VERSION "HNNBNNNYNNNNNNNNNNNNNNNNNNNNNNNNNNNNNNNNNN/4/%%%/4/'%**4NNN///"

NS_ :

BS_:

BU_: Airbag Allrad_Haldex BAP_Tester DCC_Gen3 EBKV_MQBW ESC_MQBW Gateway_Max Lenkhilfe_REPS

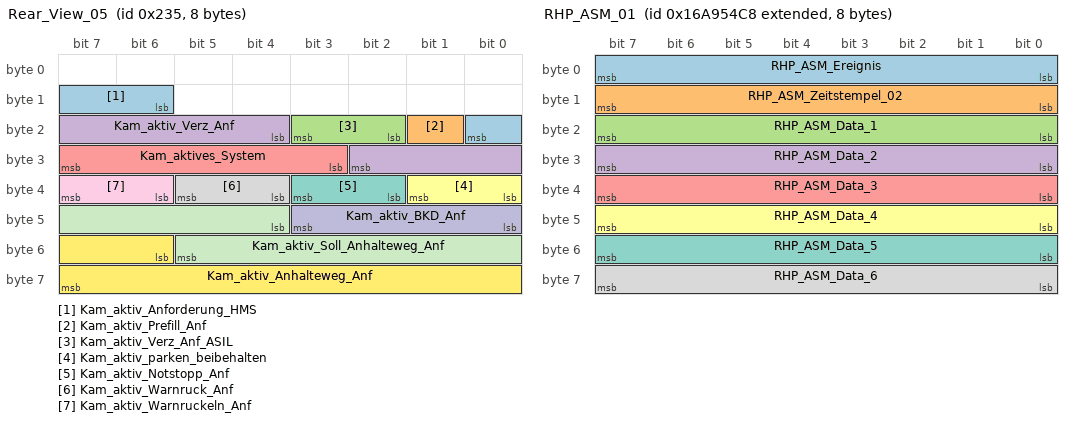
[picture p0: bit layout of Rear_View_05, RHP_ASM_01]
BO_ 565 Rear_View_05: 8 Gateway_Max
 SG_ Kam_aktiv_Anforderung_HMS : 14|3@1+ (1.0,0.0) [0.0|7] ""  Vector__XXX
 SG_ Kam_aktiv_Prefill_Anf : 17|1@1+ (1.0,0.0) [0.0|1] ""  Vector__XXX
 SG_ Kam_aktiv_Verz_Anf_ASIL : 18|2@1+ (1.0,0.0) [0.0|3] ""  ESC_MQBW
 SG_ Kam_aktiv_Verz_Anf : 20|7@1+ (0.1,-12.6) [-12.6|-0.1] "Unit_MeterPerSeconSquar"  ESC_MQBW
 SG_ Kam_aktives_System : 27|5@1+ (1.0,0.0) [0.0|31] ""  Vector__XXX
 SG_ Kam_aktiv_parken_beibehalten : 32|2@1+ (1.0,0.0) [0.0|3] ""  Vector__XXX
 SG_ Kam_aktiv_Notstopp_Anf : 34|2@1+ (1.0,0.0) [0.0|3] ""  Vector__XXX
 SG_ Kam_aktiv_Warnruck_Anf : 36|2@1+ (1.0,0.0) [0.0|3] ""  Vector__XXX
 SG_ Kam_aktiv_Warnruckeln_Anf : 38|2@1+ (1.0,0.0) [0.0|3] ""  Vector__XXX
 SG_ Kam_aktiv_BKD_Anf : 40|4@1+ (0.1,0) [0.0|1.3] "Unit_Secon"  Vector__XXX
 SG_ Kam_aktiv_Soll_Anhalteweg_Anf : 44|10@1+ (0.01,0) [0.00|10.21] "Unit_Meter"  Vector__XXX
 SG_ Kam_aktiv_Anhalteweg_Anf : 54|10@1+ (0.01,0) [0.00|10.21] "Unit_Meter"  Vector__XXX

BO_ 2033 Request_Airbag_Deployment: 8 Gateway_Max
 SG_ Request_Airbag_Deployment : 0|64@1+ (1.0,0.0) [0.0|18446744073709551615] ""  Airbag

BO_ 2041 Response_Airbag_Deployment: 8 Airbag
 SG_ Response_Airbag_Deployment : 0|64@1+ (1.0,0.0) [0.0|18446744073709551615] ""  Gateway_Max

BO_ 2264486920 RHP_01: 32 Gateway_Max
 SG_ RHP_01_CRC : 0|8@1+ (1,0) [0|255] ""  ESC_MQBW,Lenkhilfe_REPS
 SG_ RHP_01_BZ : 8|4@1+ (1,0) [0|15] ""  ESC_MQBW,Lenkhilfe_REPS
 SG_ RHP_QFK_AnfStat : 12|4@1+ (1.0,0.0) [0.0|15] ""  Lenkhilfe_REPS
 SG_ RHP_QFK_Spuerb : 16|8@1+ (0.4,0) [0.0|100.0] "Unit_PerCent"  Lenkhilfe_REPS
 SG_ RHP_QFK_KruemmSoll : 24|15@1+ (0.0000067,0) [0E-7|0.2195389] "Unit_MeterInver"  Lenkhilfe_REPS
 SG_ RHP_TV_Trigger : 39|1@1+ (1.0,0.0) [0.0|1] ""  Vector__XXX
 SG_ RHP_QFK_Signal1 : 40|10@1+ (1,0) [0|1023] ""  Lenkhilfe_REPS
 SG_ RHP_QFK_Art1 : 50|3@1+ (1,0) [0|7] ""  Lenkhilfe_REPS
 SG_ RHP_QFK_Art2 : 53|3@1+ (1,0) [0|7] ""  Lenkhilfe_REPS
 SG_ RHP_QFK_Signal2 : 56|10@1+ (1,0) [0|1023] ""  Lenkhilfe_REPS
 SG_ RHP_QFK_KruemmSoll_VZ : 66|1@1+ (1.0,0.0) [0.0|1] ""  Lenkhilfe_REPS
 SG_ RHP_Status_Long : 67|3@1+ (1.0,0.0) [0.0|7] ""  Vector__XXX
 SG_ RHP_Ruckfreigabe : 70|1@1+ (1.0,0.0) [0.0|1] ""  ESC_MQBW
 SG_ RHP_Warnruckeln_Anf : 71|3@1+ (1.0,0.0) [0.0|7] ""  ESC_MQBW
 SG_ RHP_Anf_ASIL : 74|3@1+ (1.0,0.0) [0.0|7] ""  ESC_MQBW
 SG_ RHP_Anforderung_HMS : 77|3@1+ (1.0,0.0) [0.0|7] ""  ESC_MQBW
 SG_ RHP_pos_Sollbeschl_Grad : 80|8@1+ (0.05,0) [0.00|12.75] "Unit_MeterPerCubicSecon"  Vector__XXX
 SG_ RHP_neg_Sollbeschl_Grad : 88|8@1+ (0.05,0) [0.00|12.75] "Unit_MeterPerCubicSecon"  Vector__XXX
 SG_ RHP_Sollbeschleunigung : 96|11@1+ (0.005,-7.22) [-7.220|3.005] "Unit_MeterPerSeconSquar"  Vector__XXX
 SG_ RHP_zul_Regelabw_oben : 107|5@1+ (0.0625,0) [0.0000|1.9375] "Unit_MeterPerSeconSquar"  Vector__XXX
 SG_ RHP_zul_Regelabw_unten : 112|6@1+ (0.024,0) [0.000|1.512] "Unit_MeterPerSeconSquar"  Vector__XXX
 SG_ RHP_TSK_Status : 118|3@1+ (1.0,0.0) [0.0|7] ""  Vector__XXX
 SG_ RHP_Minimale_Bremsung : 121|1@1+ (1.0,0.0) [0.0|1] ""  Vector__XXX
 SG_ RHP_Uss_Anforderung : 122|2@1+ (1.0,0.0) [0.0|3] ""  Vector__XXX
 SG_ RHP_Verz_Anf : 124|10@1+ (0.024,-20.016) [-20.016|4.512] "Unit_MeterPerSeconSquar"  ESC_MQBW
 SG_ RHP_Verz_Freigabe : 134|1@1+ (1.0,0.0) [0.0|1] ""  ESC_MQBW
 SG_ RHP_Status_Lat : 135|3@1+ (1.0,0.0) [0.0|7] ""  Vector__XXX
 SG_ RHP_StartStopp_Info : 138|2@1+ (1.0,0.0) [0.0|3] ""  Vector__XXX
 SG_ RHP_nachtr_Stopp_Anf : 140|1@1+ (1.0,0.0) [0.0|1] ""  Vector__XXX
 SG_ RHP_Freilaufstrategie_TSK : 141|1@1+ (1.0,0.0) [0.0|1] ""  Vector__XXX
 SG_ RHP_SCAM_HeatingRequest : 142|2@1+ (1.0,0.0) [0.0|3] ""  Vector__XXX
 SG_ RHP_Fahrzeughupe_Anf : 144|1@1+ (1.0,0.0) [0.0|1] ""  Vector__XXX
 SG_ RHP_HOS : 145|2@1+ (1.0,0.0) [0.0|3] ""  Vector__XXX
 SG_ RHP_Status_Function : 147|3@1+ (1.0,0.0) [0.0|7] ""  Vector__XXX
 SG_ RHP_EA_AnfStat : 150|2@1+ (1.0,0.0) [0.0|3] ""  Vector__XXX
 SG_ RHP_QFK_KrSoll : 152|16@1+ (0.0000067,0) [0E-7|0.4390845] "Unit_MeterInver"  Lenkhilfe_REPS
 SG_ RHP_QFK_KrSoll_VZ : 168|1@1+ (1.0,0.0) [0.0|1] ""  Lenkhilfe_REPS
 SG_ RHP_Warnblinken : 169|1@1+ (1.0,0.0) [0.0|1] ""  Vector__XXX
 SG_ RHP_Innenraumlicht_Anf : 170|1@1+ (1.0,0.0) [0.0|1] ""  Vector__XXX
 SG_ RHP_Spurwechsel_Ready : 171|3@1+ (1.0,0.0) [0.0|7] ""  Vector__XXX
 SG_ RHP_RBF_Available : 174|2@1+ (1.0,0.0) [0.0|3] ""  Vector__XXX
 SG_ RHP_PreCrash_Anf : 176|3@1+ (1.0,0.0) [0.0|7] ""  Airbag
 SG_ RHP_EA_PreCrash : 179|3@1+ (1.0,0.0) [0.0|7] ""  Vector__XXX
 SG_ RHP_Parking_St : 182|2@1+ (1.0,0.0) [0.0|3] ""  Vector__XXX
 SG_ RHP_EA_Innenraumlicht : 184|1@1+ (1.0,0.0) [0.0|1] ""  Vector__XXX
 SG_ RHP_EA_eCall : 185|1@1+ (1.0,0.0) [0.0|1] ""  Vector__XXX
 SG_ RHP_OPSEnable : 186|2@1+ (1.0,0.0) [0.0|3] ""  Vector__XXX
 SG_ RHP_eCall_Anf : 188|1@1+ (1.0,0.0) [0.0|1] ""  Vector__XXX
 SG_ RHP_EA_Tueren : 189|1@1+ (1.0,0.0) [0.0|1] ""  Vector__XXX

BO_ 2527679688 RHP_ASM_01: 8 Gateway_Max
 SG_ RHP_ASM_Ereignis : 0|8@1+ (1,0) [1|254] ""  Airbag
 SG_ RHP_ASM_Zeitstempel_02 : 8|8@1+ (0.04,0) [0.00|10.16] "Unit_Secon"  Airbag
 SG_ RHP_ASM_Data_1 : 16|8@1+ (1,0) [0|255] "Unit_None"  Airbag
 SG_ RHP_ASM_Data_2 : 24|8@1+ (1,0) [0|255] "Unit_None"  Airbag
 SG_ RHP_ASM_Data_3 : 32|8@1+ (1,0) [0|255] "Unit_None"  Airbag
 SG_ RHP_ASM_Data_4 : 40|8@1+ (1,0) [0|255] "Unit_None"  Airbag
 SG_ RHP_ASM_Data_5 : 48|8@1+ (1,0) [0|255] "Unit_None"  Airbag
 SG_ RHP_ASM_Data_6 : 56|8@1+ (1,0) [0|255] "Unit_None"  Airbag

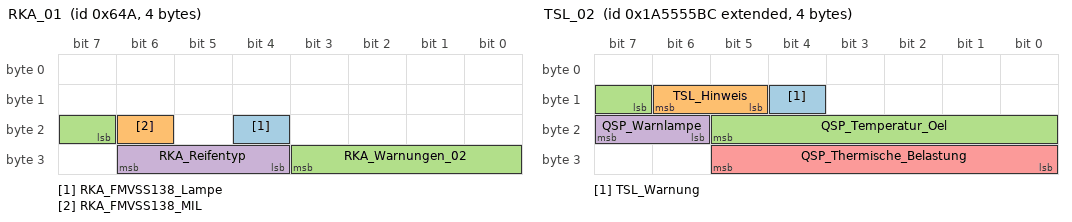
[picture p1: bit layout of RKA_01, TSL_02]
BO_ 1610 RKA_01: 4 ESC_MQBW
 SG_ RKA_FMVSS138_Lampe : 20|1@1+ (1.0,0.0) [0.0|1] ""  Airbag,Gateway_Max
 SG_ RKA_FMVSS138_MIL : 22|1@1+ (1,0) [0|1] ""  Airbag,Gateway_Max
 SG_ RKA_Warnungen_02 : 23|5@1+ (1.0,0.0) [0.0|31] ""  Gateway_Max
 SG_ RKA_Reifentyp : 28|3@1+ (1.0,0.0) [0.0|7] ""  Gateway_Max

BO_ 2589283756 SOK_NoAuthenticTime_01: 8 Gateway_Max
 SG_ SOK_ungeschuetzte_Zeit : 8|56@1+ (1,0) [1|72057594037927935] "Unit_None"  Airbag,EBKV_MQBW,ESC_MQBW

BO_ 2464153619 SOK_Zeit_ABS_Chal_01: 8 ESC_MQBW
 SG_ SOK_Zeit_ABS_Challenge : 0|64@1+ (1,0) [0|18446744073709551615] "Unit_None"  Gateway_Max

BO_ 2464284691 SOK_Zeit_ABS_Resp_01: 16 Gateway_Max
 SG_ SOK_Zeit_ABS_Zeit : 0|56@1+ (1,0) [0|72057594037927935] "Unit_None"  ESC_MQBW
 SG_ SOK_Zeit_ABS_Signatur : 64|64@1+ (1,0) [0|18446744073709551615] "Unit_None"  ESC_MQBW

BO_ 2464153621 SOK_Zeit_Airbag_Chal_01: 8 Airbag
 SG_ SOK_Zeit_Airbag_Challenge : 0|64@1+ (1,0) [0|18446744073709551615] "Unit_None"  Gateway_Max

BO_ 2464284693 SOK_Zeit_Airbag_Resp_01: 16 Gateway_Max
 SG_ SOK_Zeit_Airbag_Zeit : 0|56@1+ (1,0) [0|72057594037927935] "Unit_None"  Airbag
 SG_ SOK_Zeit_Airbag_Signatur : 64|64@1+ (1,0) [0|18446744073709551615] ""  Airbag

BO_ 2464153659 SOK_Zeit_EBKV_Chal_01: 8 EBKV_MQBW
 SG_ SOK_Zeit_EBKV_Challenge : 0|64@1+ (1,0) [0|18446744073709551615] "Unit_None"  Gateway_Max

BO_ 2464284731 SOK_Zeit_EBKV_Resp_01: 16 Gateway_Max
 SG_ SOK_Zeit_EBKV_Zeit : 0|56@1+ (1,0) [0|72057594037927935] "Unit_None"  EBKV_MQBW
 SG_ SOK_Zeit_EBKV_Signatur : 64|64@1+ (1,0) [0|18446744073709551615] ""  EBKV_MQBW

BO_ 1413 Systeminfo_01: 8 Gateway_Max
 SG_ SI_Sammel_SG_Fehler : 0|6@1+ (1,0) [0|60] ""  Vector__XXX
 SG_ SI_P_Mode_gueltig : 6|1@1+ (1.0,0.0) [0.0|1] ""  EBKV_MQBW,ESC_MQBW
 SG_ SI_Diagnose_Aktiv : 7|1@1+ (1.0,0.0) [0.0|1] ""  Vector__XXX
 SG_ SI_QRS_Mode : 8|1@1+ (1.0,0.0) [0.0|1] ""  Airbag
 SG_ SI_T_Mode : 9|1@1+ (1.0,0.0) [0.0|1] ""  ESC_MQBW
 SG_ SI_NWDF : 10|1@1+ (1.0,0.0) [0.0|1] ""  Allrad_Haldex,DCC_Gen3,Lenkhilfe_REPS
 SG_ SI_NWDF_gueltig : 11|1@1+ (1.0,0.0) [0.0|1] ""  Allrad_Haldex,DCC_Gen3,Lenkhilfe_REPS
 SG_ SI_Sammelfehler : 12|1@1+ (1.0,0.0) [0.0|1] ""  Vector__XXX
 SG_ GW_KD_Fehler : 13|1@1+ (1.0,0.0) [0.0|1] ""  Vector__XXX
 SG_ SI_T_Schutz : 14|1@1+ (1.0,0.0) [0.0|1] ""  ESC_MQBW
 SG_ SI_P_Mode : 15|1@1+ (1.0,0.0) [0.0|1] ""  EBKV_MQBW,ESC_MQBW
 SG_ SI_BUS_01 : 16|1@1+ (1.0,0.0) [0.0|1] ""  EBKV_MQBW
 SG_ SI_BUS_02 : 17|1@1+ (1.0,0.0) [0.0|1] ""  Vector__XXX
 SG_ SI_BUS_03 : 18|1@1+ (1.0,0.0) [0.0|1] ""  EBKV_MQBW
 SG_ SI_BUS_04 : 19|1@1+ (1.0,0.0) [0.0|1] ""  Vector__XXX
 SG_ SI_BUS_05 : 20|1@1+ (1.0,0.0) [0.0|1] ""  Vector__XXX
 SG_ SI_BUS_06 : 21|1@1+ (1.0,0.0) [0.0|1] ""  Vector__XXX
 SG_ SI_BUS_07 : 22|1@1+ (1.0,0.0) [0.0|1] ""  Vector__XXX
 SG_ SI_BUS_08 : 23|1@1+ (1.0,0.0) [0.0|1] ""  Vector__XXX
 SG_ SI_BUS_09 : 24|1@1+ (1.0,0.0) [0.0|1] ""  Vector__XXX
 SG_ SI_BUS_10 : 25|1@1+ (1.0,0.0) [0.0|1] ""  Vector__XXX
 SG_ SI_BUS_11 : 26|1@1+ (1.0,0.0) [0.0|1] ""  Vector__XXX
 SG_ SI_BUS_12 : 27|1@1+ (1.0,0.0) [0.0|1] ""  EBKV_MQBW
 SG_ SI_BUS_13 : 28|1@1+ (1.0,0.0) [0.0|1] ""  Vector__XXX
 SG_ SI_BUS_14 : 29|1@1+ (1.0,0.0) [0.0|1] ""  Vector__XXX
 SG_ SI_BUS_15 : 30|1@1+ (1.0,0.0) [0.0|1] ""  Vector__XXX
 SG_ SI_NWDF_30 : 31|1@1+ (1.0,0.0) [0.0|1] ""  Vector__XXX
 SG_ SI_Bus_Identifikation : 32|8@1+ (1.0,0.0) [0.0|255] ""  Vector__XXX
 SG_ SI_CAB_V14 : 40|24@1+ (1.0,0.0) [0.0|16777215] ""  Vector__XXX

BO_ 165 TimeSync_01: 16 Gateway_Max
 SG_ TS_CAN_Ma_Type : 0|8@1+ (1.0,0.0) [0.0|255] ""  Airbag
 SG_ TS_CAN_Ma_CRC : 8|8@1+ (1,0) [0|255] ""  Airbag
 SG_ TS_CAN_Ma_SequenceCounter : 16|4@1+ (1,0) [0|15] ""  Airbag
 SG_ TS_CAN_Ma_TimeDomain : 20|4@1+ (1,0) [0|15] ""  Airbag
 SG_ TS_CAN_Ma_OVS : 24|2@1+ (1,0) [0|3] ""  Airbag
 SG_ TS_CAN_Ma_SGW : 26|1@1+ (1.0,0.0) [0.0|1] ""  Airbag
 SG_ TS_CAN_Ma_SyncTimeSec : 39|32@0+ (1,0) [0|4294967295] ""  Airbag

BO_ 1447 TM_01: 8 Gateway_Max
 SG_ ORU_KombiTimer : 20|2@1+ (1.0,0.0) [0.0|3] ""  Vector__XXX
 SG_ MOD_Energie_Anf : 22|2@1+ (1.0,0.0) [0.0|3] ""  Vector__XXX
 SG_ FaceRec_Enroll_Challenge_Request : 24|1@1+ (1.0,0.0) [0.0|1] ""  Vector__XXX
 SG_ eCall_Mute_Anf : 25|1@1+ (1.0,0.0) [0.0|1] ""  Vector__XXX
 SG_ eCall_MCC : 26|10@1+ (1,0) [0|999] "Unit_None"  Vector__XXX
 SG_ FoD_Anz_Funktionsabschaltung : 36|2@1+ (1.0,0.0) [0.0|3] ""  Vector__XXX
 SG_ iCall_active : 38|1@1+ (1.0,0.0) [0.0|1] ""  Vector__XXX
 SG_ bCall_active : 39|1@1+ (1.0,0.0) [0.0|1] ""  Vector__XXX
 SG_ MOD_Request_ServiceKey : 40|1@1+ (1.0,0.0) [0.0|1] ""  Vector__XXX
 SG_ eCall_Funktionsstatus_02 : 41|3@1+ (1.0,0.0) [0.0|7] ""  Vector__XXX
 SG_ eCall_Funktionsstatus : 44|3@1+ (1.0,0.0) [0.0|7] ""  Airbag
 SG_ TM_Spiegel_Anklappen : 47|1@1+ (1.0,0.0) [0.0|1] ""  Vector__XXX
 SG_ TM_Nur_Hupen : 48|1@1+ (1.0,0.0) [0.0|1] ""  Vector__XXX
 SG_ TM_Door_Lock : 49|1@1+ (1.0,0.0) [0.0|1] ""  Vector__XXX
 SG_ TM_Door_Unlock : 50|1@1+ (1.0,0.0) [0.0|1] ""  Vector__XXX
 SG_ TM_Warnblinken : 51|1@1+ (1.0,0.0) [0.0|1] ""  Vector__XXX
 SG_ TM_Panik_Alarm : 52|1@1+ (1.0,0.0) [0.0|1] ""  Vector__XXX
 SG_ TM_ZV_Signatur : 53|11@1+ (1,0) [1|2047] "Unit_None"  Vector__XXX

BO_ 997 TSG_FT_02: 8 Gateway_Max
 SG_ TSG_FT_02_CRC : 0|8@1+ (1,0) [0|255] ""  ESC_MQBW
 SG_ TSG_FT_02_BZ : 8|4@1+ (1,0) [0|15] ""  ESC_MQBW
 SG_ FT_Tuer_Status : 12|2@1+ (1.0,0.0) [0.0|3] ""  ESC_MQBW
 SG_ FT_Tuer_Status_QBit : 14|1@1+ (1.0,0.0) [0.0|1] ""  ESC_MQBW
 SG_ FT_Lock_Taster_02 : 15|1@1+ (1.0,0.0) [0.0|1] ""  Vector__XXX
 SG_ FT_Schluesselschalter_zu_02 : 16|1@1+ (1.0,0.0) [0.0|1] ""  Vector__XXX
 SG_ FT_BFS_Tuer_Status : 17|2@1+ (1.0,0.0) [0.0|3] ""  Vector__XXX
 SG_ FT_HBFS_Tuer_Status : 19|2@1+ (1.0,0.0) [0.0|3] ""  Vector__XXX
 SG_ FT_HFS_Tuer_Status : 21|2@1+ (1.0,0.0) [0.0|3] ""  Vector__XXX
 SG_ FT_Tueroeffnen_Warnung : 23|1@1+ (1.0,0.0) [0.0|1] ""  Vector__XXX
 SG_ FT_SP_Heizung_ein : 24|1@1+ (1.0,0.0) [0.0|1] ""  Vector__XXX
 SG_ FT_Kisi_Taster_li_02 : 25|1@1+ (1.0,0.0) [0.0|1] ""  Vector__XXX
 SG_ FT_Kisi_Taster_re_02 : 26|1@1+ (1.0,0.0) [0.0|1] ""  Vector__XXX
 SG_ FT_TD_Taste_Status : 27|2@1+ (1.0,0.0) [0.0|3] ""  Vector__XXX
 SG_ FT_TCR_Mode_aktiv : 29|1@1+ (1.0,0.0) [0.0|1] ""  Vector__XXX
 SG_ TBF_FS_Touch_Event : 30|4@1+ (1.0,0.0) [0.0|15] ""  Vector__XXX
 SG_ FT_KiSi_Status_Soll_HBFS : 34|1@1+ (1.0,0.0) [0.0|1] ""  Vector__XXX
 SG_ FT_KiSi_Status_Soll_HFS : 35|1@1+ (1.0,0.0) [0.0|1] ""  Vector__XXX
 SG_ FS_Push_Tuergriff : 36|1@1+ (1.0,0.0) [0.0|1] ""  Vector__XXX
 SG_ TSG_FS_Spiegel_angeklappt : 37|1@1+ (1.0,0.0) [0.0|1] ""  Vector__XXX
 SG_ FT_Cargolock_bet : 38|1@1+ (1.0,0.0) [0.0|1] ""  Vector__XXX
 SG_ FT_kisi_asynchron : 40|1@1+ (1.0,0.0) [0.0|1] ""  Vector__XXX
 SG_ eTAB_FS_Bowdenzug_Auswerfen : 41|1@1+ (1.0,0.0) [0.0|1] ""  Vector__XXX
 SG_ FS_Status_eTAG_ext : 42|3@1+ (1.0,0.0) [0.0|7] ""  Vector__XXX
 SG_ FT_ASW_Warnton : 45|2@1+ (1.0,0.0) [0.0|3] ""  Vector__XXX
 SG_ SSA_FT_ASW_Status : 47|2@1+ (1.0,0.0) [0.0|3] ""  Vector__XXX

BO_ 2589283772 TSL_02: 4 Vector__XXX
 SG_ TSL_Warnung : 12|1@1+ (1.0,0.0) [0.0|1] ""  Gateway_Max
 SG_ TSL_Hinweis : 13|2@1+ (1.0,0.0) [0.0|3] ""  Gateway_Max
 SG_ QSP_Temperatur_Oel : 15|7@1+ (2,-40) [-40|210] "Unit_DegreCelsi"  Gateway_Max
 SG_ QSP_Warnlampe : 22|2@1+ (1.0,0.0) [0.0|3] ""  Gateway_Max
 SG_ QSP_Thermische_Belastung : 24|6@1+ (2,0) [0|100] "Unit_PerCent"  Gateway_Max

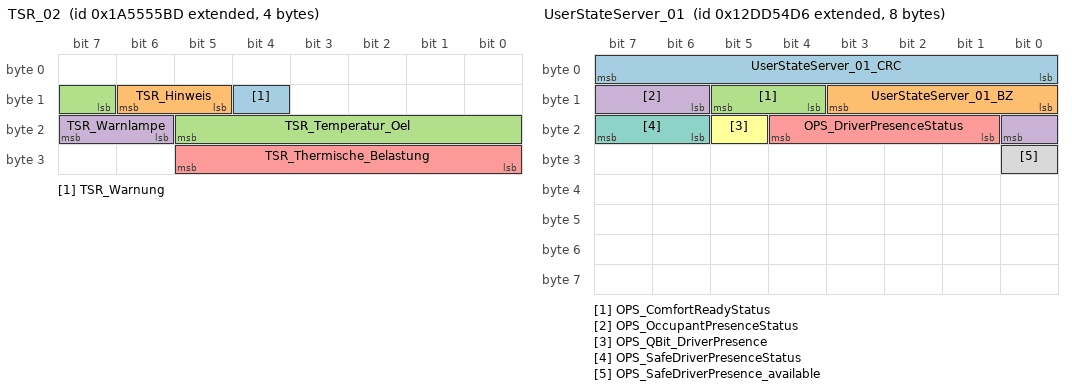
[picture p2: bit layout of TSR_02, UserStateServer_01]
BO_ 2589283773 TSR_02: 4 Vector__XXX
 SG_ TSR_Warnung : 12|1@1+ (1.0,0.0) [0.0|1] ""  Gateway_Max
 SG_ TSR_Hinweis : 13|2@1+ (1.0,0.0) [0.0|3] ""  Gateway_Max
 SG_ TSR_Temperatur_Oel : 15|7@1+ (2,-40) [-40|210] "Unit_DegreCelsi"  Gateway_Max
 SG_ TSR_Warnlampe : 22|2@1+ (1.0,0.0) [0.0|3] ""  Gateway_Max
 SG_ TSR_Thermische_Belastung : 24|6@1+ (2,0) [0|100] "Unit_PerCent"  Gateway_Max

BO_ 2463978710 UserStateServer_01: 8 Gateway_Max
 SG_ UserStateServer_01_CRC : 0|8@1+ (1,0) [0|255] ""  ESC_MQBW
 SG_ UserStateServer_01_BZ : 8|4@1+ (1,0) [0|15] ""  ESC_MQBW
 SG_ OPS_ComfortReadyStatus : 12|2@1+ (1.0,0.0) [0.0|3] ""  Vector__XXX
 SG_ OPS_OccupantPresenceStatus : 14|3@1+ (1.0,0.0) [0.0|7] ""  Vector__XXX
 SG_ OPS_DriverPresenceStatus : 17|4@1+ (1.0,0.0) [0.0|15] ""  ESC_MQBW
 SG_ OPS_QBit_DriverPresence : 21|1@1+ (1.0,0.0) [0.0|1] ""  ESC_MQBW
 SG_ OPS_SafeDriverPresenceStatus : 22|2@1+ (1.0,0.0) [0.0|3] ""  ESC_MQBW
 SG_ OPS_SafeDriverPresence_available : 24|1@1+ (1.0,0.0) [0.0|1] ""  ESC_MQBW

BO_ 995 Verdeck_01: 8 Gateway_Max
 SG_ VS_VD_zu_ver : 16|1@1+ (1.0,0.0) [0.0|1] ""  Vector__XXX
 SG_ VS_VD_entriegelt : 17|1@1+ (1.0,0.0) [0.0|1] ""  Vector__XXX
 SG_ VS_VD_offen_ver : 18|1@1+ (1.0,0.0) [0.0|1] ""  Airbag
 SG_ VS_VD_Zwischenposition : 19|1@1+ (1.0,0.0) [0.0|1] ""  Vector__XXX
 SG_ VS_VD_Bew_auf : 20|1@1+ (1.0,0.0) [0.0|1] ""  Vector__XXX
 SG_ VS_VD_Bew_zu : 21|1@1+ (1.0,0.0) [0.0|1] ""  Vector__XXX
 SG_ VS_Verdeck_Anf : 22|1@1+ (1.0,0.0) [0.0|1] ""  Vector__XXX
 SG_ VS_Hardtop : 23|1@1+ (1.0,0.0) [0.0|1] ""  Vector__XXX
 SG_ VS_VD_Fehler : 24|1@1+ (1.0,0.0) [0.0|1] ""  Vector__XXX
 SG_ VS_Lampe_Blk : 25|1@1+ (1.0,0.0) [0.0|1] ""  Vector__XXX
 SG_ VS_Buzzer : 26|1@1+ (1.0,0.0) [0.0|1] ""  Vector__XXX
 SG_ VS_HD_sperren : 27|1@1+ (1.0,0.0) [0.0|1] ""  Vector__XXX
 SG_ VS_HHS_enable : 28|1@1+ (1.0,0.0) [0.0|1] ""  Vector__XXX
 SG_ VD_SpannungsAnf : 29|2@1+ (1.0,0.0) [0.0|3] ""  Vector__XXX
 SG_ VS_VDKD_auf : 31|1@1+ (1.0,0.0) [0.0|1] ""  Vector__XXX
 SG_ VS_FS_AutoHoch : 32|1@1+ (1.0,0.0) [0.0|1] ""  Vector__XXX
 SG_ VS_FS_AutoTief : 33|1@1+ (1.0,0.0) [0.0|1] ""  Vector__XXX
 SG_ VS_FS_ManHoch : 34|1@1+ (1.0,0.0) [0.0|1] ""  Vector__XXX
 SG_ VS_FS_ManTief : 35|1@1+ (1.0,0.0) [0.0|1] ""  Vector__XXX
 SG_ VS_BFS_AutoHoch : 36|1@1+ (1.0,0.0) [0.0|1] ""  Vector__XXX
 SG_ VS_BFS_AutoTief : 37|1@1+ (1.0,0.0) [0.0|1] ""  Vector__XXX
 SG_ VS_BFS_ManHoch : 38|1@1+ (1.0,0.0) [0.0|1] ""  Vector__XXX
 SG_ VS_BFS_ManTief : 39|1@1+ (1.0,0.0) [0.0|1] ""  Vector__XXX
 SG_ VS_HFS_AutoHoch : 40|1@1+ (1.0,0.0) [0.0|1] ""  Vector__XXX
 SG_ VS_HFS_AutoTief : 41|1@1+ (1.0,0.0) [0.0|1] ""  Vector__XXX
 SG_ VS_HFS_ManHoch : 42|1@1+ (1.0,0.0) [0.0|1] ""  Vector__XXX
 SG_ VS_HFS_ManTief : 43|1@1+ (1.0,0.0) [0.0|1] ""  Vector__XXX
 SG_ VS_HBFS_AutoHoch : 44|1@1+ (1.0,0.0) [0.0|1] ""  Vector__XXX
 SG_ VS_HBFS_AutoTief : 45|1@1+ (1.0,0.0) [0.0|1] ""  Vector__XXX
 SG_ VS_HBFS_ManHoch : 46|1@1+ (1.0,0.0) [0.0|1] ""  Vector__XXX
 SG_ VS_HBFS_ManTief : 47|1@1+ (1.0,0.0) [0.0|1] ""  Vector__XXX
 SG_ VS_FH_FT_Langhub : 49|1@1+ (1.0,0.0) [0.0|1] ""  Vector__XXX
 SG_ VS_Windschott_nicht_abgelegt : 50|1@1+ (1.0,0.0) [0.0|1] ""  Vector__XXX
 SG_ VS_FH_BT_Langhub : 51|1@1+ (1.0,0.0) [0.0|1] ""  Vector__XXX
 SG_ VS_FH_HFS_Langhub : 53|1@1+ (1.0,0.0) [0.0|1] ""  Vector__XXX
 SG_ VS_Heckschloss_auf : 54|1@1+ (1.0,0.0) [0.0|1] ""  Vector__XXX
 SG_ VS_FH_HBFS_Langhub : 55|1@1+ (1.0,0.0) [0.0|1] ""  Vector__XXX
 SG_ VSG_Meldungen : 56|6@1+ (1,0) [1|63] "Unit_None"  Vector__XXX
 SG_ VS_StartStopp_Info : 62|2@1+ (1.0,0.0) [0.0|3] ""  Vector__XXX

BO_ 1716 VIN_01: 8 Gateway_Max
 SG_ VIN_01_MUX M  : 0|2@1+ (1,0) [0|3] ""  Airbag,DCC_Gen3,EBKV_MQBW,ESC_MQBW,Lenkhilfe_REPS
 SG_ KS_Geheimnis_1 m0  : 8|8@1+ (1,0) [0|255] ""  Vector__XXX
 SG_ VIN_4 m1  : 8|8@1+ (1,0) [0|255] ""  Airbag,DCC_Gen3,EBKV_MQBW,ESC_MQBW,Lenkhilfe_REPS
 SG_ VIN_11 m2  : 8|8@1+ (1,0) [0|255] ""  Airbag,DCC_Gen3,EBKV_MQBW,ESC_MQBW,Lenkhilfe_REPS
 SG_ KS_Geheimnis_2 m0  : 16|8@1+ (1,0) [0|255] ""  Vector__XXX
 SG_ VIN_5 m1  : 16|8@1+ (1,0) [0|255] ""  Airbag,DCC_Gen3,EBKV_MQBW,ESC_MQBW,Lenkhilfe_REPS
 SG_ VIN_12 m2  : 16|8@1+ (1,0) [0|255] ""  Airbag,DCC_Gen3,EBKV_MQBW,ESC_MQBW,Lenkhilfe_REPS
 SG_ KS_Geheimnis_3 m0  : 24|8@1+ (1,0) [0|255] ""  Vector__XXX
 SG_ VIN_6 m1  : 24|8@1+ (1,0) [0|255] ""  Airbag,DCC_Gen3,EBKV_MQBW,ESC_MQBW,Lenkhilfe_REPS
 SG_ VIN_13 m2  : 24|8@1+ (1,0) [0|255] ""  Airbag,DCC_Gen3,EBKV_MQBW,ESC_MQBW,Lenkhilfe_REPS
 SG_ KS_Geheimnis_4 m0  : 32|8@1+ (1,0) [0|255] ""  Vector__XXX
 SG_ VIN_7 m1  : 32|8@1+ (1,0) [0|255] ""  Airbag,DCC_Gen3,EBKV_MQBW,ESC_MQBW,Lenkhilfe_REPS
 SG_ VIN_14 m2  : 32|8@1+ (1,0) [0|255] ""  Airbag,DCC_Gen3,EBKV_MQBW,ESC_MQBW,Lenkhilfe_REPS
 SG_ VIN_1 m0  : 40|8@1+ (1,0) [0|255] ""  Airbag,DCC_Gen3,EBKV_MQBW,ESC_MQBW,Lenkhilfe_REPS
 SG_ VIN_8 m1  : 40|8@1+ (1,0) [0|255] ""  Airbag,DCC_Gen3,EBKV_MQBW,ESC_MQBW,Lenkhilfe_REPS
 SG_ VIN_15 m2  : 40|8@1+ (1,0) [0|255] ""  Airbag,DCC_Gen3,EBKV_MQBW,ESC_MQBW,Lenkhilfe_REPS
 SG_ VIN_2 m0  : 48|8@1+ (1,0) [0|255] ""  Airbag,DCC_Gen3,EBKV_MQBW,ESC_MQBW,Lenkhilfe_REPS
 SG_ VIN_9 m1  : 48|8@1+ (1,0) [0|255] ""  Airbag,DCC_Gen3,EBKV_MQBW,ESC_MQBW,Lenkhilfe_REPS
 SG_ VIN_16 m2  : 48|8@1+ (1,0) [0|255] ""  Airbag,DCC_Gen3,EBKV_MQBW,ESC_MQBW,Lenkhilfe_REPS
 SG_ VIN_3 m0  : 56|8@1+ (1,0) [0|255] ""  Airbag,DCC_Gen3,EBKV_MQBW,ESC_MQBW,Lenkhilfe_REPS
 SG_ VIN_10 m1  : 56|8@1+ (1,0) [0|255] ""  Airbag,DCC_Gen3,EBKV_MQBW,ESC_MQBW,Lenkhilfe_REPS
 SG_ VIN_17 m2  : 56|8@1+ (1,0) [0|255] ""  Airbag,DCC_Gen3,EBKV_MQBW,ESC_MQBW,Lenkhilfe_REPS

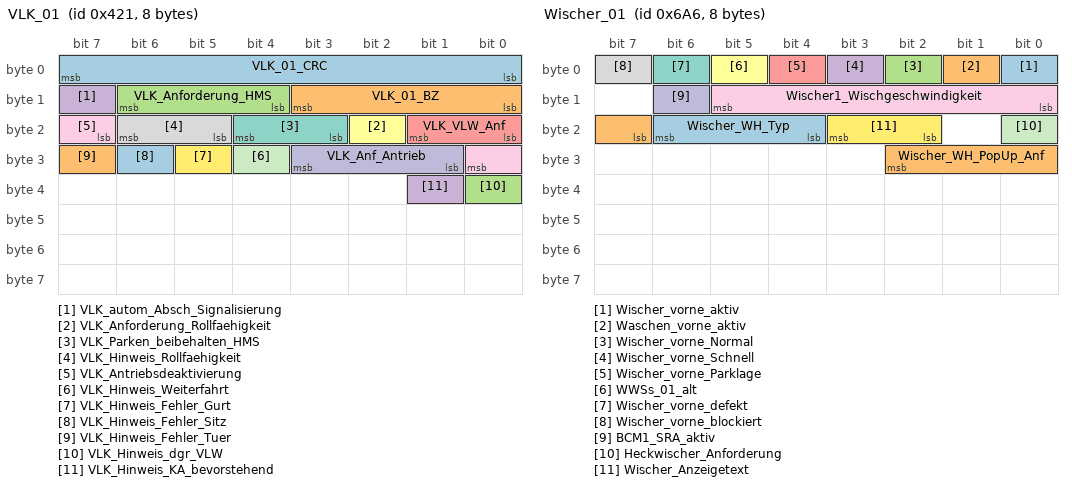
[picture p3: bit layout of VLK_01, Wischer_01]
BO_ 1057 VLK_01: 8 Gateway_Max
 SG_ VLK_01_CRC : 0|8@1+ (1,0) [0|255] ""  ESC_MQBW
 SG_ VLK_01_BZ : 8|4@1+ (1,0) [0|15] ""  ESC_MQBW
 SG_ VLK_Anforderung_HMS : 12|3@1+ (1.0,0.0) [0.0|7] ""  ESC_MQBW
 SG_ VLK_autom_Absch_Signalisierung : 15|1@1+ (1.0,0.0) [0.0|1] ""  Vector__XXX
 SG_ VLK_VLW_Anf : 16|2@1+ (1.0,0.0) [0.0|3] ""  Vector__XXX
 SG_ VLK_Anforderung_Rollfaehigkeit : 18|1@1+ (1.0,0.0) [0.0|1] ""  ESC_MQBW
 SG_ VLK_Parken_beibehalten_HMS : 19|2@1+ (1.0,0.0) [0.0|3] ""  Vector__XXX
 SG_ VLK_Hinweis_Rollfaehigkeit : 21|2@1+ (1.0,0.0) [0.0|3] ""  Vector__XXX
 SG_ VLK_Antriebsdeaktivierung : 23|2@1+ (1.0,0.0) [0.0|3] ""  Vector__XXX
 SG_ VLK_Anf_Antrieb : 25|3@1+ (1.0,0.0) [0.0|7] ""  Vector__XXX
 SG_ VLK_Hinweis_Weiterfahrt : 28|1@1+ (1.0,0.0) [0.0|1] ""  Vector__XXX
 SG_ VLK_Hinweis_Fehler_Gurt : 29|1@1+ (1.0,0.0) [0.0|1] ""  Vector__XXX
 SG_ VLK_Hinweis_Fehler_Sitz : 30|1@1+ (1.0,0.0) [0.0|1] ""  Vector__XXX
 SG_ VLK_Hinweis_Fehler_Tuer : 31|1@1+ (1.0,0.0) [0.0|1] ""  Vector__XXX
 SG_ VLK_Hinweis_dgr_VLW : 32|1@1+ (1.0,0.0) [0.0|1] ""  Vector__XXX
 SG_ VLK_Hinweis_KA_bevorstehend : 33|1@1+ (1.0,0.0) [0.0|1] ""  Vector__XXX

BO_ 313 VMM_02_Auth: 32 ESC_MQBW
 SG_ VMM_02_CRC : 0|8@1+ (1,0) [0|255] ""  EBKV_MQBW,Gateway_Max
 SG_ VMM_02_BZ : 8|4@1+ (1,0) [0|15] ""  EBKV_MQBW,Gateway_Max
 SG_ VZM_aktiver_Basisservice : 12|3@1+ (1.0,0.0) [0.0|7] ""  Gateway_Max
 SG_ VZM_Anhalteweg_nicht_verfuegbar : 15|1@1+ (1.0,0.0) [0.0|1] ""  Gateway_Max
 SG_ VZM_Fahrer_bremst : 16|1@1+ (1.0,0.0) [0.0|1] ""  Gateway_Max
 SG_ VZM_QBit_Fahrer_bremst : 17|1@1+ (1.0,0.0) [0.0|1] ""  Gateway_Max
 SG_ VMM_MKB_codiert : 18|1@1+ (1.0,0.0) [0.0|1] ""  Airbag,Gateway_Max
 SG_ VMM_Inkonsistenz_EBKV : 19|1@1+ (1.0,0.0) [0.0|1] ""  EBKV_MQBW,Gateway_Max
 SG_ VMM_Notstopp_Status : 20|3@1+ (1.0,0.0) [0.0|7] ""  EBKV_MQBW,Gateway_Max
 SG_ VZM_Warnruck_nicht_verfuegbar : 23|1@1+ (1.0,0.0) [0.0|1] ""  Gateway_Max
 SG_ VZM_Warnruckeln_nicht_verfuegbar : 24|1@1+ (1.0,0.0) [0.0|1] ""  Gateway_Max
 SG_ VZM_Bkd_nicht_verfuegbar : 25|1@1+ (1.0,0.0) [0.0|1] ""  Gateway_Max
 SG_ VMM_Bremslicht_defekt : 26|1@1+ (1.0,0.0) [0.0|1] ""  Gateway_Max
 SG_ VZM_Fahrer_bremst_deutlich : 27|1@1+ (1.0,0.0) [0.0|1] ""  Airbag,Gateway_Max
 SG_ VZM_TSK_SRBM_Anf : 28|1@1+ (1.0,0.0) [0.0|1] ""  Gateway_Max
 SG_ VZM_TSK_SRBM_nicht_verfuegbar : 29|1@1+ (1.0,0.0) [0.0|1] ""  Gateway_Max
 SG_ VZM_Verz_Reg_aktiv : 30|5@1+ (1.0,0.0) [0.0|31] ""  Gateway_Max
 SG_ VZM_Verz_Reg_nicht_verfuegbar : 35|1@1+ (1.0,0.0) [0.0|1] ""  Gateway_Max
 SG_ VMM_Inkonsistenz_KAS : 36|1@1+ (1.0,0.0) [0.0|1] ""  Gateway_Max
 SG_ VMM_Bremslicht_unplausibel : 37|1@1+ (1.0,0.0) [0.0|1] ""  Gateway_Max
 SG_ VMM_Inkonsistenz_ACC : 38|1@1+ (1.0,0.0) [0.0|1] ""  Gateway_Max
 SG_ VMM_Inkonsistenz_AWV_PCF : 39|1@1+ (1.0,0.0) [0.0|1] ""  Gateway_Max
 SG_ VMM_Inkonsistenz_ARA : 40|1@1+ (1.0,0.0) [0.0|1] ""  Gateway_Max
 SG_ VMM_Inkonsistenz_ParkAssist : 41|1@1+ (1.0,0.0) [0.0|1] ""  Gateway_Max
 SG_ VMM_Inkonsistenz_FAS_VK : 42|1@1+ (1.0,0.0) [0.0|1] ""  Gateway_Max
 SG_ VMM_Inkonsistenz_NV : 43|1@1+ (1.0,0.0) [0.0|1] ""  Gateway_Max
 SG_ VMM_Inkonsistenz_RCTA : 44|1@1+ (1.0,0.0) [0.0|1] ""  Gateway_Max
 SG_ VMM_Inkonsistenz_TSK : 45|1@1+ (1.0,0.0) [0.0|1] ""  Gateway_Max
 SG_ VMM_Inkonsistenz_MO : 46|1@1+ (1.0,0.0) [0.0|1] ""  Gateway_Max
 SG_ VMM_Inkonsistenz_AEB : 47|1@1+ (1.0,0.0) [0.0|1] ""  Gateway_Max
 SG_ VMM_Fahrer_Bremskraft_bestimmend : 48|1@1+ (1.0,0.0) [0.0|1] ""  Gateway_Max
 SG_ VMM_Inkonsistenz_EA : 49|1@1+ (1.0,0.0) [0.0|1] ""  Gateway_Max
 SG_ VZM_Status_Wegregelung : 50|2@1+ (1.0,0.0) [0.0|3] ""  Gateway_Max
 SG_ VZM_Verz_ASIL_Verfuegbarkeit : 52|3@1+ (1.0,0.0) [0.0|7] ""  Gateway_Max
 SG_ VZM_aktives_System : 55|5@1+ (1.0,0.0) [0.0|31] ""  Airbag,Gateway_Max
 SG_ VZM_Verz_Begrenzung : 60|1@1+ (1.0,0.0) [0.0|1] ""  Gateway_Max
 SG_ VZM_Systemstatus : 61|3@1+ (1.0,0.0) [0.0|7] ""  Gateway_Max
 SG_ VZM_SRBM_Soll : 64|12@1+ (8,0) [0|32744] "Unit_NewtoMeter"  DCC_Gen3,Gateway_Max
 SG_ VZM_SRBM_Ist : 76|12@1+ (8,0) [0|32744] "Unit_NewtoMeter"  DCC_Gen3,Gateway_Max
 SG_ VZM_SRBM_max_Gradient : 88|7@1+ (50,0) [0|6250] "Unit_NewtoMeterPerSecon"  Gateway_Max
 SG_ VMM_Inkonsistenz_KAM : 95|1@1+ (1.0,0.0) [0.0|1] ""  Gateway_Max
 SG_ VMM_Inkonsistenz_RHP : 96|1@1+ (1.0,0.0) [0.0|1] ""  Gateway_Max
 SG_ HMS_P_beibehalten_GE : 172|2@1+ (1.0,0.0) [0.0|3] ""  Gateway_Max
 SG_ VZM_Unterdrueckung_Antriebsmom : 174|1@1+ (1.0,0.0) [0.0|1] ""  Airbag,Gateway_Max
 SG_ VMM_Inkonsistenz_VLK : 175|1@1+ (1.0,0.0) [0.0|1] ""  Gateway_Max
 SG_ HMS_halten_nicht_verfuegbar_02 : 176|2@1+ (1.0,0.0) [0.0|3] ""  Gateway_Max
 SG_ HMS_halten_nicht_verfuegbar : 180|1@1+ (1.0,0.0) [0.0|1] ""  Gateway_Max
 SG_ HMS_parken_nicht_verfuegbar : 192|1@1+ (1.0,0.0) [0.0|1] ""  EBKV_MQBW,Gateway_Max
 SG_ HMS_Anforderung_GE : 193|3@1+ (1.0,0.0) [0.0|7] ""  Gateway_Max
 SG_ HMS_Systemstatus : 196|4@1+ (1.0,0.0) [0.0|15] ""  EBKV_MQBW,Gateway_Max
 SG_ HMS_Stillstand : 200|3@1+ (1.0,0.0) [0.0|7] ""  EBKV_MQBW,Gateway_Max
 SG_ HMS_aktives_System : 203|5@1+ (1.0,0.0) [0.0|31] ""  EBKV_MQBW,Gateway_Max
 SG_ VMM_Inkonsistenz_GE : 208|1@1+ (1.0,0.0) [0.0|1] ""  Gateway_Max
 SG_ VMM_Inkonsistenz_HVLM : 209|1@1+ (1.0,0.0) [0.0|1] ""  Gateway_Max
 SG_ HMS_Fehlerstatus : 210|3@1+ (1.0,0.0) [0.0|7] ""  EBKV_MQBW,Gateway_Max
 SG_ HMS_Index_Haltemoment : 213|1@1+ (1.0,0.0) [0.0|1] ""  Gateway_Max
 SG_ HMS_Haltemoment : 214|10@1+ (10,0) [0|10210] "Unit_NewtoMeter"  Gateway_Max
 SG_ SOK_VMM_02_Signatur : 224|32@1+ (1,0) [0|4294967295] ""  Gateway_Max

BO_ 1702 Wischer_01: 8 Gateway_Max
 SG_ Wischer_vorne_aktiv : 0|1@1+ (1.0,0.0) [0.0|1] ""  ESC_MQBW
 SG_ Waschen_vorne_aktiv : 1|1@1+ (1.0,0.0) [0.0|1] ""  Vector__XXX
 SG_ Wischer_vorne_Normal : 2|1@1+ (1.0,0.0) [0.0|1] ""  Vector__XXX
 SG_ Wischer_vorne_Schnell : 3|1@1+ (1.0,0.0) [0.0|1] ""  Vector__XXX
 SG_ Wischer_vorne_Parklage : 4|1@1+ (1.0,0.0) [0.0|1] ""  ESC_MQBW
 SG_ WWSs_01_alt : 5|1@1+ (1.0,0.0) [0.0|1] ""  Vector__XXX
 SG_ Wischer_vorne_defekt : 6|1@1+ (1.0,0.0) [0.0|1] ""  Vector__XXX
 SG_ Wischer_vorne_blockiert : 7|1@1+ (1.0,0.0) [0.0|1] ""  Vector__XXX
 SG_ Wischer1_Wischgeschwindigkeit : 8|6@1+ (1,9) [10|70] "Unit_MinutInver"  Vector__XXX
 SG_ BCM1_SRA_aktiv : 14|1@1+ (1.0,0.0) [0.0|1] ""  Vector__XXX
 SG_ Heckwischer_Anforderung : 16|1@1+ (1.0,0.0) [0.0|1] ""  Vector__XXX
 SG_ Wischer_Anzeigetext : 18|2@1+ (1.0,0.0) [0.0|3] ""  Vector__XXX
 SG_ Wischer_WH_Typ : 20|3@1+ (1.0,0.0) [0.0|7] ""  Vector__XXX
 SG_ Wischer_WH_PopUp_Anf : 23|4@1+ (1.0,0.0) [0.0|15] ""  Vector__XXX

BO_ 2617028096 XCP_Airbag_CRO_01: 64 Vector__XXX
 SG_ XCP_Airbag_CRO_01_Data : 0|512@1+ (1.0,0.0) [0.0|13407807929942597099574024998205846127479365820592393377723561443721764030073546976801874298166903427690031858186486050853753882811946569946433649006084095] ""  Airbag

BO_ 2617028097 XCP_Airbag_DTO_01: 64 Airbag
 SG_ XCP_Airbag_DTO_01_Data : 0|512@1+ (1.0,0.0) [0.0|13407807929942597099574024998205846127479365820592393377723561443721764030073546976801874298166903427690031858186486050853753882811946569946433649006084095] ""  Vector__XXX

BO_ 2617218560 XCP_Daempfer_CRO_01: 8 Vector__XXX
 SG_ XCP_Daempfer_CRO_01_Data : 0|64@1+ (1.0,0.0) [0.0|18446744073709551615] ""  DCC_Gen3

BO_ 2617218562 XCP_Daempfer_CRO_02: 64 Vector__XXX
 SG_ XCP_Daempfer_CRO_02_Data : 0|512@1+ (1.0,0.0) [0.0|13407807929942597099574024998205846127479365820592393377723561443721764030073546976801874298166903427690031858186486050853753882811946569946433649006084095] ""  DCC_Gen3

BO_ 2617218561 XCP_Daempfer_DTO_01: 8 DCC_Gen3
 SG_ XCP_Daempfer_DTO_01_Data : 0|64@1+ (1.0,0.0) [0.0|18446744073709551615] ""  Vector__XXX

BO_ 2617218563 XCP_Daempfer_DTO_02: 64 DCC_Gen3
 SG_ XCP_Daempfer_DTO_02_Data : 0|512@1+ (1.0,0.0) [0.0|13407807929942597099574024998205846127479365820592393377723561443721764030073546976801874298166903427690031858186486050853753882811946569946433649006084095] ""  Vector__XXX

BO_ 2617105920 XCP_EBKV_CRO_01: 64 Vector__XXX
 SG_ XCP_EBKV_CRO_01_Data : 0|64@1+ (1.0,0.0) [0.0|18446744073709551615] ""  EBKV_MQBW

BO_ 2617105921 XCP_EBKV_DTO_01: 64 EBKV_MQBW
 SG_ XCP_EBKV_DTO_01_Data : 0|64@1+ (1.0,0.0) [0.0|18446744073709551615] ""  Vector__XXX

BO_ 2617024016 XCP_ESC_CRO_01: 64 Vector__XXX
 SG_ XCP_ESC_CRO_01_Data : 0|64@1+ (1.0,0.0) [0.0|18446744073709551615] ""  ESC_MQBW

BO_ 2617024017 XCP_ESC_DTO_01: 64 ESC_MQBW
 SG_ XCP_ESC_DTO_01_Data : 0|64@1+ (1.0,0.0) [0.0|18446744073709551615] ""  Vector__XXX

BO_ 2617021952 XCP_Lenkhilfe_CRO_01: 64 Vector__XXX
 SG_ XCP_Lenkhilfe_CRO_01_Data : 0|64@1+ (1.0,0.0) [0.0|18446744073709551615] ""  Lenkhilfe_REPS

BO_ 2617021953 XCP_Lenkhilfe_DTO_01: 64 Lenkhilfe_REPS
 SG_ XCP_Lenkhilfe_DTO_01_Data : 0|64@1+ (1.0,0.0) [0.0|18446744073709551615] ""  Vector__XXX

BO_ 1411 ZV_02: 8 Gateway_Max
 SG_ ZV_verriegeln_Anf : 0|1@1+ (1.0,0.0) [0.0|1] ""  Vector__XXX
 SG_ ZV_STSG_HFS_Anf : 1|1@1+ (1.0,0.0) [0.0|1] ""  Vector__XXX
 SG_ ZV_STSG_HBFS_Anf : 2|1@1+ (1.0,0.0) [0.0|1] ""  Vector__XXX
 SG_ ZV_Anf_Challenge_Auth : 3|1@1+ (1.0,0.0) [0.0|1] ""  Vector__XXX
 SG_ ZV_STSG_Crashzustand : 4|1@1+ (1.0,0.0) [0.0|1] ""  Vector__XXX
 SG_ ZV_STSG_eKiSi_defekt : 5|1@1+ (1.0,0.0) [0.0|1] ""  Vector__XXX
 SG_ ZV_eRWK_Umfeld_Pruefung : 6|1@1+ (1.0,0.0) [0.0|1] ""  Vector__XXX
 SG_ VIP_Sensor_STSG_HFS_betaetigt : 10|1@1+ (1.0,0.0) [0.0|1] ""  Vector__XXX
 SG_ VIP_Sensor_STSG_HBFS_betaetigt : 11|1@1+ (1.0,0.0) [0.0|1] ""  Vector__XXX
 SG_ BCM_FH_Freigabe : 12|1@1+ (1.0,0.0) [0.0|1] ""  Vector__XXX
 SG_ BCM_Komfortfkt_Freigabe : 13|1@1+ (1.0,0.0) [0.0|1] ""  Vector__XXX
 SG_ BCM_HSK_Freigabe : 14|1@1+ (1.0,0.0) [0.0|1] ""  Vector__XXX
 SG_ BCM_Verdeck_Freigabe : 15|1@1+ (1.0,0.0) [0.0|1] ""  Vector__XXX
 SG_ ZV_verriegelt_intern_ist : 16|1@1+ (1.0,0.0) [0.0|1] ""  Vector__XXX
 SG_ ZV_verriegelt_extern_ist : 17|1@1+ (1.0,0.0) [0.0|1] ""  Airbag
 SG_ ZV_verriegelt_intern_soll : 18|1@1+ (1.0,0.0) [0.0|1] ""  Vector__XXX
 SG_ ZV_verriegelt_extern_soll : 19|1@1+ (1.0,0.0) [0.0|1] ""  Airbag
 SG_ ZV_gesafet_extern_ist : 20|1@1+ (1.0,0.0) [0.0|1] ""  Vector__XXX
 SG_ ZV_gesafet_extern_soll : 21|1@1+ (1.0,0.0) [0.0|1] ""  Vector__XXX
 SG_ ZV_Einzeltuerentriegelung : 22|1@1+ (1.0,0.0) [0.0|1] ""  Vector__XXX
 SG_ ZV_Heckeinzelentriegelung : 23|1@1+ (1.0,0.0) [0.0|1] ""  Vector__XXX
 SG_ ZV_FT_offen : 24|1@1+ (1.0,0.0) [0.0|1] ""  Airbag,ESC_MQBW
 SG_ ZV_BT_offen : 25|1@1+ (1.0,0.0) [0.0|1] ""  Airbag
 SG_ ZV_HFS_offen : 26|1@1+ (1.0,0.0) [0.0|1] ""  Airbag
 SG_ ZV_HBFS_offen : 27|1@1+ (1.0,0.0) [0.0|1] ""  Airbag
 SG_ ZV_HD_offen : 28|1@1+ (1.0,0.0) [0.0|1] ""  Airbag
 SG_ ZV_HS_offen : 29|1@1+ (1.0,0.0) [0.0|1] ""  Vector__XXX
 SG_ IRUE_aktiv : 30|1@1+ (1.0,0.0) [0.0|1] ""  Vector__XXX
 SG_ DWA_aktiv : 31|1@1+ (1.0,0.0) [0.0|1] ""  Vector__XXX
 SG_ HD_Hauptraste : 32|1@1+ (1.0,0.0) [0.0|1] ""  Vector__XXX
 SG_ HD_Vorraste : 33|1@1+ (1.0,0.0) [0.0|1] ""  Vector__XXX
 SG_ FFB_HDF_Taste : 34|1@1+ (1.0,0.0) [0.0|1] ""  Vector__XXX
 SG_ FFB_Panik_Taste : 35|1@1+ (1.0,0.0) [0.0|1] ""  Vector__XXX
 SG_ FFB_Auf_Taste : 36|1@1+ (1.0,0.0) [0.0|1] ""  Vector__XXX
 SG_ FFB_Zu_Taste : 37|1@1+ (1.0,0.0) [0.0|1] ""  Vector__XXX
 SG_ FFB_CarFinder : 38|1@1+ (1.0,0.0) [0.0|1] ""  Vector__XXX
 SG_ FFB_Komfortoeffnen : 39|1@1+ (1.0,0.0) [0.0|1] ""  Vector__XXX
 SG_ FFB_Komfortschliessen : 40|1@1+ (1.0,0.0) [0.0|1] ""  Vector__XXX
 SG_ FBS_IDG_in_Reichweite : 41|1@1+ (1.0,0.0) [0.0|1] ""  Vector__XXX
 SG_ ZV_Schluessel_Zugang : 42|4@1+ (1.0,0.0) [0.0|15] ""  Vector__XXX
 SG_ ZV_SafeFunktion_aktiv : 46|1@1+ (1.0,0.0) [0.0|1] ""  Vector__XXX
 SG_ FBS_Warn_Schluessel_Batt : 47|1@1+ (1.0,0.0) [0.0|1] ""  Vector__XXX
 SG_ ZV_Oeffnungsmodus : 48|2@1+ (1.0,0.0) [0.0|3] ""  Vector__XXX
 SG_ HFS_verriegelt : 50|1@1+ (1.0,0.0) [0.0|1] ""  Vector__XXX
 SG_ HFS_gesafet : 51|1@1+ (1.0,0.0) [0.0|1] ""  Vector__XXX
 SG_ HBFS_verriegelt : 52|1@1+ (1.0,0.0) [0.0|1] ""  Vector__XXX
 SG_ HBFS_gesafet : 53|1@1+ (1.0,0.0) [0.0|1] ""  Vector__XXX
 SG_ ZV_ist_Zustand_verfuegbar : 54|1@1+ (1.0,0.0) [0.0|1] ""  Vector__XXX
 SG_ IRUE_Taster_Fkts_LED : 55|1@1+ (1.0,0.0) [0.0|1] ""  Vector__XXX
 SG_ ZV_Tankklappe_offen : 56|1@1+ (1.0,0.0) [0.0|1] ""  Vector__XXX
 SG_ ZV_Rollo_auf : 57|1@1+ (1.0,0.0) [0.0|1] ""  Vector__XXX
 SG_ ZV_Rollo_zu : 58|1@1+ (1.0,0.0) [0.0|1] ""  Vector__XXX
 SG_ ZV_SAD_auf : 59|1@1+ (1.0,0.0) [0.0|1] ""  Vector__XXX
 SG_ ZV_SAD_zu : 60|1@1+ (1.0,0.0) [0.0|1] ""  Vector__XXX
 SG_ BCM_Tankklappensteller_Fehler : 61|1@1+ (1.0,0.0) [0.0|1] ""  Vector__XXX
 SG_ ZV_verriegelt_soll : 62|2@1+ (1.0,0.0) [0.0|3] ""  Vector__XXX

CM_ BO_ 1413 "MQB, MLBevo";
CM_ BO_ 995 "ab MQB IS5";
CM_ BO_ 1716 "200ms bei D4 und folgende";
CM_ BO_ 1702 "MLBevo";
CM_ BO_ 2617218560 "ab MQB";
CM_ BO_ 2617218562 "ab MQB";
CM_ BO_ 2617218561 "ab MQB";
CM_ BO_ 2617218563 "ab MQB";
CM_ BO_ 2617024016 "ab MQB";
CM_ BO_ 2617024017 "ab MQB";

CM_ SG_ 565 Kam_aktiv_Anforderung_HMS "Anforderung der Dienste des HMS durch die Kamera Rear";
CM_ SG_ 565 Kam_aktiv_Anhalteweg_Anf "Zeigt eine Anhalteweg Anforderung an";
CM_ SG_ 565 Kam_aktiv_BKD_Anf "Anforderung der Systemtotzeitoptimierung ans VZM";
CM_ SG_ 565 Kam_aktiv_Notstopp_Anf "Anforderung Notstopp der Kamera";
CM_ SG_ 565 Kam_aktiv_parken_beibehalten "Fordert das Parken beim HMS an";
CM_ SG_ 565 Kam_aktiv_Prefill_Anf "Anforderung Prefill am VZM";
CM_ SG_ 565 Kam_aktiv_Soll_Anhalteweg_Anf "Anforderung des Soll Anhalteweges der Kamera beim VZM";
CM_ SG_ 565 Kam_aktiv_Verz_Anf "Zeigt die die angeforderte Verzögerung an, des aktuell aktiven Bremssystem";
CM_ SG_ 565 Kam_aktiv_Verz_Anf_ASIL "Angabe des ASIL Levels der aktuell aktiven Bremsfunktion Richtung VZM und HMS";
CM_ SG_ 565 Kam_aktiv_Warnruck_Anf "Signal zur Anforderung Warnruck beim VZM";
CM_ SG_ 565 Kam_aktiv_Warnruckeln_Anf "Anforderung Warnruckeln beim VZM";
CM_ SG_ 565 Kam_aktives_System "zeigt an welches parkendes System aktiv ist";

CM_ SG_ 2033 Request_Airbag_Deployment "Request für die Disposal Diagnose (ISO26021)";

CM_ SG_ 2041 Response_Airbag_Deployment "Response für die Disposal Diagnose (ISO26021)";

CM_ SG_ 2264486920 RHP_01_BZ "4bit Botschaftszähler, wird mit jeder Sendebotschaft inkrementiert";
CM_ SG_ 2264486920 RHP_01_CRC "Für MLB:
Berechnung siehe Lastenheft 'Kommunikationsabsicherung für FlexRay und CAN'
Ab MQB und MLBevo:
Berechnung siehe Lastenheft 'End-to-End Kommunikationsabsicherung'

Endwerte siehe Begleitdokument 'S-PDU Kennungsfolgen'";
CM_ SG_ 2264486920 RHP_Anf_ASIL "Definiert das Anforderungssignal von RHP an VZM mit dem dynamischen ASIL";
CM_ SG_ 2264486920 RHP_Anforderung_HMS "Bremsanforderung an den Haltemanager";
CM_ SG_ 2264486920 RHP_EA_AnfStat "This signal indicates the activation status information from RHP to EA";
CM_ SG_ 2264486920 RHP_EA_eCall "RHP triggers eCall via sending the requirements on EA";
CM_ SG_ 2264486920 RHP_EA_Innenraumlicht "RHP turning on interior lights via sending the requirements on EA";
CM_ SG_ 2264486920 RHP_EA_PreCrash "RHP triggers PreCrash via sending the requirements on EA";
CM_ SG_ 2264486920 RHP_EA_Tueren "RHP triggers door unlocking via sending the requirements on EA";
CM_ SG_ 2264486920 RHP_eCall_Anf "RHP triggers eCall";
CM_ SG_ 2264486920 RHP_Fahrzeughupe_Anf "Rush Hour Pilot Anforderung Fahrzeughupe";
CM_ SG_ 2264486920 RHP_Freilaufstrategie_TSK "Das Signal definiert im aktiven RHP - Betrieb, ob ein Freilauf direkt über das RHP angefordert wird oder ein Freilauf über den Triebstrangkoordinator (TSK) angefordert wird, falls das RHP den Freilauf freigibt.";
CM_ SG_ 2264486920 RHP_HOS "Rush Hour Pilot hands-off status";
CM_ SG_ 2264486920 RHP_Innenraumlicht_Anf "RHP turns on interior lights.";
CM_ SG_ 2264486920 RHP_Minimale_Bremsung "Im Falle eines gesetzten Bits wird vom RHP dem TSK angezeigt, dass es sich im Resume_Suspend_Mode befindet. In diesem Mode darf der TSK keine ECD-Bremsung anfordern, unabhängig von der 'RHP_Sollbeschleunigungsanforderung'. Eine Fahrzeugverzögerung darf nu";
CM_ SG_ 2264486920 RHP_nachtr_Stopp_Anf "Dieses Signal dient dem Motor als Trigger, dass ein nachträglicher Motorstopp eingeleitet werden kann, wenn es die Bedingungen des StSt Koordinators dies zulassen.";
CM_ SG_ 2264486920 RHP_neg_Sollbeschl_Grad "Empfehlung an den Triebstrangkoordinator , mit welchem betragsmäßig maximalen negativen Gradienten eine RHP-Anforderung 'RHP_Sollbeschleunigung' einzuregeln ist.";
CM_ SG_ 2264486920 RHP_OPSEnable "The OPS function receives the following signal to enable the function";
CM_ SG_ 2264486920 RHP_Parking_St "The signal shows the parking function status, if the parking function is Slot Detect or Guidance, the parking space should output.";
CM_ SG_ 2264486920 RHP_pos_Sollbeschl_Grad "Empfehlung an den Triebstrangkoordinator , mit welchem betragsmäßig maximalen positiven Gradienten eine RHP-Anforderung 'RHP_Sollbeschleunigung' einzuregeln ist.";
CM_ SG_ 2264486920 RHP_PreCrash_Anf "RHP triggers PreCrash";
CM_ SG_ 2264486920 RHP_QFK_AnfStat "Statusinformationen des Anforderers";
CM_ SG_ 2264486920 RHP_QFK_Art1 "Auswahlsignal für RHP_QFK_Signal1";
CM_ SG_ 2264486920 RHP_QFK_Art2 "Auswahlsignal für RHP_QFK_Signal2";
CM_ SG_ 2264486920 RHP_QFK_KrSoll "Krümmungsanforderung";
CM_ SG_ 2264486920 RHP_QFK_KrSoll_VZ "Vorzeichen für die Krümmungsanforderung";
CM_ SG_ 2264486920 RHP_QFK_KruemmSoll "Krümmungsanforderung";
CM_ SG_ 2264486920 RHP_QFK_KruemmSoll_VZ "Vorzeichen für die Krümmungsanforderung";
CM_ SG_ 2264486920 RHP_QFK_Signal1 "Inhalt RHP_QFK_Signal1 wird durch das Signal RHP_QFK_Art1 gesteuert.
Nähere Informationen im LAH Querführungskoordinator.";
CM_ SG_ 2264486920 RHP_QFK_Signal2 "Inhalt RHP_QFK_Signal2 wird durch das Signal RHP_QFK_Art2 gesteuert.
Nähere Informationen im LAH Querführungskoordinator.";
CM_ SG_ 2264486920 RHP_QFK_Spuerb "Spürbarkeitsanforderung. Legt fest, mit welchem Handmoment die angeforderte Krümmung überlenkt werden muss.";
CM_ SG_ 2264486920 RHP_RBF_Available "This signal is used for info RBF for RHP can support RBF forward or not";
CM_ SG_ 2264486920 RHP_Ruckfreigabe "Anforderung Bremsruck für Funktion Rush Hour Pilot";
CM_ SG_ 2264486920 RHP_SCAM_HeatingRequest "Gibt an, ob eine Beeinträchtigung der Kamerasicht durch Eis oder Beschlag vorliegt und diese durch Anschalten der Scheibenheizung behoben werden kann.";
CM_ SG_ 2264486920 RHP_Sollbeschleunigung "Anforderung an den Triebstrangkoordinator , eine 'RHP_Sollbeschleunigung' umzusetzen.";
CM_ SG_ 2264486920 RHP_Spurwechsel_Ready "Angabe der assistierten Spurwechselmöglichkeiten durch die Funktion 'Rush Hour Pilot'";
CM_ SG_ 2264486920 RHP_StartStopp_Info "Freigabe bzw. Startanforderung für Start/Stopp";
CM_ SG_ 2264486920 RHP_Status_Function "RHP status signal";
CM_ SG_ 2264486920 RHP_Status_Lat "RHP status signal for the lateral control";
CM_ SG_ 2264486920 RHP_Status_Long "RHP status signal for the longitudinal control";
CM_ SG_ 2264486920 RHP_TSK_Status "RHP status signal to TSK";
CM_ SG_ 2264486920 RHP_TV_Trigger "This signal is used for switching on/off TVeMid stream data output for RHP parking function.";
CM_ SG_ 2264486920 RHP_Uss_Anforderung "Control signal from RHP to front side PLA (VLS, VRS) and APS (VL, VR) sensors";
CM_ SG_ 2264486920 RHP_Verz_Anf "Verzögerungsanforderung der Funktionen Zielbremsung und Teilbremsung an das VZM";
CM_ SG_ 2264486920 RHP_Verz_Freigabe "Freigabe-Bit der RHP Verzögerung an das VZM";
CM_ SG_ 2264486920 RHP_Warnblinken "Ansteuerung des Warnblinkers für die Funktion Rush Hour Pilot";
CM_ SG_ 2264486920 RHP_Warnruckeln_Anf "Anforderung an VZM, welches Warnruckeln umgesetzt werden soll.";
CM_ SG_ 2264486920 RHP_zul_Regelabw_oben "Anforderung an den Triebstrangkoordinator. Zulässiger Betrag der Abweichung zwischen angeforderter 'RHP_Sollbeschleunigung' und umzusetzender Sollbeschleunigung  im TSK. Im TSK wird, abhängig vom Arbeitspunkt die Toleranz und die Sollbeschleunigung für da";
CM_ SG_ 2264486920 RHP_zul_Regelabw_unten "Anforderung an den Triebstrangkoordinator. Zulässiger Betrag der Abweichung zwischen angeforderter 'RHP_Sollbeschleunigung' und umzusetzender Sollbeschleunigung  im TSK. Im TSK wird, abhängig vom Arbeitspunkt die Toleranz und die Sollbeschleunigung für da";

CM_ SG_ 2527679688 RHP_ASM_Data_1 "Dieses Signal wird von mehreren Funktionen auf dem RHP gemäß der ASM-Datendefinition befüllt und an den Assistenz System Monitor ASM gesendet.";
CM_ SG_ 2527679688 RHP_ASM_Data_2 "Dieses Signal wird von mehreren Funktionen auf dem RHP gemäß der ASM-Datendefinition befüllt und an den Assistenz System Monitor ASM gesendet.";
CM_ SG_ 2527679688 RHP_ASM_Data_3 "Dieses Signal wird von mehreren Funktionen auf dem RHP gemäß der ASM-Datendefinition befüllt und an den Assistenz System Monitor ASM gesendet.";
CM_ SG_ 2527679688 RHP_ASM_Data_4 "Dieses Signal wird von mehreren Funktionen auf dem RHP gemäß der ASM-Datendefinition befüllt und an den Assistenz System Monitor ASM gesendet.";
CM_ SG_ 2527679688 RHP_ASM_Data_5 "Dieses Signal wird von mehreren Funktionen auf dem RHP gemäß der ASM-Datendefinition befüllt und an den Assistenz System Monitor ASM gesendet.";
CM_ SG_ 2527679688 RHP_ASM_Data_6 "Dieses Signal wird von mehreren Funktionen auf dem RHP gemäß der ASM-Datendefinition befüllt und an den Assistenz System Monitor ASM gesendet.";
CM_ SG_ 2527679688 RHP_ASM_Ereignis "Dieses Signal definiert, welche Funktion und welche Art von Aktivität das Senden der Botschaft an den Assistenzsystemmonitor ASM veranlasst hat.";
CM_ SG_ 2527679688 RHP_ASM_Zeitstempel_02 "Dieses Signal ermöglicht die zeitliche Zuordnung der von dem RHP an den Assistenzsystemmonitor ASM gesendeten Statusbotschaften.";

CM_ SG_ 1610 RKA_FMVSS138_Lampe "Kein Einsatz RKA im D4 Hybrid";
CM_ SG_ 1610 RKA_FMVSS138_MIL "Zentral blinkend für 1 Minute immer nur gelbe Lampe, dann statisch an. 

Kein Einsatz RKA im D4 Hybrid";
CM_ SG_ 1610 RKA_Reifentyp "Ausgabe von Reifentyp";
CM_ SG_ 1610 RKA_Warnungen_02 "Ansteuerung der Warnungen (Texte, Töne, Lampen) im Kombi für Funktion RKA+

Kein Einsatz RKA im D4 Hybrid";

CM_ SG_ 2589283756 SOK_ungeschuetzte_Zeit "Periodisch verschickter SOK Zeitwert des SOK Zeitmasters als Referenzzeit zur Erkennung von Clockjitter durch andere SOK Teilnehmer.

Der Empfang dieses Signals ist verpflichtend für jedes Steuergerät, das durch die authentische Broadcast Funktionalität";

CM_ SG_ 2464153619 SOK_Zeit_ABS_Challenge "Challenge of SOK participant ESC to SOK time server for requesting authentic SOK time";

CM_ SG_ 2464284691 SOK_Zeit_ABS_Signatur "Signature to protect authentic SOK time";
CM_ SG_ 2464284691 SOK_Zeit_ABS_Zeit "Response signal of SOK time server to challenge of an SOK participant, containing SOK time";

CM_ SG_ 2464153621 SOK_Zeit_Airbag_Challenge "Challenge im Rahmen des SOK Challenge-Response Protokolls.

Geschützte Funktion: Empfang der SOK-Zeit vom SOK-Zeitmaster; verbindlich für Steuergeräte, welche mit der durch SOK geschützten Broadcast Nachrichten empfangen oder versenden";

CM_ SG_ 2464284693 SOK_Zeit_Airbag_Signatur "Signatur im Rahmen des SOK Challenge-Response Protokolls.

Geschützte Funktion: Empfang der SOK-Zeit vom SOK-Zeitmaster; verbindlich für Steuergeräte, welche mit der durch SOK geschützten Broadcast Nachrichten empfangen oder versenden";
CM_ SG_ 2464284693 SOK_Zeit_Airbag_Zeit "Aktueller Wert der SOK-Zeit des SOK-Zeitmasters; geschützt durch das SOK Challenge-Response Protokoll";

CM_ SG_ 2464153659 SOK_Zeit_EBKV_Challenge "Challenge im Rahmen des SOK Challenge-Response Protokolls.

Geschützte Funktion: Empfang der SOK-Zeit vom SOK-Zeitmaster; verbindlich für Steuergeräte, welche mit der durch SOK geschützten Broadcast Nachrichten empfangen oder versenden";

CM_ SG_ 2464284731 SOK_Zeit_EBKV_Signatur "Signatur im Rahmen des SOK Challenge-Response Protokolls.

Geschützte Funktion: Empfang der SOK-Zeit vom SOK-Zeitmaster; verbindlich für Steuergeräte, welche mit der durch SOK geschützten Broadcast Nachrichten empfangen oder versenden";
CM_ SG_ 2464284731 SOK_Zeit_EBKV_Zeit "Aktueller Wert der SOK-Zeit des SOK-Zeitmasters; geschützt durch das SOK Challenge-Response Protokoll";

CM_ SG_ 1413 GW_KD_Fehler "Kundendienstfehlerbit Gateway zur Anzeige eines im Gateway abgelegten Fehlerspeichereintrages.";
CM_ SG_ 1413 SI_BUS_01 "MQB/MQB_A0/PQ26: ACAN
MQB2020: ACAN(FD)
MLBevo: HCAN
E3_Volumen: ACAN(FD)
MQBw_Baseline: ACAN(FD)";
CM_ SG_ 1413 SI_BUS_02 "MQB/MQB A0 Standard+, High: FCAN
MQB2020: FCAN(FD)
MLBevo: Frei
E3_Volumen: FCAN(FD)
MQBw_Baseline: FCAN(FD)";
CM_ SG_ 1413 SI_BUS_03 "MQB/MQB A0/PQ26: KCAN
MQB2020: KCAN
MLBevo: KCAN
E3_Volumen: KCAN(HS) / K2CAN(FD) (Buskopplung)
MQBw_Baseline: KCAN(HS)";
CM_ SG_ 1413 SI_BUS_04 "MQB/MQB A0 Standard+, High: ICAN
MQB2020: ICAN(HS)
MLBevo: ICAN
E3_Volumen: ABCAN(FD)
MQBw_Baseline: ICAN(HS)";
CM_ SG_ 1413 SI_BUS_05 "MQB/MQB A0/PQ26: DiagCAN
MQB2020: DiagCAN(FD)
MLBevo: DiagCAN
E3_Volumen: DiagCAN(FD)
MQBw_Baseline: DiagCAN(FD)";
CM_ SG_ 1413 SI_BUS_06 "MQB/MQB A0/PQ26: ECAN
MQB2020: FASCAN(FD)
MLBevo: ECAN
E3_Volumen: FASCAN_1(FD)
MQBw_Baseline: FASCAN_1(FD)";
CM_ SG_ 1413 SI_BUS_07 "MQB: LIN1 (Energie)
MQB2020: LIN1 (Energie)
MLBevo: LIN1 (Energie)
E3_Volumen: LIN 1 (Energie)
MQBw_Baseline: LIN1 (Energie)";
CM_ SG_ 1413 SI_BUS_08 "MQB: LIN2 (MFL)
MQB2020: LIN2 (MFL)
MLBevo: LIN2 (MFL)
E3_Volumen: LIN2 (MFL)
MQBw_Baseline: LIN2 (MFL)";
CM_ SG_ 1413 SI_BUS_09 "MQB: LIN3 (unbelegt)
MQB2020: LIN3 (Uhr/FES)
MLBevo: LIN3 (Energie2)
MEB: LIN3
E³ 1.1 UNECE: MDKCAN";
CM_ SG_ 1413 SI_BUS_10 "MLBevo: Flexray
MQB2020: MCAN
MQBw_Baseline: FASCAN_2(FD)
E³ 1.1 UNECE: FASCAN_2(FD)";
CM_ SG_ 1413 SI_BUS_11 "MLBevo: Ethernet
MEB: LIN4";
CM_ SG_ 1413 SI_BUS_12 "MQB: unbelegt
MLBevo: K2CAN
E3_Volumen: MFLCAN
MQBw_Baseline: K2CAN(FD)";
CM_ SG_ 1413 SI_BUS_13 "MQB: unbelegt
MLBevo: DCAN
MEB: CCAN
MQBw_Baseline: K3CAN(FD)";
CM_ SG_ 1413 SI_BUS_14 "MQB/MQB A0: unbelegt
MQB2020: HCAN
MLBevo: CCAN
E3_Volumen: EVCAN(FD)
MQBw_Baseline: EVCANFD(FD)";
CM_ SG_ 1413 SI_BUS_15 "MQB: frei
MQB2020: frei
MLBevo: frei
MEB: AFSCAN";
CM_ SG_ 1413 SI_Bus_Identifikation "Das Signal identifiziert den Bus eindeutig. Das Signal ist konstant auf jedem Bus.
Der Signalwert entspricht dem Wert 'Busnummer' aus der VW80127 Gateway_component_list_databus_identification (0x2A2D) 'Bus-Identifier'.";
CM_ SG_ 1413 SI_CAB_V14 "CAB = Clusteraktivbits (V14)";
CM_ SG_ 1413 SI_Diagnose_Aktiv "Gibt an ob Diagnose-Botschaften empfangen werden und somit eine Diagnose aktiv ist.
MQB: Gibt an ob Diagnose-Bus Botschaften empfangen werden und somit eine Diagnose aktiv ist.";
CM_ SG_ 1413 SI_NWDF "Netzwerk-Diagnose Freigebe zur zentralen Aktivierung der Netzwerkdiagnose";
CM_ SG_ 1413 SI_NWDF_30 "Netzwerk-Diagnose Freigabe zur zentralen Aktivierung der Netzwerkdiagnose (keine Ausblendbedingung aktiv)";
CM_ SG_ 1413 SI_NWDF_gueltig "Gültigkeitsbit zu SI_NWDF gemäß Lastenheft: Zentrale Aktivierung Netzwerkdiagnose";
CM_ SG_ 1413 SI_P_Mode "Zentrale Steuerung des Produktionsmodes gemäß Q-LAH-Produktionsmode (LAH.DUM.907.AS)";
CM_ SG_ 1413 SI_P_Mode_gueltig "zeigt an, ob es sich um ein Fahrzeug mit zentraler oder dezentraler Steu-erung des Produktionsmodes handelt
Siehe Q-LAH Produktionsmode (LAH.DUM.907.AS)";
CM_ SG_ 1413 SI_QRS_Mode "Messmodus Quick-Ruhestrom";
CM_ SG_ 1413 SI_Sammel_SG_Fehler "Anzahl der gesetzten KD-Fehler direkt angeschlossener Steuergeräte der DK3 und DK4 gemäß 80127.
Hinweis: Ein Subbusmaster stellt nur die gesammelte Information der an ihn angeschlossenen Steuergeräte der DK3 und DK4 zur Verfügung.

Für ServiceKey Auswe";
CM_ SG_ 1413 SI_Sammelfehler "Sammelfehlermeldung zur Anzeige im Kombi - siehe Spez. Sammelfehlermeldung
Hinweis: Einzelne Steuergeräte können zur Anpassung an den Produktionsprozess im Gateway auskodiert werden!";
CM_ SG_ 1413 SI_T_Mode "0x0: Transportmodus nicht aktiv
0x1: Transportmodus aktiv";
CM_ SG_ 1413 SI_T_Schutz "Transportschutz-Signal, das bei Transportmodus und Motorlauf aktiv bleibt
0x0: Transportschutz nicht aktiv
0x1: Transportschutz aktiv";

CM_ SG_ 165 TS_CAN_Ma_CRC "CRC of TimeSync Message.
DataIDList={0x00;0x00;0x00;0x00;0x00;0x00;0x00;0x00;0x00;0x00;0x00;0x00;0x00;0x00;0x00;0x00}";
CM_ SG_ 165 TS_CAN_Ma_OVS "Overflow of seconds";
CM_ SG_ 165 TS_CAN_Ma_SequenceCounter "Sequence Counter of TimeSync Message";
CM_ SG_ 165 TS_CAN_Ma_SGW "Time Gateway synchronization status";
CM_ SG_ 165 TS_CAN_Ma_SyncTimeSec "32 bit LSB of the 48 bits  seconds part of time";
CM_ SG_ 165 TS_CAN_Ma_TimeDomain "Time Domain of TimeSync Messages";
CM_ SG_ 165 TS_CAN_Ma_Type "Type of TimeSync Message";

CM_ SG_ 1447 bCall_active "1: Breakdown call is active
0: BreakdownCall is inactive";
CM_ SG_ 1447 eCall_Funktionsstatus "HMI-Aufruf im Kombi (Broadcast)
Fehlerfälle die im Kombi angezeigt werden können";
CM_ SG_ 1447 eCall_Funktionsstatus_02 "Erweiterung des Funktionsstatus für andere Funktionen
ACN aktiv, MEC aktiv
MEC = manual emergency call = maueller Notruf
ACN = automatic emergency call = automatischer Notruf";
CM_ SG_ 1447 eCall_MCC "Mobile Country Code of the current mobile network
ITU-T E.212";
CM_ SG_ 1447 eCall_Mute_Anf "Signalisiert die Aufforderungen alle Soundquellen im Fahrzeug während eines aktiven Notrufs zu muten";
CM_ SG_ 1447 FaceRec_Enroll_Challenge_Request "When FaceRec on MIK receives this signal it will provide a challenge via SOK_FR_Enroll_MIK_Challenge.";
CM_ SG_ 1447 FoD_Anz_Funktionsabschaltung "Signal triggert Aufschaltung eines Popups, um dem Fahrer die Abschaltung einer Funktion zu melden.";
CM_ SG_ 1447 iCall_active "Statusrückmeldung von OCU über Infocall aktiv/inaktiv";
CM_ SG_ 1447 MOD_Energie_Anf "Anforderung Energieversorgung MOD-Job an das NVEM";
CM_ SG_ 1447 MOD_Request_ServiceKey "Sendet ein Signal zum ServiceKey-Master, welcher daraufhin einen aktuellen ServiceKey1c auf den Bus legt.";
CM_ SG_ 1447 ORU_KombiTimer "Ankündigung eines ORU OCU zum Kombi zur Darstellung entsprechender Symbole";
CM_ SG_ 1447 TM_Door_Lock "Remote Door lock angefordert: ZV zu/verriegeln";
CM_ SG_ 1447 TM_Door_Unlock "Remote Door unlock angefordert: ZV auf/entriegeln";
CM_ SG_ 1447 TM_Nur_Hupen "Remote Hupen (ohne Blinken) aktiviert";
CM_ SG_ 1447 TM_Panik_Alarm "Remote Hupen und Blinken aktiv";
CM_ SG_ 1447 TM_Spiegel_Anklappen "Anklappen der Außenspiegel über Remote MOD Anforderung";
CM_ SG_ 1447 TM_Warnblinken "Remote Blinken aktiviert";
CM_ SG_ 1447 TM_ZV_Signatur "Gespeicherte Signatur der ZV für Authentifizierung";

CM_ SG_ 997 eTAB_FS_Bowdenzug_Auswerfen "Soll den Bowdenzug für die mechanische Redundanz";
CM_ SG_ 997 FS_Push_Tuergriff "Push zum Ausfahren der Flush-Tuergriffe";
CM_ SG_ 997 FS_Status_eTAG_ext "erweitert um den Wert 'verfährt'";
CM_ SG_ 997 FT_ASW_Warnton "erzeugt ein Warnton bei AS Warnung";
CM_ SG_ 997 FT_BFS_Tuer_Status "Gesammelte Türstatusbotschaft";
CM_ SG_ 997 FT_Cargolock_bet "CargoLock-Taste betätigt";
CM_ SG_ 997 FT_HBFS_Tuer_Status "Türstatus mit Fehler und Initwert";
CM_ SG_ 997 FT_HFS_Tuer_Status "Türstatus mit Fehler und Initwert";
CM_ SG_ 997 FT_kisi_asynchron "Signal erzeugt eine seperate Warnmeldung bei ungewollter Asynchronität der 'elektrische Kindersicherung' der Schlösser.";
CM_ SG_ 997 FT_KiSi_Status_Soll_HBFS "Soll KiSi Status HBFS";
CM_ SG_ 997 FT_KiSi_Status_Soll_HFS "Soll Status der KiSi HFS";
CM_ SG_ 997 FT_Kisi_Taster_li_02 "Der Kindersicherungstaster hinten links aktiv.";
CM_ SG_ 997 FT_Kisi_Taster_re_02 "Der Kindersicherungstaster hinten rechts aktiv.";
CM_ SG_ 997 FT_Lock_Taster_02 "Lock-Taster betätigt";
CM_ SG_ 997 FT_Schluesselschalter_zu_02 "Schlüsselschalter für Schließen betätigt";
CM_ SG_ 997 FT_SP_Heizung_ein "Dieses Signal zeigt die tatsächliche Ansteuerung der  Spiegelheizung incl. PWM an. 
Zudem wird aufgrund des Teilnetzbetriebs das Signal zur Ansteuerung der Beifahrer-Spiegelheizung benutzt.

";
CM_ SG_ 997 FT_TCR_Mode_aktiv "Signal zeigt eine aktive mechanische Redundanz am Türschloss an.";
CM_ SG_ 997 FT_TD_Taste_Status "Status Taste für Tankdeckel";
CM_ SG_ 997 FT_Tuer_Status "Tür geöffnet oder Tür geschlossen";
CM_ SG_ 997 FT_Tuer_Status_QBit "Dieses Bit gibt die Zuverlässigkeit des Türkontakts an. Ein auf dieses Bit folgender Fehlereintrag ist mit dem Sender des Bits abzustimmen (gültig ab PPE).";
CM_ SG_ 997 FT_Tueroeffnen_Warnung "Bit wird gesetzt, wenn Tür während der Fahrt geoeffnet werden soll.";
CM_ SG_ 997 SSA_FT_ASW_Status "SmartSensorActor:
Rückmeldung des Status der ASW Anzeige.";
CM_ SG_ 997 TBF_FS_Touch_Event "Touch_Events für Informationen einer Funktionsauslösung auf dem TBF, welche dann für bspw. ein akustisches Signal zentral umgesetzt werden können.";
CM_ SG_ 997 TSG_FS_Spiegel_angeklappt "Funktionsrückmeldung TSG_FS über Spiegelstellung angeklappt";
CM_ SG_ 997 TSG_FT_02_BZ "4bit Botschaftszaehler, wird mit jeder Sendebotschaft inkrementiert";
CM_ SG_ 997 TSG_FT_02_CRC "Für MLB:
'Berechnung siehe Lastenheft 'Kommunikationsabsicherung für FlexRay und CAN''

Ab MQB und MLBevo:
'Berechnung siehe Lastenheft 'End-to-End Kommunikationsabsicherung''

Endwerte siehe Begleitdokument 'S-PDU Kennungsfolgen'";

CM_ SG_ 2589283772 QSP_Temperatur_Oel "Aktuelle Hydrauli-Oel-Temperatur";
CM_ SG_ 2589283772 QSP_Thermische_Belastung "Maximale aktuelle thermische Belastung des Gesamtsystems (Motor, ECU, Kupplungen)";
CM_ SG_ 2589283772 QSP_Warnlampe "Status der Warnlampe: aktuell anliegender Fehlerzustand";
CM_ SG_ 2589283772 TSL_Hinweis "Anzeige eines Textes, der auf Funktionsdegradierung hinweist, aber nicht zum Besuch der Werktstatt auffordert";
CM_ SG_ 2589283772 TSL_Warnung "Systemausfall mit Kundenwarnung";

CM_ SG_ 2589283773 TSR_Hinweis "Anzeige eines Textes, der auf Funktionsdegradierung hinweist, aber nicht zum Besuch der Werkstatt auffordert";
CM_ SG_ 2589283773 TSR_Temperatur_Oel "Aktuelle Hydrauli-Oel-Temperatur";
CM_ SG_ 2589283773 TSR_Thermische_Belastung "Maximale aktuelle thermische Belastung des Gesamtsystems (Motor, ECU, Kupplungen)";
CM_ SG_ 2589283773 TSR_Warnlampe "Status der Warnlampe: aktuell anliegender Fehlerzustand";
CM_ SG_ 2589283773 TSR_Warnung "Systemausfall mit Kundenwarnung";

CM_ SG_ 2463978710 OPS_ComfortReadyStatus "Das Signal wird durch den Basisdienst User State Server (Technikvariante: OccupantPresenceService) erzeugt und bildet einen neuen Zustand, bestehend aus einer Verknüpfung der Fahreranwesenheit (Fahrer abwesend / Fahrer anwesend) und der Klemmensteuerung (";
CM_ SG_ 2463978710 OPS_DriverPresenceStatus "Das Signal wird durch den Basisdienst User State Server (Service: OccupantPresenceService) erzeugt und bildet die Fahrerzustände im Fahrzeug ab.";
CM_ SG_ 2463978710 OPS_OccupantPresenceStatus "Das Signal wird durch den Basisdienst User State Server (Service: OccupantPresenceService) erzeugt und bildet die Anwesenheit und Abwesenheit aller Insassen im Fahrzeug ab.";
CM_ SG_ 2463978710 OPS_QBit_DriverPresence "Das Signal wird durch den Basisdienst User State Server (Service: OccupantPresenceService) erzeugt und signalisiert die Qualität der Fahrerzustände.";
CM_ SG_ 2463978710 OPS_SafeDriverPresence_available "Das Signal signalisiert inwiefern alle vorgesehene Sensoren  für die Anwesenheit verwendet werden oder möglichweise bestimmte Sensoren nicht verfügbar sind.
In beiden Fällen wird eine Anwesenheit berechnet, jedoch bei Ausfall bestimmter Sensoren kann zu ";
CM_ SG_ 2463978710 OPS_SafeDriverPresenceStatus "Signalisierung einer sicheren Fahreranwesenheit nach ASIL B";
CM_ SG_ 2463978710 UserStateServer_01_BZ "4bit Botschaftszähler, wird mit jeder Sendebotschaft inkrementiert";
CM_ SG_ 2463978710 UserStateServer_01_CRC "Für MLB:
Berechnung siehe Lastenheft 'Kommunikationsabsicherung für FlexRay und CAN'
Ab MQB und MLBevo:
Berechnung siehe Lastenheft 'End-to-End Kommunikationsabsicherung'

Endwerte siehe Begleitdokument 'S-PDU Kennungsfolgen'";

CM_ SG_ 995 VD_SpannungsAnf "Anforderung Forderung des Verdecks zur Spannungsanhebung des Bordnetzes.";
CM_ SG_ 995 VS_BFS_AutoHoch "automatischer Hochlauf des BFS Fenster ausgelöst durch die Verdecksteuerung";
CM_ SG_ 995 VS_BFS_AutoTief "automatischer Tieflauf des BFS Fenster ausgelöst durch die Verdecksteuerung";
CM_ SG_ 995 VS_BFS_ManHoch "manueller Hochlauf des BFS Fenster ausgelöst durch die Verdecksteuerung";
CM_ SG_ 995 VS_BFS_ManTief "manueller Tieflauf des BFS Fenster ausgelöst durch die Verdecksteuerung";
CM_ SG_ 995 VS_Buzzer "Buzzeransteuerung: 'Buzzeransteuerung' für Gong 200ms (Kombi)";
CM_ SG_ 995 VS_FH_BT_Langhub "Ansteuerung Fensterheber vom Verdecksteuergeraet";
CM_ SG_ 995 VS_FH_FT_Langhub "Ansteuerung Fensterheber vom Verdecksteuergeraet";
CM_ SG_ 995 VS_FH_HBFS_Langhub "Ansteuerung Fensterheber vom Verdecksteuergeraet";
CM_ SG_ 995 VS_FH_HFS_Langhub "Ansteuerung Fensterheber vom Verdecksteuergeraet";
CM_ SG_ 995 VS_FS_AutoHoch "automatischer Hochlauf des FS Fenster ausgelöst durch die Verdecksteuerung";
CM_ SG_ 995 VS_FS_AutoTief "automatischer Tieflauf des FS Fenster ausgelöst durch die Verdecksteuerung";
CM_ SG_ 995 VS_FS_ManHoch "manueller Hochlauf des FS Fenster ausgelöst durch die Verdecksteuerung";
CM_ SG_ 995 VS_FS_ManTief "manueller Tieflauf des FS Fenster ausgelöst durch die Verdecksteuerung";
CM_ SG_ 995 VS_Hardtop "Hardtop montiert";
CM_ SG_ 995 VS_HBFS_AutoHoch "automatischer Hochlauf des HBFS Fenster ausgelöst durch die Verdecksteuerung";
CM_ SG_ 995 VS_HBFS_AutoTief "automatischer Tieflauf des HBFS Fenster ausgelöst durch die Verdecksteuerung";
CM_ SG_ 995 VS_HBFS_ManHoch "manueller Hochlauf des HBFS Fenster ausgelöst durch die Verdecksteuerung";
CM_ SG_ 995 VS_HBFS_ManTief "manueller Tieflauf des HBFS Fenster ausgelöst durch die Verdecksteuerung";
CM_ SG_ 995 VS_HD_sperren "Bei gesetztem Signal wird der Kofferraum/Heckdeckel durch den BCM2 nicht entriegelt werden.";
CM_ SG_ 995 VS_Heckschloss_auf "Signal wird gesetzt, wenn fuer einen Verdeckbetrieb das Öffnen des Heckschlosses erforderlich ist.";
CM_ SG_ 995 VS_HFS_AutoHoch "automatischer Hochlauf des HFS Fenster ausgelöst durch die Verdecksteuerung";
CM_ SG_ 995 VS_HFS_AutoTief "automatischer Tieflauf des HFS Fenster ausgelöst durch die Verdecksteuerung";
CM_ SG_ 995 VS_HFS_ManHoch "manueller Hochlauf des HFS Fenster ausgelöst durch die Verdecksteuerung";
CM_ SG_ 995 VS_HFS_ManTief "manueller Tieflauf des HFS Fenster ausgelöst durch die Verdecksteuerung";
CM_ SG_ 995 VS_HHS_enable "Fehlende Beschreibung (Import)";
CM_ SG_ 995 VS_Lampe_Blk "Ansteuerung Lampe im Kombi

Wird aktiviert bei Aufprüfen, Verdecklauf und Fehlerfall (blinkend).


";
CM_ SG_ 995 VS_StartStopp_Info "Stopp-Freigabe und Start-Anforderung an den Start-Stopp-Koordinator";
CM_ SG_ 995 VS_VD_Bew_auf "



";
CM_ SG_ 995 VS_VD_Bew_zu "


";
CM_ SG_ 995 VS_VD_entriegelt "Zustand des Verdeck entriegelt";
CM_ SG_ 995 VS_VD_Fehler "Fehlerzustand Verdeck";
CM_ SG_ 995 VS_VD_offen_ver "Zustand des Verdecks verriegelt und offen";
CM_ SG_ 995 VS_VD_zu_ver "
";
CM_ SG_ 995 VS_VD_Zwischenposition "Verdeck in Zwischenposition";
CM_ SG_ 995 VS_VDKD_auf "Signal wird gesetzt, wenn der Verdeckkastendeckel vollstaendig geoeffnet ist



";
CM_ SG_ 995 VS_Verdeck_Anf "Verdeckanforderung (Signalisierung der Bereitschaft zur Verdeckbetaetigung ueber Komfortfunktion)";
CM_ SG_ 995 VS_Windschott_nicht_abgelegt "Windschott ist aufgestellt, in Zwischenposition oder die Position ist unbekannt";
CM_ SG_ 995 VSG_Meldungen "Meldungen fuers Kombi lt. konzernübergreifender Abstimmung

0 -> keine Meldung
1 -> 'Verdeckbetrieb RDW aktiv'
2 -> 'Verdeckbetrieb NAR aktiv'
3 -> 'stehendes Verdeck in Zwischenposition (ZP)'
4 -> 'autom. Verdeck in ZP und KL15 aus'
5 -> 'manuelle";

CM_ SG_ 1716 VIN_01_MUX "Achtung:
Die Botschaft ist nicht linear gemultiplext!!!
Sondern 0,1,0,2,0, usw.";
CM_ SG_ 1716 VIN_1 "Initwert:
0x2D bei Fahrzeugen mit Wegfahrsperrengeneration >= 5 
0x58 bei Fahrzeugen mit Wegfahrsperrengeneration < 5 (z.B. WFS-4)";
CM_ SG_ 1716 VIN_10 "Initwert:
0x2D bei Fahrzeugen mit Wegfahrsperrengeneration >= 5 
0x58 bei Fahrzeugen mit Wegfahrsperrengeneration < 5 (z.B. WFS-4)";
CM_ SG_ 1716 VIN_11 "Initwert:
0x2D bei Fahrzeugen mit Wegfahrsperrengeneration >= 5 
0x58 bei Fahrzeugen mit Wegfahrsperrengeneration < 5 (z.B. WFS-4)";
CM_ SG_ 1716 VIN_12 "Initwert:
0x2D bei Fahrzeugen mit Wegfahrsperrengeneration >= 5 
0x58 bei Fahrzeugen mit Wegfahrsperrengeneration < 5 (z.B. WFS-4)";
CM_ SG_ 1716 VIN_13 "Initwert:
0x2D bei Fahrzeugen mit Wegfahrsperrengeneration >= 5 
0x58 bei Fahrzeugen mit Wegfahrsperrengeneration < 5 (z.B. WFS-4)";
CM_ SG_ 1716 VIN_14 "Initwert:
0x2D bei Fahrzeugen mit Wegfahrsperrengeneration >= 5 
0x58 bei Fahrzeugen mit Wegfahrsperrengeneration < 5 (z.B. WFS-4)";
CM_ SG_ 1716 VIN_15 "Initwert:
0x2D bei Fahrzeugen mit Wegfahrsperrengeneration >= 5 
0x58 bei Fahrzeugen mit Wegfahrsperrengeneration < 5 (z.B. WFS-4)";
CM_ SG_ 1716 VIN_16 "Initwert:
0x2D bei Fahrzeugen mit Wegfahrsperrengeneration >= 5 
0x58 bei Fahrzeugen mit Wegfahrsperrengeneration < 5 (z.B. WFS-4)";
CM_ SG_ 1716 VIN_17 "Initwert:
0x2D bei Fahrzeugen mit Wegfahrsperrengeneration >= 5 
0x58 bei Fahrzeugen mit Wegfahrsperrengeneration < 5 (z.B. WFS-4)";
CM_ SG_ 1716 VIN_2 "Initwert:
0x2D bei Fahrzeugen mit Wegfahrsperrengeneration >= 5 
0x58 bei Fahrzeugen mit Wegfahrsperrengeneration < 5 (z.B. WFS-4)";
CM_ SG_ 1716 VIN_3 "Initwert:
0x2D bei Fahrzeugen mit Wegfahrsperrengeneration >= 5 
0x58 bei Fahrzeugen mit Wegfahrsperrengeneration < 5 (z.B. WFS-4)";
CM_ SG_ 1716 VIN_4 "Initwert:
0x2D bei Fahrzeugen mit Wegfahrsperrengeneration >= 5 
0x58 bei Fahrzeugen mit Wegfahrsperrengeneration < 5 (z.B. WFS-4)";
CM_ SG_ 1716 VIN_5 "Initwert:
0x2D bei Fahrzeugen mit Wegfahrsperrengeneration >= 5 
0x58 bei Fahrzeugen mit Wegfahrsperrengeneration < 5 (z.B. WFS-4)";
CM_ SG_ 1716 VIN_6 "Initwert:
0x2D bei Fahrzeugen mit Wegfahrsperrengeneration >= 5 
0x58 bei Fahrzeugen mit Wegfahrsperrengeneration < 5 (z.B. WFS-4)";
CM_ SG_ 1716 VIN_7 "Initwert:
0x2D bei Fahrzeugen mit Wegfahrsperrengeneration >= 5 
0x58 bei Fahrzeugen mit Wegfahrsperrengeneration < 5 (z.B. WFS-4)";
CM_ SG_ 1716 VIN_8 "Initwert:
0x2D bei Fahrzeugen mit Wegfahrsperrengeneration >= 5 
0x58 bei Fahrzeugen mit Wegfahrsperrengeneration < 5 (z.B. WFS-4)";
CM_ SG_ 1716 VIN_9 "Initwert:
0x2D bei Fahrzeugen mit Wegfahrsperrengeneration >= 5 
0x58 bei Fahrzeugen mit Wegfahrsperrengeneration < 5 (z.B. WFS-4)";

CM_ SG_ 1057 VLK_01_BZ "4bit Botschaftszähler, wird mit jeder Sendebotschaft inkrementiert";
CM_ SG_ 1057 VLK_01_CRC "Für MLB:
Berechnung siehe Lastenheft 'Kommunikationsabsicherung für FlexRay und CAN'
Ab MQB und MLBevo:
Berechnung siehe Lastenheft 'End-to-End Kommunikationsabsicherung'

Endwerte siehe Begleitdokument 'S-PDU Kennungsfolgen'";
CM_ SG_ 1057 VLK_Anf_Antrieb "Anforderung zur Antriebsfreigabe seitens VLK";
CM_ SG_ 1057 VLK_Anforderung_HMS "Halteanforderung des VLK an HMS aus Funktion Rollsicherung";
CM_ SG_ 1057 VLK_Anforderung_Rollfaehigkeit "Mit diesem Signal wird vom Verlassenskonzept signalisiert, ob der Rollfähigkeitsmodus aktiviert ist.";
CM_ SG_ 1057 VLK_Antriebsdeaktivierung "VLK kann mit diesem Signal den Antrieb deaktivieren.";
CM_ SG_ 1057 VLK_autom_Absch_Signalisierung "Signalisierung einer automatisierten Deaktivierung der Zündung";
CM_ SG_ 1057 VLK_Hinweis_dgr_VLW "Dieses Signal fordert im Kombi die Meldung an, die den Fahrer auffordert das Fahrzeug nur in Fahrstufe P zu verlassen. 
Notwendig wenn aufgrund fehlerhafter Eingangssignale keine automatische Sicherung erfolgt";
CM_ SG_ 1057 VLK_Hinweis_Fehler_Gurt "Dieses Signal fordert im Kombi die Meldung an, die den Fahrer über ein defektes Gurtschloss (Fahrergurt) informiert.";
CM_ SG_ 1057 VLK_Hinweis_Fehler_Sitz "Dieses Signal fordert im Kombi die Meldung an, die den Fahrer über eine defekte Sitzbelegungserkennung (Fahrersitz) informiert.";
CM_ SG_ 1057 VLK_Hinweis_Fehler_Tuer "Dieses Signal fordert im Kombi die Meldung an, die den Fahrer über einen defekten Türkontaktschalter (Fahrertür) informiert.";
CM_ SG_ 1057 VLK_Hinweis_KA_bevorstehend "Dieses Signal fordert im Kombi die Meldung an, die den Fahrer auf eine bevorstehende Komforabschaltung hinweist.";
CM_ SG_ 1057 VLK_Hinweis_Rollfaehigkeit "Im Signal wird die Meldungsausgabe des Rollfähigkeitsmodus im iID mit bzw. ohne Akustik angefordert";
CM_ SG_ 1057 VLK_Hinweis_Weiterfahrt "Dieses Signal fordert im Kombi die Meldung an, die den Fahrer auf eine Bedienhandlung zur Weiterfahrt hinweist.";
CM_ SG_ 1057 VLK_Parken_beibehalten_HMS "Anforderung durch das Verlassenskonzept, um das Lösen der Parkbremse zu verhindern.";
CM_ SG_ 1057 VLK_VLW_Anf "Anforderndes Signal der Verlassenswarnung für Fahrzeuge auf technischer Basis MEB. Aufgrund des nicht verbauten Getriebes sind die Signalwerte um die Ersatzreaktionen auf ein fehlerhaftes p_verriegelt reduziert. Ausgabe der Verlassenswarnung erfolgt im Fa";

CM_ SG_ 313 HMS_aktives_System "Zeigt an, von welchem System die Anforderung gerade umgesetzt wird.";
CM_ SG_ 313 HMS_Anforderung_GE "Fordert vom Getriebe bestimmte Schaltstellungen an.";
CM_ SG_ 313 HMS_Fehlerstatus "Zeigt den Fehlerstatus des Haltemanagementsystems HMS an.
Details zu den Werten 3/4:
3=Systemeinschränkung, Parken EPB oder GSG nicht möglich
4=Systemstörung bzw. Parken EPB und GSG nicht möglich  ";
CM_ SG_ 313 HMS_Haltemoment "Zeigt in Abhängigkeit von HMS_Index_Haltemoment das notwendige Summen-Radmoment an (bergab: Bremsmoment; bergauf: Antriebsmoment), das mindestens notwendig ist um das Fahrzeug an der aktuellen Neigung zu halten.";
CM_ SG_ 313 HMS_halten_nicht_verfuegbar "Rueckmeldung HMS-Teilfunktion 'Halten' nicht verfuegbar.";
CM_ SG_ 313 HMS_halten_nicht_verfuegbar_02 "Erweiterung des Signals 'HMS_halten_nicht_verfuegbar':
Für Remotevorgänge (Ein-, Ausparken, etc.) ohne anwesenden Fahrer soll das Signal eine Halteverfügbarkeit signalisieren durch 'verfuegbar_ohne_Fahrer'.";
CM_ SG_ 313 HMS_Index_Haltemoment "Zeigt an, ob das Summen-HMS_Haltemoment ein Bremsmoment (bergab) oder ein Antriebsmoment (bergauf) darstellt.";
CM_ SG_ 313 HMS_P_beibehalten_GE "Fordert das Getriebe auf in Stellung 'P' zu bleiben.";
CM_ SG_ 313 HMS_parken_nicht_verfuegbar "Rueckmeldung HMS-Teilfunktionen 'Parken' nicht verfuegbar.";
CM_ SG_ 313 HMS_Stillstand "Das Signal zeigt, basierend auf den vier ESP-Raddrehzahlinformatioen, gefiltert und/oder entprellt mehrstufig den Fahrzeuggeschwindigkeitszustand an.";
CM_ SG_ 313 HMS_Systemstatus "Zeigt den aktuellen Systemstatus des HMS an.";
CM_ SG_ 313 SOK_VMM_02_Signatur "Signatur im Rahmen der durch SOK geschützten Broadcast-Kommunikation

Geschützte Funktionen: Airbag-Funktionen, Bremsfunktionen
Geschützte Botschaft: VMM_02";
CM_ SG_ 313 VMM_02_BZ "4bit Botschaftszähler, wird mit jeder Sendebotschaft inkrementiert";
CM_ SG_ 313 VMM_02_CRC "Für MLB:
Berechnung siehe Lastenheft 'Kommunikationsabsicherung für FlexRay und CAN'
Ab MQB und MLBevo:
Berechnung siehe Lastenheft 'End-to-End Kommunikationsabsicherung'

Endwerte siehe Begleitdokument 'S-PDU Kennungsfolgen'";
CM_ SG_ 313 VMM_Bremslicht_defekt "Rückmeldung ob beide Bremslichter defekt sind. Bei gestecktem Anhänger werden die Anhängerbremslichter ausgewertet.";
CM_ SG_ 313 VMM_Bremslicht_unplausibel "Bremslichtplausibilität aus Basis der CAN Anforderung";
CM_ SG_ 313 VMM_Fahrer_Bremskraft_bestimmend "Dieses Signal gibt eine Rückmeldung ob der Fahrer stärker bremst als die angeforderte Bremsung.";
CM_ SG_ 313 VMM_Inkonsistenz_ACC "Rückmeldung Inkonsistenz ACC";
CM_ SG_ 313 VMM_Inkonsistenz_AEB "Rückmeldung Inkonsistenz vom AEB";
CM_ SG_ 313 VMM_Inkonsistenz_ARA "Rückmeldung Inkonsistenz ARA 1.0";
CM_ SG_ 313 VMM_Inkonsistenz_AWV_PCF "Rückmeldung Inkonsistenz AWV PCF";
CM_ SG_ 313 VMM_Inkonsistenz_EA "Rückmeldung Inkonsistenz EA";
CM_ SG_ 313 VMM_Inkonsistenz_EBKV "Rückmeldung Inkonsistenz EBKV";
CM_ SG_ 313 VMM_Inkonsistenz_FAS_VK "Rückmeldung Inkonsistenz Fahrerassistenzsystem";
CM_ SG_ 313 VMM_Inkonsistenz_GE "Zeigt an, ob die Kommunikation und die Anforderungen plausibel sind.";
CM_ SG_ 313 VMM_Inkonsistenz_HVLM "Rückmeldung Inkonsistenz HVLM";
CM_ SG_ 313 VMM_Inkonsistenz_KAM "Rückmeldung Inkonsistenz der Kamera";
CM_ SG_ 313 VMM_Inkonsistenz_KAS "Rückmeldung Inkonsistenz KAS";
CM_ SG_ 313 VMM_Inkonsistenz_MO "Rückmeldung Inkonsistenz MO";
CM_ SG_ 313 VMM_Inkonsistenz_NV "Rückmeldung Inkonsistenz Nightvision";
CM_ SG_ 313 VMM_Inkonsistenz_ParkAssist "Rückmeldung Inkonsistenz der Parkenden Systeme";
CM_ SG_ 313 VMM_Inkonsistenz_RCTA "Rückmeldung Inkonsistenz des RCTA";
CM_ SG_ 313 VMM_Inkonsistenz_RHP "Rückmeldung Inkonsistenz RHP (Rush Hour pilot).";
CM_ SG_ 313 VMM_Inkonsistenz_TSK "Rückmeldung Inkonsistenz TSK";
CM_ SG_ 313 VMM_Inkonsistenz_VLK "Rückmeldung Inkonsistenz VLK";
CM_ SG_ 313 VMM_MKB_codiert "Das Signal kennzeichnet den Codierstatus des ESC-SG bzgl. der Funktion Multikollisionsbremse.";
CM_ SG_ 313 VMM_Notstopp_Status "Status des Notstoppsystems";
CM_ SG_ 313 VZM_aktiver_Basisservice "In diesem Signal wird der aktive Basisservice des Verzögerungsmanagement zurück gegeben.";
CM_ SG_ 313 VZM_aktives_System "Rückmeldung über das  aktiv anfordernde System bei dem Verzögerungsmanagement.";
CM_ SG_ 313 VZM_Anhalteweg_nicht_verfuegbar "Rückmeldung ob die Anhaltewegregelung verfügbar ist.";
CM_ SG_ 313 VZM_Bkd_nicht_verfuegbar "Dieses Signal gibt eine Rückmeldung ob eine Bremsenkonditionierung (Prefill und Systemtotzeitminimierung) verfügbar ist.";
CM_ SG_ 313 VZM_Fahrer_bremst "Bit wird gesetzt beim Überschreiten der Bremsdruckschwelle

Weiterführende Informationen im Lastenheft spezifiziert und in der entsprechenden Fachabteilung zu erfragen.";
CM_ SG_ 313 VZM_Fahrer_bremst_deutlich "Rückmeldung an AWV ob der Fahrer das Bremspedal deutlich betätigt hat";
CM_ SG_ 313 VZM_QBit_Fahrer_bremst "Gültigkeit der Bremsdruckschwelleninformation des Signals VZM_Fahrer_bremst und VZM_Fahrer_bremst_deutlich
0x1 = Druckschwelleninformation kann noch nicht oder aufgrund eines Fehlers nicht ausgegeben werden";
CM_ SG_ 313 VZM_SRBM_Ist "Gibt das aktuelle Summenradbremsmoment aus.";
CM_ SG_ 313 VZM_SRBM_max_Gradient "Rückmeldung aktueller Maximalgradient";
CM_ SG_ 313 VZM_SRBM_Soll "Gibt das angeforderte Summenradbremsmoment aus.";
CM_ SG_ 313 VZM_Status_Wegregelung "Rückmeldung der Wegregelung ob dieser Service Inaktiv, aktiv oder passiv ist.
Bei Passiv_Überwachend Bremseingriff durch VZM im Notfall möglich.";
CM_ SG_ 313 VZM_Systemstatus "In diesem Signal wird der aktuelle Systemstatus des Verzögerungsmanagments ausgeben.";
CM_ SG_ 313 VZM_TSK_SRBM_Anf "Quittierung für TSK (SRBM = Summenradbremsmoment) Anforderung";
CM_ SG_ 313 VZM_TSK_SRBM_nicht_verfuegbar "Rückmeldung ob das ein Summenradbremsmoment angefordert werden kann.";
CM_ SG_ 313 VZM_Unterdrueckung_Antriebsmom "Mit diesem Signal wird dem TSK signalisiert ob ein positives Antriebsmoment angefordert werden kann. In einer Notbremsung ist das positive Antriebsmoment zu unterdrücken.";
CM_ SG_ 313 VZM_Verz_ASIL_Verfuegbarkeit "Dieses Signal gibt die Rückmeldung in welchem ASIL Bereich aktuell verzögert wird.";
CM_ SG_ 313 VZM_Verz_Begrenzung "Rückmeldung angeforderte Verzögerung oder Summenradbremsmoment wird begrenzt umgesetzt";
CM_ SG_ 313 VZM_Verz_Reg_aktiv "Rueckmeldung Verzoegerungsregelung aktiv";
CM_ SG_ 313 VZM_Verz_Reg_nicht_verfuegbar "In diesem Signal wird ausgegeben ob eine Verzögerungsregelung verfügbar ist.";
CM_ SG_ 313 VZM_Warnruck_nicht_verfuegbar "Rückmeldung ob ein einfacher Warnruck angefordert werden kann.";
CM_ SG_ 313 VZM_Warnruckeln_nicht_verfuegbar "Rückmeldung ob mehrfach ein Warnruck durchgeführt werden kann.";

CM_ SG_ 1702 BCM1_SRA_aktiv "Status Scheinwerferreinigungsanlage";
CM_ SG_ 1702 Heckwischer_Anforderung "Das Signal beschreibt die Anforderung an den Signalausgang im BCM2 zur Ansteuerung des Heckwischers.";
CM_ SG_ 1702 Waschen_vorne_aktiv "Status: Waschen vorne aktiv";
CM_ SG_ 1702 Wischer1_Wischgeschwindigkeit "aktuelle, durch Sensorik gemessene Wischgeschwindigkeit";
CM_ SG_ 1702 Wischer_Anzeigetext "Das Signal fordert einen Kombi-Pop-Up mit entsprechenden Texten an";
CM_ SG_ 1702 Wischer_vorne_aktiv "Status: Wischer vorne";
CM_ SG_ 1702 Wischer_vorne_blockiert "Blockade Wischer vorne (z.B. durch Schnee)";
CM_ SG_ 1702 Wischer_vorne_defekt "Fehlerstatus Wischer vorne (Anzeige im Kombi)";
CM_ SG_ 1702 Wischer_vorne_Normal "Wischer Front normal aktiv";
CM_ SG_ 1702 Wischer_vorne_Parklage "Wischer Front in Parklage";
CM_ SG_ 1702 Wischer_vorne_Schnell "Wischer vorne schnell aktiv";
CM_ SG_ 1702 Wischer_WH_PopUp_Anf "Anzeige von Wischerstufen im Kombi.";
CM_ SG_ 1702 Wischer_WH_Typ "Signal beinhaltet Lenkstockschaltertyp für grafische Anzeige im Kombi zur Wischerfunktion";
CM_ SG_ 1702 WWSs_01_alt "Veraltet Bit für die LIN-Botschaft WWSs_01.

Betroffene Signale:

Wischer_vorne_aktiv";

CM_ SG_ 1411 BCM_FH_Freigabe "Funktionsfreigabe Fensterheber";
CM_ SG_ 1411 BCM_HSK_Freigabe "Handschuhkastenfreigabe";
CM_ SG_ 1411 BCM_Komfortfkt_Freigabe "globale Freigabe der Komfortfunktion";
CM_ SG_ 1411 BCM_Tankklappensteller_Fehler "Fehler: nicht Funktionalität des Tankklappenstellers";
CM_ SG_ 1411 BCM_Verdeck_Freigabe "Freigabe Verdeckbetrieb
";
CM_ SG_ 1411 DWA_aktiv "Status DWA  aktiv";
CM_ SG_ 1411 FBS_IDG_in_Reichweite "Für elektrisch betätigte Türen und Klappen muss für eine Betätigung über Funk eine Reichweitenbegrenzung eingeführt werden. Diese Bit zeigt an, dass sich der Funkschlüssel innerhalb der geforderten Reichweite befindet";
CM_ SG_ 1411 FBS_Warn_Schluessel_Batt "Kombi Prio Warnung Schluessel Batterie
'Bitte Schlüsselbatterie wechseln!'";
CM_ SG_ 1411 FFB_Auf_Taste "Auf-Taste Funkschluessel

";
CM_ SG_ 1411 FFB_CarFinder "Car Finder Funktion (Blinken ohne zu entriegeln)";
CM_ SG_ 1411 FFB_HDF_Taste "HDF Taste am Funkschluessel
";
CM_ SG_ 1411 FFB_Komfortoeffnen "Komfortoeffnen Funk
";
CM_ SG_ 1411 FFB_Komfortschliessen "Komfortschliessen Funk
";
CM_ SG_ 1411 FFB_Panik_Taste "Panik Taste Funkschluessel
";
CM_ SG_ 1411 FFB_Zu_Taste "Zu-Taste Funkschluessel
";
CM_ SG_ 1411 HBFS_gesafet "HBFS Tuer gesafet.
Im Zustand Safe wird auch das Signal HBFS_verriegelt = 1 gesendet.";
CM_ SG_ 1411 HBFS_verriegelt "Verriegelungsstatus Tür";
CM_ SG_ 1411 HD_Hauptraste "SBL-Schloss (MQB/MLBevo): Drehfalle Heckdeckel
sonst (MQB): Hauptraste Heckdeckel";
CM_ SG_ 1411 HD_Vorraste "SBL_Schloss (MQB/MLBevo): Sperrklinke Heckdeckel
sonst (MQB): Vorraste Heckdeckel";
CM_ SG_ 1411 HFS_gesafet "HFS Tuer gesafet.
Im Zustand Safe wird auch das Signal HFS_verriegelt = 1 gesendet.";
CM_ SG_ 1411 HFS_verriegelt "HFS Tuer verriegelt";
CM_ SG_ 1411 IRUE_aktiv "Status Innenraumüberwachung
";
CM_ SG_ 1411 IRUE_Taster_Fkts_LED "Anforderung Funktions-LED IRUE-Taster (LED wird vom TSG angesteuert)
MQB: Bei Verbau eines einzelnen Taster zur Deaktivierung von IRUE und NGS wird dieses Signal zur Ansteuerung der Funktions-LED gesendet.";
CM_ SG_ 1411 VIP_Sensor_STSG_HBFS_betaetigt "Schiebetürlauf HBFS wurde durch VIP angefordert und als berechtigt eingestuft.";
CM_ SG_ 1411 VIP_Sensor_STSG_HFS_betaetigt "Schiebetürlauf HFS wurde durch VIP angefordert und als berechtigt eingestuft.";
CM_ SG_ 1411 ZV_Anf_Challenge_Auth "Anforderung an alle beteiligten Steuergeräte die Challenge an den ZV-Master zu senden.";
CM_ SG_ 1411 ZV_BT_offen "gespiegeltes Bit BT_Tuer_geoeffnet TSG_BT_1 Botschaft";
CM_ SG_ 1411 ZV_Einzeltuerentriegelung "Einzeltürentriegelung ZV
";
CM_ SG_ 1411 ZV_eRWK_Umfeld_Pruefung "Anforderung an PDC/PLA im eRWK-Modus eine Umfeldprüfung durchzuführen";
CM_ SG_ 1411 ZV_FT_offen "gespiegeltes Bit FT_Tuer_geoeffnet TSG_FT_1 Botschaft";
CM_ SG_ 1411 ZV_gesafet_extern_ist "Istzustand: Fahrzeug aussen gesafet
";
CM_ SG_ 1411 ZV_gesafet_extern_soll "Sollzustand: Fahrzeug gesafet extern
";
CM_ SG_ 1411 ZV_HBFS_offen "gespiegeltes Bit HBFS_Tuer_geoeffnet TSG_HBFS_1 Botschaft";
CM_ SG_ 1411 ZV_HD_offen "Status Heckdeckel
";
CM_ SG_ 1411 ZV_Heckeinzelentriegelung "Heckdeckeleinzelentriegelung";
CM_ SG_ 1411 ZV_HFS_offen "gespiegeltes Bit HFS_Tuer_geoeffnet TSG_HFS_1 Botschaft";
CM_ SG_ 1411 ZV_HS_offen "Status Heckscheibe
";
CM_ SG_ 1411 ZV_ist_Zustand_verfuegbar "Verfügbarkeit IST-Zustand ZV

";
CM_ SG_ 1411 ZV_Oeffnungsmodus "Konfigurierter Oeffnungsmodus fuer ZV:
0 = globale Oeffnung (alle Tueren)
1 = ZV mit Einzeltuerentriegelung (FFB - nur Fahrertuer, Kessy - nur bediente Tuer)
2 = ZV individuell selektive Oeffnung (FFB - Fahrerseite, Kessy - bediente Tuer + Fahrertuer)";
CM_ SG_ 1411 ZV_Rollo_auf "Komfortöffnen des Dachrollos";
CM_ SG_ 1411 ZV_Rollo_zu "Komfortschließen des Dachrollos";
CM_ SG_ 1411 ZV_SAD_auf "Komfortöffnen des Schiebeausstelldaches";
CM_ SG_ 1411 ZV_SAD_zu "Komfortschließen des Schiebeausstelldaches";
CM_ SG_ 1411 ZV_SafeFunktion_aktiv "Statusübermittlung ob die Safe Funktion im Fzg. aktiv ist. Das Kombi benötigt das Signal, um den Text Safelock aktiv anzuzeigen. ";
CM_ SG_ 1411 ZV_Schluessel_Zugang "aktuelle Funkschlüsselnummer";
CM_ SG_ 1411 ZV_STSG_Crashzustand "Statusübermittlung ob der Crashzustand der Schiebetüren dauerhaft im Fzg. aktiv ist. Das Kombi benötigt das Signal, um die Meldung anzuzeigen.";
CM_ SG_ 1411 ZV_STSG_eKiSi_defekt "Statusübermittlung ob die elektronische Kindersicherung der Schiebetüren im Fzg. defekt ist. Das Kombi benötigt das Signal, um die Meldung anzuzeigen.";
CM_ SG_ 1411 ZV_STSG_HBFS_Anf "Die ZV fordert einen Lauf bzw. Stopp der Schiebetür an.";
CM_ SG_ 1411 ZV_STSG_HFS_Anf "Die ZV fordert einen Lauf bzw. Stopp der Schiebetür an.";
CM_ SG_ 1411 ZV_Tankklappe_offen "Öffnungsstatus der Tankklappe";
CM_ SG_ 1411 ZV_verriegeln_Anf "Gesammelte externe ZV-Verriegelungsanforderung des Kunden (z. B. zur Aktivierung der Anzeige des Ladezustands über Aussenlicht).";
CM_ SG_ 1411 ZV_verriegelt_extern_ist "Istzustand: Verriegelung Fahrzeug aussen
";
CM_ SG_ 1411 ZV_verriegelt_extern_soll "Sollzustand: Verriegelung Fahrzeug aussen
";
CM_ SG_ 1411 ZV_verriegelt_intern_ist "Istzustand: Verriegelung Fahrzeug innen
";
CM_ SG_ 1411 ZV_verriegelt_intern_soll "Sollzustand: Verriegelung Fahrzeug innen
";
CM_ SG_ 1411 ZV_verriegelt_soll "Fahrzeug Gesamtverriegelungsstatus Sollzustand für Ladestecker- und Ladeklappenverriegelung. ";
BA_DEF_REL_ BU_SG_REL_  "GenSigTimeoutTime" INT 0 65535;
BA_DEF_ BO_  "DiagRequest" ENUM "No", "Yes";
BA_DEF_ BO_  "DiagResponse" ENUM "No", "Yes";
BA_DEF_ BO_  "DiagState" ENUM "No", "Yes";
BA_DEF_ BO_  "GenMsgChkConstant" HEX 0 4095;
BA_DEF_ BO_  "GenMsgCycleTime" INT 0 65535;
BA_DEF_ BO_  "GenMsgCycleTimeFast" INT 0 65535;
BA_DEF_ BO_  "GenMsgDelayTime" INT 0 100000;
BA_DEF_ BO_  "GenMsgILSupport" ENUM "No", "Yes";
BA_DEF_ BO_  "GenMsgNrOfRepetition" INT 0 100;
BA_DEF_ BO_  "GenMsgPDUConstants" STRING;
BA_DEF_ BO_  "GenMsgSendType" ENUM "Cyclic", "not_used", "not_used", "not_used", "not_used", "not_used", "not_used", "IfActive", "NoMsgSendType";
BA_DEF_ BO_  "GenMsgStartDelayTime" INT 0 100000;
BA_DEF_ BO_  "NmMessage" ENUM "No", "Yes";
BA_DEF_ BO_  "NmhMessage" ENUM "No", "Yes";
BA_DEF_ BO_  "MsgType" ENUM "Application", "NM ", "NMH", "TP2.0", "ISO-TP ", "BAP", "EID", "KS", "XCP_PRE_CONFIGURED", "XCP_RUNTIME_CONFIGURED";
BA_DEF_ BO_  "VAGTP20_API" HEX 0 255;
BA_DEF_ BO_  "VAGTP20_DynConnection" ENUM "No", "Yes";
BA_DEF_ BO_  "VAGTP20_DynSetup" ENUM "No", "Yes";
BA_DEF_ BO_  "VAGTP20_StatConnection" ENUM "No", "Yes";
BA_DEF_ BO_  "CANFD_BRS" ENUM "0", "1";
BA_DEF_ BO_  "VFrameFormat" ENUM "StandardCAN", "ExtendedCAN", "reserved", "reserved", "reserved", "reserved", "reserved", "reserved", "reserved", "reserved", "reserved", "reserved", "reserved", "reserved", "StandardCAN_FD", "ExtendedCAN_FD";
BA_DEF_ SG_  "GenSigActiveRepetitions" INT -2147483648 2147483647;
BA_DEF_ SG_  "GenSigInactiveValue" INT -2147483648 2147483647;
BA_DEF_ SG_  "GenSigSendType" ENUM "Cyclic", "OnWrite", "OnWriteWithRepetition", "OnChange", "OnChangeWithRepetition", "IfActive", "IfActiveWithRepetition", "NoSigSendType", "OnChangeAndIfActive", "OnChangeAndIfActiveWithRepetition";
BA_DEF_ SG_  "GenSigStartValue" INT -2147483648 2147483647;
BA_DEF_ SG_  "NWM-WakeupAllowed" ENUM "No", "Yes";
BA_DEF_ SG_  "GenSigFuncType" ENUM "NoFunction", "MsgCounter", "CRC-8", "XOR", "XOR-2", "DatedBit", "SW-Kl15", "CHK", "Constant", "Protocol", "CRC-8-SAE_J1850", "CRC-32", "DataLength", "DataID", "MsgCounter16", "SOK-Signatur", "Cluster";
BA_DEF_ SG_  "GenSigSwitchedByIgnition" ENUM "No", "Yes";
BA_DEF_ SG_  "Fehlerwert" HEX 0 2147483647;
BA_DEF_ SG_  "GenSigMissingSourceValue" HEX 0 2147483647;
BA_DEF_DEF_REL_  "GenSigTimeoutTime" 0;
BA_DEF_DEF_  "DiagRequest" "No";
BA_DEF_DEF_  "DiagResponse" "No";
BA_DEF_DEF_  "DiagState" "No";
BA_DEF_DEF_  "GenMsgChkConstant" 0;
BA_DEF_DEF_  "GenMsgCycleTime" 0;
BA_DEF_DEF_  "GenMsgCycleTimeFast" 0;
BA_DEF_DEF_  "GenMsgDelayTime" 0;
BA_DEF_DEF_  "GenMsgILSupport" "No";
BA_DEF_DEF_  "GenMsgNrOfRepetition" 0;
BA_DEF_DEF_  "GenMsgPDUConstants" "";
BA_DEF_DEF_  "GenMsgSendType" "NoMsgSendType";
BA_DEF_DEF_  "GenMsgStartDelayTime" 0;
BA_DEF_DEF_  "NmMessage" "No";
BA_DEF_DEF_  "NmhMessage" "No";
BA_DEF_DEF_  "MsgType" "Application";
BA_DEF_DEF_  "VAGTP20_API" 0;
BA_DEF_DEF_  "VAGTP20_DynConnection" "No";
BA_DEF_DEF_  "VAGTP20_DynSetup" "No";
BA_DEF_DEF_  "VAGTP20_StatConnection" "No";
BA_DEF_DEF_  "CANFD_BRS" "1";
BA_DEF_DEF_  "VFrameFormat" "StandardCAN";
BA_DEF_DEF_  "GenSigActiveRepetitions" 0;
BA_DEF_DEF_  "GenSigInactiveValue" 0;
BA_DEF_DEF_  "GenSigSendType" "NoSigSendType";
BA_DEF_DEF_  "GenSigStartValue" 0;
BA_DEF_DEF_  "NWM-WakeupAllowed" "No";
BA_DEF_DEF_  "GenSigFuncType" "NoFunction";
BA_DEF_DEF_  "GenSigSwitchedByIgnition" "Yes";
BA_DEF_DEF_  "Fehlerwert" 0;
BA_DEF_DEF_  "GenSigMissingSourceValue" 0;
BA_ "GenMsgCycleTime" BO_ 565 20;
BA_ "GenMsgSendType" BO_ 565 0;
BA_ "VFrameFormat" BO_ 565 14;
BA_ "MsgType" BO_ 2033 4;
BA_ "CANFD_BRS" BO_ 2033 0;
BA_ "MsgType" BO_ 2041 4;
BA_ "CANFD_BRS" BO_ 2041 0;
BA_ "GenMsgCycleTime" BO_ 2264486920 20;
BA_ "GenMsgILSupport" BO_ 2264486920 1;
BA_ "GenMsgPDUConstants" BO_ 2264486920 "0x41,0x87,0x40,0x5d,0x39,0xbe,0x1b,0x88,0x76,0xf9,0xb3,0x17,0xb6,0x0a,0xd8,0x84";
BA_ "GenMsgSendType" BO_ 2264486920 0;
BA_ "VFrameFormat" BO_ 2264486920 15;
BA_ "GenMsgCycleTime" BO_ 2527679688 2000;
BA_ "GenMsgDelayTime" BO_ 2527679688 100;
BA_ "GenMsgILSupport" BO_ 2527679688 1;
BA_ "GenMsgSendType" BO_ 2527679688 0;
BA_ "VFrameFormat" BO_ 2527679688 15;
BA_ "GenMsgCycleTime" BO_ 1610 500;
BA_ "GenMsgILSupport" BO_ 1610 1;
BA_ "GenMsgSendType" BO_ 1610 0;
BA_ "VFrameFormat" BO_ 1610 14;
BA_ "GenMsgDelayTime" BO_ 2589283756 100;
BA_ "GenMsgILSupport" BO_ 2589283756 1;
BA_ "VFrameFormat" BO_ 2589283756 15;
BA_ "GenMsgDelayTime" BO_ 2464153619 100;
BA_ "GenMsgILSupport" BO_ 2464153619 1;
BA_ "VFrameFormat" BO_ 2464153619 15;
BA_ "GenMsgDelayTime" BO_ 2464284691 100;
BA_ "GenMsgILSupport" BO_ 2464284691 1;
BA_ "VFrameFormat" BO_ 2464284691 15;
BA_ "GenMsgDelayTime" BO_ 2464153621 100;
BA_ "GenMsgILSupport" BO_ 2464153621 1;
BA_ "VFrameFormat" BO_ 2464153621 15;
BA_ "GenMsgDelayTime" BO_ 2464284693 100;
BA_ "GenMsgILSupport" BO_ 2464284693 1;
BA_ "VFrameFormat" BO_ 2464284693 15;
BA_ "GenMsgDelayTime" BO_ 2464153659 100;
BA_ "GenMsgILSupport" BO_ 2464153659 1;
BA_ "VFrameFormat" BO_ 2464153659 15;
BA_ "GenMsgDelayTime" BO_ 2464284731 100;
BA_ "GenMsgILSupport" BO_ 2464284731 1;
BA_ "VFrameFormat" BO_ 2464284731 15;
BA_ "GenMsgCycleTime" BO_ 1413 1000;
BA_ "GenMsgDelayTime" BO_ 1413 10;
BA_ "GenMsgILSupport" BO_ 1413 1;
BA_ "GenMsgSendType" BO_ 1413 0;
BA_ "VFrameFormat" BO_ 1413 14;
BA_ "GenMsgCycleTime" BO_ 165 100;
BA_ "GenMsgDelayTime" BO_ 165 10;
BA_ "GenMsgILSupport" BO_ 165 1;
BA_ "GenMsgSendType" BO_ 165 0;
BA_ "VFrameFormat" BO_ 165 14;
BA_ "GenMsgCycleTime" BO_ 1447 1000;
BA_ "GenMsgCycleTimeFast" BO_ 1447 100;
BA_ "GenMsgDelayTime" BO_ 1447 50;
BA_ "GenMsgILSupport" BO_ 1447 1;
BA_ "GenMsgSendType" BO_ 1447 0;
BA_ "VFrameFormat" BO_ 1447 14;
BA_ "GenMsgCycleTime" BO_ 997 100;
BA_ "GenMsgDelayTime" BO_ 997 20;
BA_ "GenMsgILSupport" BO_ 997 1;
BA_ "GenMsgPDUConstants" BO_ 997 "0xc4,0x6a,0x69,0x30,0xcf,0x61,0x58,0x51,0x1b,0x86,0x99,0xd3,0xf6,0x1d,0x9a,0x37";
BA_ "GenMsgSendType" BO_ 997 0;
BA_ "VFrameFormat" BO_ 997 14;
BA_ "GenMsgCycleTime" BO_ 2589283772 1000;
BA_ "GenMsgILSupport" BO_ 2589283772 1;
BA_ "GenMsgSendType" BO_ 2589283772 0;
BA_ "VFrameFormat" BO_ 2589283772 15;
BA_ "GenMsgCycleTime" BO_ 2589283773 1000;
BA_ "GenMsgILSupport" BO_ 2589283773 1;
BA_ "GenMsgSendType" BO_ 2589283773 0;
BA_ "VFrameFormat" BO_ 2589283773 15;
BA_ "GenMsgCycleTime" BO_ 2463978710 100;
BA_ "GenMsgCycleTimeFast" BO_ 2463978710 10;
BA_ "GenMsgDelayTime" BO_ 2463978710 10;
BA_ "GenMsgILSupport" BO_ 2463978710 1;
BA_ "GenMsgNrOfRepetition" BO_ 2463978710 5;
BA_ "GenMsgPDUConstants" BO_ 2463978710 "0xf3,0xbb,0x4c,0x48,0x05,0x08,0x69,0xc8,0x60,0x76,0x27,0x02,0x3a,0xa8,0x32,0x51";
BA_ "GenMsgSendType" BO_ 2463978710 0;
BA_ "VFrameFormat" BO_ 2463978710 15;
BA_ "GenMsgCycleTime" BO_ 995 100;
BA_ "GenMsgCycleTimeFast" BO_ 995 50;
BA_ "GenMsgDelayTime" BO_ 995 50;
BA_ "GenMsgILSupport" BO_ 995 1;
BA_ "GenMsgNrOfRepetition" BO_ 995 5;
BA_ "GenMsgSendType" BO_ 995 0;
BA_ "VFrameFormat" BO_ 995 14;
BA_ "GenMsgCycleTime" BO_ 1716 200;
BA_ "GenMsgILSupport" BO_ 1716 1;
BA_ "GenMsgSendType" BO_ 1716 0;
BA_ "VFrameFormat" BO_ 1716 14;
BA_ "GenMsgCycleTime" BO_ 1057 100;
BA_ "GenMsgDelayTime" BO_ 1057 50;
BA_ "GenMsgILSupport" BO_ 1057 1;
BA_ "GenMsgPDUConstants" BO_ 1057 "0x8e,0x95,0xed,0x45,0x8d,0x80,0x23,0x35,0x30,0x56,0x14,0xf1,0x38,0x42,0xba,0x1d";
BA_ "GenMsgSendType" BO_ 1057 0;
BA_ "VFrameFormat" BO_ 1057 14;
BA_ "GenMsgCycleTime" BO_ 313 20;
BA_ "GenMsgILSupport" BO_ 313 1;
BA_ "GenMsgPDUConstants" BO_ 313 "0x96,0x92,0x95,0xb5,0x6e,0xe3,0xbd,0xb4,0xfa,0xae,0xbe,0xcb,0xcf,0xa5,0x77,0xef";
BA_ "GenMsgSendType" BO_ 313 0;
BA_ "VFrameFormat" BO_ 313 14;
BA_ "GenMsgCycleTime" BO_ 1702 1000;
BA_ "GenMsgDelayTime" BO_ 1702 50;
BA_ "GenMsgILSupport" BO_ 1702 1;
BA_ "GenMsgSendType" BO_ 1702 0;
BA_ "VFrameFormat" BO_ 1702 14;
BA_ "MsgType" BO_ 2617028096 8;
BA_ "VFrameFormat" BO_ 2617028096 15;
BA_ "MsgType" BO_ 2617028097 9;
BA_ "VFrameFormat" BO_ 2617028097 15;
BA_ "MsgType" BO_ 2617218560 6;
BA_ "VFrameFormat" BO_ 2617218560 15;
BA_ "MsgType" BO_ 2617218562 6;
BA_ "VFrameFormat" BO_ 2617218562 15;
BA_ "MsgType" BO_ 2617218561 6;
BA_ "VFrameFormat" BO_ 2617218561 15;
BA_ "MsgType" BO_ 2617218563 6;
BA_ "VFrameFormat" BO_ 2617218563 15;
BA_ "MsgType" BO_ 2617105920 8;
BA_ "VFrameFormat" BO_ 2617105920 15;
BA_ "MsgType" BO_ 2617105921 9;
BA_ "VFrameFormat" BO_ 2617105921 15;
BA_ "MsgType" BO_ 2617024016 8;
BA_ "VFrameFormat" BO_ 2617024016 15;
BA_ "MsgType" BO_ 2617024017 9;
BA_ "VFrameFormat" BO_ 2617024017 15;
BA_ "MsgType" BO_ 2617021952 8;
BA_ "VFrameFormat" BO_ 2617021952 15;
BA_ "MsgType" BO_ 2617021953 9;
BA_ "VFrameFormat" BO_ 2617021953 15;
BA_ "GenMsgCycleTime" BO_ 1411 200;
BA_ "GenMsgCycleTimeFast" BO_ 1411 50;
BA_ "GenMsgDelayTime" BO_ 1411 20;
BA_ "GenMsgILSupport" BO_ 1411 1;
BA_ "GenMsgNrOfRepetition" BO_ 1411 3;
BA_ "GenMsgSendType" BO_ 1411 0;
BA_ "VFrameFormat" BO_ 1411 14;
BA_ "GenSigSendType" SG_ 565 Kam_aktiv_Anforderung_HMS 0;
BA_ "GenSigSwitchedByIgnition" SG_ 565 Kam_aktiv_Anforderung_HMS 0;
BA_ "GenSigSendType" SG_ 565 Kam_aktiv_Anhalteweg_Anf 0;
BA_ "GenSigStartValue" SG_ 565 Kam_aktiv_Anhalteweg_Anf 1022;
BA_ "GenSigSwitchedByIgnition" SG_ 565 Kam_aktiv_Anhalteweg_Anf 0;
BA_ "Fehlerwert" SG_ 565 Kam_aktiv_Anhalteweg_Anf 1023;
BA_ "GenSigSendType" SG_ 565 Kam_aktiv_BKD_Anf 0;
BA_ "GenSigStartValue" SG_ 565 Kam_aktiv_BKD_Anf 14;
BA_ "GenSigSwitchedByIgnition" SG_ 565 Kam_aktiv_BKD_Anf 0;
BA_ "Fehlerwert" SG_ 565 Kam_aktiv_BKD_Anf 15;
BA_ "GenSigSendType" SG_ 565 Kam_aktiv_Notstopp_Anf 0;
BA_ "GenSigSwitchedByIgnition" SG_ 565 Kam_aktiv_Notstopp_Anf 0;
BA_ "GenSigSendType" SG_ 565 Kam_aktiv_parken_beibehalten 0;
BA_ "GenSigStartValue" SG_ 565 Kam_aktiv_parken_beibehalten 2;
BA_ "GenSigSwitchedByIgnition" SG_ 565 Kam_aktiv_parken_beibehalten 0;
BA_ "Fehlerwert" SG_ 565 Kam_aktiv_parken_beibehalten 3;
BA_ "GenSigSendType" SG_ 565 Kam_aktiv_Prefill_Anf 0;
BA_ "GenSigSwitchedByIgnition" SG_ 565 Kam_aktiv_Prefill_Anf 0;
BA_ "GenSigSendType" SG_ 565 Kam_aktiv_Soll_Anhalteweg_Anf 0;
BA_ "GenSigStartValue" SG_ 565 Kam_aktiv_Soll_Anhalteweg_Anf 1022;
BA_ "GenSigSwitchedByIgnition" SG_ 565 Kam_aktiv_Soll_Anhalteweg_Anf 0;
BA_ "Fehlerwert" SG_ 565 Kam_aktiv_Soll_Anhalteweg_Anf 1023;
BA_ "GenSigSendType" SG_ 565 Kam_aktiv_Verz_Anf 0;
BA_ "GenSigStartValue" SG_ 565 Kam_aktiv_Verz_Anf 126;
BA_ "GenSigSwitchedByIgnition" SG_ 565 Kam_aktiv_Verz_Anf 0;
BA_ "GenSigSendType" SG_ 565 Kam_aktiv_Verz_Anf_ASIL 0;
BA_ "GenSigSwitchedByIgnition" SG_ 565 Kam_aktiv_Verz_Anf_ASIL 0;
BA_ "GenSigSendType" SG_ 565 Kam_aktiv_Warnruck_Anf 0;
BA_ "GenSigSwitchedByIgnition" SG_ 565 Kam_aktiv_Warnruck_Anf 0;
BA_ "GenSigSendType" SG_ 565 Kam_aktiv_Warnruckeln_Anf 0;
BA_ "GenSigSwitchedByIgnition" SG_ 565 Kam_aktiv_Warnruckeln_Anf 0;
BA_ "GenSigSendType" SG_ 565 Kam_aktives_System 0;
BA_ "GenSigSwitchedByIgnition" SG_ 565 Kam_aktives_System 0;
BA_ "GenSigSendType" SG_ 2264486920 RHP_01_BZ 0;
BA_ "GenSigFuncType" SG_ 2264486920 RHP_01_BZ 1;
BA_ "GenSigSwitchedByIgnition" SG_ 2264486920 RHP_01_BZ 0;
BA_ "GenSigSendType" SG_ 2264486920 RHP_01_CRC 0;
BA_ "GenSigFuncType" SG_ 2264486920 RHP_01_CRC 2;
BA_ "GenSigSwitchedByIgnition" SG_ 2264486920 RHP_01_CRC 0;
BA_ "GenSigSendType" SG_ 2264486920 RHP_Anf_ASIL 0;
BA_ "GenSigSendType" SG_ 2264486920 RHP_Anforderung_HMS 0;
BA_ "GenSigSwitchedByIgnition" SG_ 2264486920 RHP_Anforderung_HMS 0;
BA_ "GenSigSendType" SG_ 2264486920 RHP_EA_AnfStat 0;
BA_ "GenSigSendType" SG_ 2264486920 RHP_EA_eCall 0;
BA_ "GenSigSendType" SG_ 2264486920 RHP_EA_Innenraumlicht 0;
BA_ "GenSigSendType" SG_ 2264486920 RHP_EA_PreCrash 0;
BA_ "GenSigSendType" SG_ 2264486920 RHP_EA_Tueren 0;
BA_ "GenSigSendType" SG_ 2264486920 RHP_eCall_Anf 0;
BA_ "GenSigSwitchedByIgnition" SG_ 2264486920 RHP_eCall_Anf 0;
BA_ "GenSigSendType" SG_ 2264486920 RHP_Fahrzeughupe_Anf 0;
BA_ "GenSigSwitchedByIgnition" SG_ 2264486920 RHP_Fahrzeughupe_Anf 0;
BA_ "GenSigSendType" SG_ 2264486920 RHP_Freilaufstrategie_TSK 0;
BA_ "GenSigSendType" SG_ 2264486920 RHP_HOS 0;
BA_ "GenSigSendType" SG_ 2264486920 RHP_Innenraumlicht_Anf 0;
BA_ "GenSigSendType" SG_ 2264486920 RHP_Minimale_Bremsung 0;
BA_ "GenSigSendType" SG_ 2264486920 RHP_nachtr_Stopp_Anf 0;
BA_ "GenSigSwitchedByIgnition" SG_ 2264486920 RHP_nachtr_Stopp_Anf 0;
BA_ "GenSigSendType" SG_ 2264486920 RHP_neg_Sollbeschl_Grad 0;
BA_ "GenSigSendType" SG_ 2264486920 RHP_OPSEnable 0;
BA_ "GenSigSwitchedByIgnition" SG_ 2264486920 RHP_OPSEnable 0;
BA_ "GenSigSendType" SG_ 2264486920 RHP_Parking_St 0;
BA_ "GenSigSwitchedByIgnition" SG_ 2264486920 RHP_Parking_St 0;
BA_ "GenSigSendType" SG_ 2264486920 RHP_pos_Sollbeschl_Grad 0;
BA_ "GenSigSwitchedByIgnition" SG_ 2264486920 RHP_pos_Sollbeschl_Grad 0;
BA_ "GenSigSendType" SG_ 2264486920 RHP_PreCrash_Anf 0;
BA_ "GenSigSendType" SG_ 2264486920 RHP_QFK_AnfStat 0;
BA_ "GenSigStartValue" SG_ 2264486920 RHP_QFK_AnfStat 1;
BA_ "GenSigSendType" SG_ 2264486920 RHP_QFK_Art1 0;
BA_ "GenSigSwitchedByIgnition" SG_ 2264486920 RHP_QFK_Art1 0;
BA_ "GenSigSendType" SG_ 2264486920 RHP_QFK_Art2 0;
BA_ "GenSigSendType" SG_ 2264486920 RHP_QFK_KrSoll 0;
BA_ "GenSigSendType" SG_ 2264486920 RHP_QFK_KrSoll_VZ 0;
BA_ "GenSigSendType" SG_ 2264486920 RHP_QFK_KruemmSoll 0;
BA_ "GenSigSendType" SG_ 2264486920 RHP_QFK_KruemmSoll_VZ 0;
BA_ "GenSigSendType" SG_ 2264486920 RHP_QFK_Signal1 0;
BA_ "GenSigSwitchedByIgnition" SG_ 2264486920 RHP_QFK_Signal1 0;
BA_ "GenSigSendType" SG_ 2264486920 RHP_QFK_Signal2 0;
BA_ "GenSigSendType" SG_ 2264486920 RHP_QFK_Spuerb 0;
BA_ "GenSigSendType" SG_ 2264486920 RHP_RBF_Available 0;
BA_ "GenSigSwitchedByIgnition" SG_ 2264486920 RHP_RBF_Available 0;
BA_ "GenSigSendType" SG_ 2264486920 RHP_Ruckfreigabe 0;
BA_ "GenSigSwitchedByIgnition" SG_ 2264486920 RHP_Ruckfreigabe 0;
BA_ "GenSigSendType" SG_ 2264486920 RHP_SCAM_HeatingRequest 0;
BA_ "GenSigSendType" SG_ 2264486920 RHP_Sollbeschleunigung 0;
BA_ "GenSigStartValue" SG_ 2264486920 RHP_Sollbeschleunigung 2046;
BA_ "Fehlerwert" SG_ 2264486920 RHP_Sollbeschleunigung 2047;
BA_ "GenSigSendType" SG_ 2264486920 RHP_Spurwechsel_Ready 0;
BA_ "GenSigSwitchedByIgnition" SG_ 2264486920 RHP_Spurwechsel_Ready 0;
BA_ "GenSigSendType" SG_ 2264486920 RHP_StartStopp_Info 0;
BA_ "GenSigSendType" SG_ 2264486920 RHP_Status_Function 0;
BA_ "GenSigSwitchedByIgnition" SG_ 2264486920 RHP_Status_Function 0;
BA_ "GenSigSendType" SG_ 2264486920 RHP_Status_Lat 0;
BA_ "GenSigSendType" SG_ 2264486920 RHP_Status_Long 0;
BA_ "GenSigSendType" SG_ 2264486920 RHP_TSK_Status 0;
BA_ "GenSigStartValue" SG_ 2264486920 RHP_TSK_Status 1;
BA_ "GenSigSendType" SG_ 2264486920 RHP_TV_Trigger 0;
BA_ "GenSigSwitchedByIgnition" SG_ 2264486920 RHP_TV_Trigger 0;
BA_ "GenSigSendType" SG_ 2264486920 RHP_Uss_Anforderung 0;
BA_ "GenSigSwitchedByIgnition" SG_ 2264486920 RHP_Uss_Anforderung 0;
BA_ "GenSigSendType" SG_ 2264486920 RHP_Verz_Anf 0;
BA_ "GenSigStartValue" SG_ 2264486920 RHP_Verz_Anf 1023;
BA_ "GenSigSendType" SG_ 2264486920 RHP_Verz_Freigabe 0;
BA_ "GenSigSendType" SG_ 2264486920 RHP_Warnblinken 0;
BA_ "GenSigSwitchedByIgnition" SG_ 2264486920 RHP_Warnblinken 0;
BA_ "GenSigSendType" SG_ 2264486920 RHP_Warnruckeln_Anf 0;
BA_ "GenSigSendType" SG_ 2264486920 RHP_zul_Regelabw_oben 0;
BA_ "GenSigSendType" SG_ 2264486920 RHP_zul_Regelabw_unten 0;
BA_ "GenSigSendType" SG_ 2527679688 RHP_ASM_Data_1 0;
BA_ "GenSigSwitchedByIgnition" SG_ 2527679688 RHP_ASM_Data_1 0;
BA_ "GenSigSendType" SG_ 2527679688 RHP_ASM_Data_2 0;
BA_ "GenSigSwitchedByIgnition" SG_ 2527679688 RHP_ASM_Data_2 0;
BA_ "GenSigSendType" SG_ 2527679688 RHP_ASM_Data_3 0;
BA_ "GenSigSwitchedByIgnition" SG_ 2527679688 RHP_ASM_Data_3 0;
BA_ "GenSigSendType" SG_ 2527679688 RHP_ASM_Data_4 0;
BA_ "GenSigSwitchedByIgnition" SG_ 2527679688 RHP_ASM_Data_4 0;
BA_ "GenSigSendType" SG_ 2527679688 RHP_ASM_Data_5 0;
BA_ "GenSigSwitchedByIgnition" SG_ 2527679688 RHP_ASM_Data_5 0;
BA_ "GenSigSendType" SG_ 2527679688 RHP_ASM_Data_6 0;
BA_ "GenSigSwitchedByIgnition" SG_ 2527679688 RHP_ASM_Data_6 0;
BA_ "GenSigSendType" SG_ 2527679688 RHP_ASM_Ereignis 3;
BA_ "GenSigSwitchedByIgnition" SG_ 2527679688 RHP_ASM_Ereignis 0;
BA_ "GenSigSendType" SG_ 2527679688 RHP_ASM_Zeitstempel_02 3;
BA_ "GenSigStartValue" SG_ 2527679688 RHP_ASM_Zeitstempel_02 255;
BA_ "GenSigSwitchedByIgnition" SG_ 2527679688 RHP_ASM_Zeitstempel_02 0;
BA_ "GenSigSendType" SG_ 1610 RKA_FMVSS138_Lampe 0;
BA_ "GenSigSwitchedByIgnition" SG_ 1610 RKA_FMVSS138_Lampe 0;
BA_ "GenSigSendType" SG_ 1610 RKA_FMVSS138_MIL 0;
BA_ "GenSigSwitchedByIgnition" SG_ 1610 RKA_FMVSS138_MIL 0;
BA_ "GenSigSendType" SG_ 1610 RKA_Reifentyp 0;
BA_ "GenSigSwitchedByIgnition" SG_ 1610 RKA_Reifentyp 0;
BA_ "GenSigSendType" SG_ 1610 RKA_Warnungen_02 0;
BA_ "GenSigSwitchedByIgnition" SG_ 1610 RKA_Warnungen_02 0;
BA_ "GenSigSendType" SG_ 2589283756 SOK_ungeschuetzte_Zeit 3;
BA_ "GenSigSwitchedByIgnition" SG_ 2589283756 SOK_ungeschuetzte_Zeit 0;
BA_ "GenSigSendType" SG_ 2464153619 SOK_Zeit_ABS_Challenge 3;
BA_ "GenSigSwitchedByIgnition" SG_ 2464153619 SOK_Zeit_ABS_Challenge 0;
BA_ "GenSigSendType" SG_ 2464284691 SOK_Zeit_ABS_Signatur 3;
BA_ "GenSigFuncType" SG_ 2464284691 SOK_Zeit_ABS_Signatur 15;
BA_ "GenSigSwitchedByIgnition" SG_ 2464284691 SOK_Zeit_ABS_Signatur 0;
BA_ "GenSigSendType" SG_ 2464284691 SOK_Zeit_ABS_Zeit 3;
BA_ "GenSigSwitchedByIgnition" SG_ 2464284691 SOK_Zeit_ABS_Zeit 0;
BA_ "GenSigSendType" SG_ 2464153621 SOK_Zeit_Airbag_Challenge 3;
BA_ "GenSigSwitchedByIgnition" SG_ 2464153621 SOK_Zeit_Airbag_Challenge 0;
BA_ "GenSigSendType" SG_ 2464284693 SOK_Zeit_Airbag_Signatur 3;
BA_ "GenSigFuncType" SG_ 2464284693 SOK_Zeit_Airbag_Signatur 15;
BA_ "GenSigSwitchedByIgnition" SG_ 2464284693 SOK_Zeit_Airbag_Signatur 0;
BA_ "GenSigSendType" SG_ 2464284693 SOK_Zeit_Airbag_Zeit 3;
BA_ "GenSigSwitchedByIgnition" SG_ 2464284693 SOK_Zeit_Airbag_Zeit 0;
BA_ "GenSigSendType" SG_ 2464153659 SOK_Zeit_EBKV_Challenge 3;
BA_ "GenSigSwitchedByIgnition" SG_ 2464153659 SOK_Zeit_EBKV_Challenge 0;
BA_ "GenSigSendType" SG_ 2464284731 SOK_Zeit_EBKV_Signatur 3;
BA_ "GenSigFuncType" SG_ 2464284731 SOK_Zeit_EBKV_Signatur 15;
BA_ "GenSigSwitchedByIgnition" SG_ 2464284731 SOK_Zeit_EBKV_Signatur 0;
BA_ "GenSigSendType" SG_ 2464284731 SOK_Zeit_EBKV_Zeit 3;
BA_ "GenSigSwitchedByIgnition" SG_ 2464284731 SOK_Zeit_EBKV_Zeit 0;
BA_ "GenSigSendType" SG_ 1413 GW_KD_Fehler 3;
BA_ "GenSigSendType" SG_ 1413 SI_BUS_01 3;
BA_ "GenSigStartValue" SG_ 1413 SI_BUS_01 1;
BA_ "GenSigSwitchedByIgnition" SG_ 1413 SI_BUS_01 0;
BA_ "GenSigSendType" SG_ 1413 SI_BUS_02 3;
BA_ "GenSigStartValue" SG_ 1413 SI_BUS_02 1;
BA_ "GenSigSwitchedByIgnition" SG_ 1413 SI_BUS_02 0;
BA_ "GenSigSendType" SG_ 1413 SI_BUS_03 3;
BA_ "GenSigStartValue" SG_ 1413 SI_BUS_03 1;
BA_ "GenSigSwitchedByIgnition" SG_ 1413 SI_BUS_03 0;
BA_ "GenSigSendType" SG_ 1413 SI_BUS_04 3;
BA_ "GenSigStartValue" SG_ 1413 SI_BUS_04 1;
BA_ "GenSigSwitchedByIgnition" SG_ 1413 SI_BUS_04 0;
BA_ "GenSigSendType" SG_ 1413 SI_BUS_05 3;
BA_ "GenSigStartValue" SG_ 1413 SI_BUS_05 1;
BA_ "GenSigSwitchedByIgnition" SG_ 1413 SI_BUS_05 0;
BA_ "GenSigSendType" SG_ 1413 SI_BUS_06 3;
BA_ "GenSigStartValue" SG_ 1413 SI_BUS_06 1;
BA_ "GenSigSwitchedByIgnition" SG_ 1413 SI_BUS_06 0;
BA_ "GenSigSendType" SG_ 1413 SI_BUS_07 3;
BA_ "GenSigStartValue" SG_ 1413 SI_BUS_07 1;
BA_ "GenSigSwitchedByIgnition" SG_ 1413 SI_BUS_07 0;
BA_ "GenSigSendType" SG_ 1413 SI_BUS_08 3;
BA_ "GenSigStartValue" SG_ 1413 SI_BUS_08 1;
BA_ "GenSigSwitchedByIgnition" SG_ 1413 SI_BUS_08 0;
BA_ "GenSigSendType" SG_ 1413 SI_BUS_09 3;
BA_ "GenSigStartValue" SG_ 1413 SI_BUS_09 1;
BA_ "GenSigSwitchedByIgnition" SG_ 1413 SI_BUS_09 0;
BA_ "GenSigSendType" SG_ 1413 SI_BUS_10 3;
BA_ "GenSigStartValue" SG_ 1413 SI_BUS_10 1;
BA_ "GenSigSwitchedByIgnition" SG_ 1413 SI_BUS_10 0;
BA_ "GenSigSendType" SG_ 1413 SI_BUS_11 3;
BA_ "GenSigStartValue" SG_ 1413 SI_BUS_11 1;
BA_ "GenSigSwitchedByIgnition" SG_ 1413 SI_BUS_11 0;
BA_ "GenSigSendType" SG_ 1413 SI_BUS_12 3;
BA_ "GenSigStartValue" SG_ 1413 SI_BUS_12 1;
BA_ "GenSigSwitchedByIgnition" SG_ 1413 SI_BUS_12 0;
BA_ "GenSigSendType" SG_ 1413 SI_BUS_13 3;
BA_ "GenSigStartValue" SG_ 1413 SI_BUS_13 1;
BA_ "GenSigSwitchedByIgnition" SG_ 1413 SI_BUS_13 0;
BA_ "GenSigSendType" SG_ 1413 SI_BUS_14 3;
BA_ "GenSigStartValue" SG_ 1413 SI_BUS_14 1;
BA_ "GenSigSwitchedByIgnition" SG_ 1413 SI_BUS_14 0;
BA_ "GenSigSendType" SG_ 1413 SI_BUS_15 3;
BA_ "GenSigStartValue" SG_ 1413 SI_BUS_15 1;
BA_ "GenSigSwitchedByIgnition" SG_ 1413 SI_BUS_15 0;
BA_ "GenSigSendType" SG_ 1413 SI_Bus_Identifikation 0;
BA_ "GenSigSwitchedByIgnition" SG_ 1413 SI_Bus_Identifikation 0;
BA_ "GenSigSendType" SG_ 1413 SI_CAB_V14 3;
BA_ "GenSigSwitchedByIgnition" SG_ 1413 SI_CAB_V14 0;
BA_ "GenSigSendType" SG_ 1413 SI_Diagnose_Aktiv 3;
BA_ "GenSigSwitchedByIgnition" SG_ 1413 SI_Diagnose_Aktiv 0;
BA_ "GenSigSendType" SG_ 1413 SI_NWDF 3;
BA_ "GenSigSwitchedByIgnition" SG_ 1413 SI_NWDF 0;
BA_ "GenSigSendType" SG_ 1413 SI_NWDF_30 3;
BA_ "GenSigSwitchedByIgnition" SG_ 1413 SI_NWDF_30 0;
BA_ "GenSigSendType" SG_ 1413 SI_NWDF_gueltig 3;
BA_ "GenSigFuncType" SG_ 1413 SI_NWDF_gueltig 8;
BA_ "GenSigSwitchedByIgnition" SG_ 1413 SI_NWDF_gueltig 0;
BA_ "GenSigSendType" SG_ 1413 SI_P_Mode 3;
BA_ "GenSigSwitchedByIgnition" SG_ 1413 SI_P_Mode 0;
BA_ "GenSigSendType" SG_ 1413 SI_P_Mode_gueltig 3;
BA_ "GenSigSwitchedByIgnition" SG_ 1413 SI_P_Mode_gueltig 0;
BA_ "GenSigSendType" SG_ 1413 SI_QRS_Mode 3;
BA_ "GenSigSwitchedByIgnition" SG_ 1413 SI_QRS_Mode 0;
BA_ "GenSigSendType" SG_ 1413 SI_Sammel_SG_Fehler 0;
BA_ "GenSigStartValue" SG_ 1413 SI_Sammel_SG_Fehler 63;
BA_ "GenSigSwitchedByIgnition" SG_ 1413 SI_Sammel_SG_Fehler 0;
BA_ "GenSigSendType" SG_ 1413 SI_Sammelfehler 3;
BA_ "GenSigSwitchedByIgnition" SG_ 1413 SI_Sammelfehler 0;
BA_ "GenSigSendType" SG_ 1413 SI_T_Mode 3;
BA_ "GenSigSwitchedByIgnition" SG_ 1413 SI_T_Mode 0;
BA_ "GenSigSendType" SG_ 1413 SI_T_Schutz 3;
BA_ "GenSigSwitchedByIgnition" SG_ 1413 SI_T_Schutz 0;
BA_ "GenSigSendType" SG_ 165 TS_CAN_Ma_CRC 0;
BA_ "GenSigFuncType" SG_ 165 TS_CAN_Ma_CRC 2;
BA_ "GenSigSwitchedByIgnition" SG_ 165 TS_CAN_Ma_CRC 0;
BA_ "GenSigSendType" SG_ 165 TS_CAN_Ma_OVS 0;
BA_ "GenSigSwitchedByIgnition" SG_ 165 TS_CAN_Ma_OVS 0;
BA_ "GenSigSendType" SG_ 165 TS_CAN_Ma_SequenceCounter 0;
BA_ "GenSigSwitchedByIgnition" SG_ 165 TS_CAN_Ma_SequenceCounter 0;
BA_ "GenSigSendType" SG_ 165 TS_CAN_Ma_SGW 0;
BA_ "GenSigSwitchedByIgnition" SG_ 165 TS_CAN_Ma_SGW 0;
BA_ "GenSigSendType" SG_ 165 TS_CAN_Ma_SyncTimeSec 0;
BA_ "GenSigSwitchedByIgnition" SG_ 165 TS_CAN_Ma_SyncTimeSec 0;
BA_ "GenSigSendType" SG_ 165 TS_CAN_Ma_TimeDomain 0;
BA_ "GenSigSwitchedByIgnition" SG_ 165 TS_CAN_Ma_TimeDomain 0;
BA_ "GenSigSendType" SG_ 165 TS_CAN_Ma_Type 3;
BA_ "GenSigSwitchedByIgnition" SG_ 165 TS_CAN_Ma_Type 0;
BA_ "GenSigSendType" SG_ 1447 bCall_active 3;
BA_ "GenSigSwitchedByIgnition" SG_ 1447 bCall_active 0;
BA_ "GenSigSendType" SG_ 1447 eCall_Funktionsstatus 0;
BA_ "GenSigSwitchedByIgnition" SG_ 1447 eCall_Funktionsstatus 0;
BA_ "GenSigSendType" SG_ 1447 eCall_Funktionsstatus_02 0;
BA_ "GenSigStartValue" SG_ 1447 eCall_Funktionsstatus_02 7;
BA_ "GenSigSwitchedByIgnition" SG_ 1447 eCall_Funktionsstatus_02 0;
BA_ "GenSigSendType" SG_ 1447 eCall_MCC 0;
BA_ "GenSigSwitchedByIgnition" SG_ 1447 eCall_MCC 0;
BA_ "GenSigSendType" SG_ 1447 eCall_Mute_Anf 3;
BA_ "GenSigSwitchedByIgnition" SG_ 1447 eCall_Mute_Anf 0;
BA_ "GenSigSendType" SG_ 1447 FaceRec_Enroll_Challenge_Request 3;
BA_ "GenSigSwitchedByIgnition" SG_ 1447 FaceRec_Enroll_Challenge_Request 0;
BA_ "GenSigSendType" SG_ 1447 FoD_Anz_Funktionsabschaltung 3;
BA_ "GenSigSwitchedByIgnition" SG_ 1447 FoD_Anz_Funktionsabschaltung 0;
BA_ "GenSigSendType" SG_ 1447 iCall_active 3;
BA_ "GenSigSwitchedByIgnition" SG_ 1447 iCall_active 0;
BA_ "GenSigSendType" SG_ 1447 MOD_Energie_Anf 0;
BA_ "GenSigSwitchedByIgnition" SG_ 1447 MOD_Energie_Anf 0;
BA_ "Fehlerwert" SG_ 1447 MOD_Energie_Anf 3;
BA_ "GenSigSendType" SG_ 1447 MOD_Request_ServiceKey 3;
BA_ "GenSigSwitchedByIgnition" SG_ 1447 MOD_Request_ServiceKey 0;
BA_ "GenSigSendType" SG_ 1447 ORU_KombiTimer 0;
BA_ "GenSigSwitchedByIgnition" SG_ 1447 ORU_KombiTimer 0;
BA_ "GenSigSendType" SG_ 1447 TM_Door_Lock 5;
BA_ "GenSigSwitchedByIgnition" SG_ 1447 TM_Door_Lock 0;
BA_ "GenSigSendType" SG_ 1447 TM_Door_Unlock 5;
BA_ "GenSigSwitchedByIgnition" SG_ 1447 TM_Door_Unlock 0;
BA_ "GenSigSendType" SG_ 1447 TM_Nur_Hupen 5;
BA_ "GenSigSwitchedByIgnition" SG_ 1447 TM_Nur_Hupen 0;
BA_ "GenSigSendType" SG_ 1447 TM_Panik_Alarm 5;
BA_ "GenSigSwitchedByIgnition" SG_ 1447 TM_Panik_Alarm 0;
BA_ "GenSigSendType" SG_ 1447 TM_Spiegel_Anklappen 5;
BA_ "GenSigSwitchedByIgnition" SG_ 1447 TM_Spiegel_Anklappen 0;
BA_ "GenSigSendType" SG_ 1447 TM_Warnblinken 5;
BA_ "GenSigSwitchedByIgnition" SG_ 1447 TM_Warnblinken 0;
BA_ "GenSigSendType" SG_ 1447 TM_ZV_Signatur 0;
BA_ "GenSigSwitchedByIgnition" SG_ 1447 TM_ZV_Signatur 0;
BA_ "GenSigSendType" SG_ 997 eTAB_FS_Bowdenzug_Auswerfen 3;
BA_ "GenSigSwitchedByIgnition" SG_ 997 eTAB_FS_Bowdenzug_Auswerfen 0;
BA_ "GenSigSendType" SG_ 997 FS_Push_Tuergriff 3;
BA_ "GenSigSwitchedByIgnition" SG_ 997 FS_Push_Tuergriff 0;
BA_ "GenSigSendType" SG_ 997 FS_Status_eTAG_ext 3;
BA_ "GenSigStartValue" SG_ 997 FS_Status_eTAG_ext 3;
BA_ "GenSigSwitchedByIgnition" SG_ 997 FS_Status_eTAG_ext 0;
BA_ "Fehlerwert" SG_ 997 FS_Status_eTAG_ext 4;
BA_ "GenSigSendType" SG_ 997 FT_ASW_Warnton 0;
BA_ "GenSigSwitchedByIgnition" SG_ 997 FT_ASW_Warnton 0;
BA_ "Fehlerwert" SG_ 997 FT_ASW_Warnton 3;
BA_ "GenSigSendType" SG_ 997 FT_BFS_Tuer_Status 3;
BA_ "GenSigSwitchedByIgnition" SG_ 997 FT_BFS_Tuer_Status 0;
BA_ "Fehlerwert" SG_ 997 FT_BFS_Tuer_Status 3;
BA_ "GenSigSendType" SG_ 997 FT_Cargolock_bet 3;
BA_ "GenSigSwitchedByIgnition" SG_ 997 FT_Cargolock_bet 0;
BA_ "GenSigSendType" SG_ 997 FT_HBFS_Tuer_Status 3;
BA_ "GenSigSwitchedByIgnition" SG_ 997 FT_HBFS_Tuer_Status 0;
BA_ "Fehlerwert" SG_ 997 FT_HBFS_Tuer_Status 3;
BA_ "GenSigSendType" SG_ 997 FT_HFS_Tuer_Status 3;
BA_ "GenSigSwitchedByIgnition" SG_ 997 FT_HFS_Tuer_Status 0;
BA_ "Fehlerwert" SG_ 997 FT_HFS_Tuer_Status 3;
BA_ "GenSigSendType" SG_ 997 FT_kisi_asynchron 3;
BA_ "GenSigSwitchedByIgnition" SG_ 997 FT_kisi_asynchron 0;
BA_ "GenSigSendType" SG_ 997 FT_KiSi_Status_Soll_HBFS 0;
BA_ "GenSigSwitchedByIgnition" SG_ 997 FT_KiSi_Status_Soll_HBFS 0;
BA_ "GenSigSendType" SG_ 997 FT_KiSi_Status_Soll_HFS 0;
BA_ "GenSigSwitchedByIgnition" SG_ 997 FT_KiSi_Status_Soll_HFS 0;
BA_ "GenSigSendType" SG_ 997 FT_Kisi_Taster_li_02 3;
BA_ "GenSigSwitchedByIgnition" SG_ 997 FT_Kisi_Taster_li_02 0;
BA_ "GenSigSendType" SG_ 997 FT_Kisi_Taster_re_02 3;
BA_ "GenSigSwitchedByIgnition" SG_ 997 FT_Kisi_Taster_re_02 0;
BA_ "GenSigSendType" SG_ 997 FT_Lock_Taster_02 0;
BA_ "GenSigSwitchedByIgnition" SG_ 997 FT_Lock_Taster_02 0;
BA_ "GenSigSendType" SG_ 997 FT_Schluesselschalter_zu_02 0;
BA_ "GenSigSwitchedByIgnition" SG_ 997 FT_Schluesselschalter_zu_02 0;
BA_ "GenSigSendType" SG_ 997 FT_SP_Heizung_ein 3;
BA_ "GenSigSwitchedByIgnition" SG_ 997 FT_SP_Heizung_ein 0;
BA_ "GenSigSendType" SG_ 997 FT_TCR_Mode_aktiv 3;
BA_ "GenSigSwitchedByIgnition" SG_ 997 FT_TCR_Mode_aktiv 0;
BA_ "GenSigSendType" SG_ 997 FT_TD_Taste_Status 3;
BA_ "GenSigSwitchedByIgnition" SG_ 997 FT_TD_Taste_Status 0;
BA_ "GenSigSendType" SG_ 997 FT_Tuer_Status 3;
BA_ "GenSigSwitchedByIgnition" SG_ 997 FT_Tuer_Status 0;
BA_ "Fehlerwert" SG_ 997 FT_Tuer_Status 3;
BA_ "GenSigSendType" SG_ 997 FT_Tuer_Status_QBit 0;
BA_ "GenSigSwitchedByIgnition" SG_ 997 FT_Tuer_Status_QBit 0;
BA_ "GenSigSendType" SG_ 997 FT_Tueroeffnen_Warnung 3;
BA_ "GenSigSwitchedByIgnition" SG_ 997 FT_Tueroeffnen_Warnung 0;
BA_ "GenSigSendType" SG_ 997 SSA_FT_ASW_Status 3;
BA_ "GenSigSwitchedByIgnition" SG_ 997 SSA_FT_ASW_Status 0;
BA_ "GenSigSendType" SG_ 997 TBF_FS_Touch_Event 3;
BA_ "GenSigSwitchedByIgnition" SG_ 997 TBF_FS_Touch_Event 0;
BA_ "GenSigSendType" SG_ 997 TSG_FS_Spiegel_angeklappt 3;
BA_ "GenSigSwitchedByIgnition" SG_ 997 TSG_FS_Spiegel_angeklappt 0;
BA_ "GenSigSendType" SG_ 997 TSG_FT_02_BZ 0;
BA_ "GenSigFuncType" SG_ 997 TSG_FT_02_BZ 1;
BA_ "GenSigSwitchedByIgnition" SG_ 997 TSG_FT_02_BZ 0;
BA_ "GenSigSendType" SG_ 997 TSG_FT_02_CRC 0;
BA_ "GenSigFuncType" SG_ 997 TSG_FT_02_CRC 2;
BA_ "GenSigSwitchedByIgnition" SG_ 997 TSG_FT_02_CRC 0;
BA_ "GenSigSendType" SG_ 2589283772 QSP_Temperatur_Oel 0;
BA_ "Fehlerwert" SG_ 2589283772 QSP_Temperatur_Oel 127;
BA_ "GenSigSendType" SG_ 2589283772 QSP_Thermische_Belastung 0;
BA_ "Fehlerwert" SG_ 2589283772 QSP_Thermische_Belastung 63;
BA_ "GenSigSendType" SG_ 2589283772 QSP_Warnlampe 0;
BA_ "GenSigSwitchedByIgnition" SG_ 2589283772 QSP_Warnlampe 0;
BA_ "GenSigSendType" SG_ 2589283772 TSL_Hinweis 0;
BA_ "GenSigSwitchedByIgnition" SG_ 2589283772 TSL_Hinweis 0;
BA_ "GenSigSendType" SG_ 2589283772 TSL_Warnung 0;
BA_ "GenSigSwitchedByIgnition" SG_ 2589283772 TSL_Warnung 0;
BA_ "GenSigSendType" SG_ 2589283773 TSR_Hinweis 0;
BA_ "GenSigSwitchedByIgnition" SG_ 2589283773 TSR_Hinweis 0;
BA_ "GenSigSendType" SG_ 2589283773 TSR_Temperatur_Oel 0;
BA_ "Fehlerwert" SG_ 2589283773 TSR_Temperatur_Oel 127;
BA_ "GenSigSendType" SG_ 2589283773 TSR_Thermische_Belastung 0;
BA_ "Fehlerwert" SG_ 2589283773 TSR_Thermische_Belastung 63;
BA_ "GenSigSendType" SG_ 2589283773 TSR_Warnlampe 0;
BA_ "GenSigSendType" SG_ 2589283773 TSR_Warnung 0;
BA_ "GenSigSwitchedByIgnition" SG_ 2589283773 TSR_Warnung 0;
BA_ "GenSigSendType" SG_ 2463978710 OPS_ComfortReadyStatus 4;
BA_ "GenSigSwitchedByIgnition" SG_ 2463978710 OPS_ComfortReadyStatus 0;
BA_ "Fehlerwert" SG_ 2463978710 OPS_ComfortReadyStatus 3;
BA_ "GenSigSendType" SG_ 2463978710 OPS_DriverPresenceStatus 4;
BA_ "GenSigSwitchedByIgnition" SG_ 2463978710 OPS_DriverPresenceStatus 0;
BA_ "Fehlerwert" SG_ 2463978710 OPS_DriverPresenceStatus 15;
BA_ "GenSigSendType" SG_ 2463978710 OPS_OccupantPresenceStatus 4;
BA_ "GenSigSwitchedByIgnition" SG_ 2463978710 OPS_OccupantPresenceStatus 0;
BA_ "Fehlerwert" SG_ 2463978710 OPS_OccupantPresenceStatus 7;
BA_ "GenSigSendType" SG_ 2463978710 OPS_QBit_DriverPresence 4;
BA_ "GenSigStartValue" SG_ 2463978710 OPS_QBit_DriverPresence 1;
BA_ "GenSigSwitchedByIgnition" SG_ 2463978710 OPS_QBit_DriverPresence 0;
BA_ "GenSigSendType" SG_ 2463978710 OPS_SafeDriverPresence_available 4;
BA_ "GenSigSwitchedByIgnition" SG_ 2463978710 OPS_SafeDriverPresence_available 0;
BA_ "GenSigSendType" SG_ 2463978710 OPS_SafeDriverPresenceStatus 4;
BA_ "GenSigSwitchedByIgnition" SG_ 2463978710 OPS_SafeDriverPresenceStatus 0;
BA_ "Fehlerwert" SG_ 2463978710 OPS_SafeDriverPresenceStatus 3;
BA_ "GenSigSendType" SG_ 2463978710 UserStateServer_01_BZ 0;
BA_ "GenSigFuncType" SG_ 2463978710 UserStateServer_01_BZ 1;
BA_ "GenSigSwitchedByIgnition" SG_ 2463978710 UserStateServer_01_BZ 0;
BA_ "GenSigSendType" SG_ 2463978710 UserStateServer_01_CRC 0;
BA_ "GenSigFuncType" SG_ 2463978710 UserStateServer_01_CRC 2;
BA_ "GenSigSwitchedByIgnition" SG_ 2463978710 UserStateServer_01_CRC 0;
BA_ "GenSigSendType" SG_ 995 VD_SpannungsAnf 3;
BA_ "GenSigSwitchedByIgnition" SG_ 995 VD_SpannungsAnf 0;
BA_ "GenSigActiveRepetitions" SG_ 995 VS_BFS_AutoHoch 5;
BA_ "GenSigSendType" SG_ 995 VS_BFS_AutoHoch 4;
BA_ "GenSigSwitchedByIgnition" SG_ 995 VS_BFS_AutoHoch 0;
BA_ "GenSigActiveRepetitions" SG_ 995 VS_BFS_AutoTief 5;
BA_ "GenSigSendType" SG_ 995 VS_BFS_AutoTief 4;
BA_ "GenSigSwitchedByIgnition" SG_ 995 VS_BFS_AutoTief 0;
BA_ "GenSigActiveRepetitions" SG_ 995 VS_BFS_ManHoch 5;
BA_ "GenSigSendType" SG_ 995 VS_BFS_ManHoch 4;
BA_ "GenSigSwitchedByIgnition" SG_ 995 VS_BFS_ManHoch 0;
BA_ "GenSigActiveRepetitions" SG_ 995 VS_BFS_ManTief 5;
BA_ "GenSigSendType" SG_ 995 VS_BFS_ManTief 4;
BA_ "GenSigSwitchedByIgnition" SG_ 995 VS_BFS_ManTief 0;
BA_ "GenSigSendType" SG_ 995 VS_Buzzer 3;
BA_ "GenSigSwitchedByIgnition" SG_ 995 VS_Buzzer 0;
BA_ "GenSigSendType" SG_ 995 VS_FH_BT_Langhub 3;
BA_ "GenSigSwitchedByIgnition" SG_ 995 VS_FH_BT_Langhub 0;
BA_ "GenSigSendType" SG_ 995 VS_FH_FT_Langhub 3;
BA_ "GenSigSwitchedByIgnition" SG_ 995 VS_FH_FT_Langhub 0;
BA_ "GenSigSendType" SG_ 995 VS_FH_HBFS_Langhub 3;
BA_ "GenSigSwitchedByIgnition" SG_ 995 VS_FH_HBFS_Langhub 0;
BA_ "GenSigSendType" SG_ 995 VS_FH_HFS_Langhub 3;
BA_ "GenSigSwitchedByIgnition" SG_ 995 VS_FH_HFS_Langhub 0;
BA_ "GenSigActiveRepetitions" SG_ 995 VS_FS_AutoHoch 5;
BA_ "GenSigSendType" SG_ 995 VS_FS_AutoHoch 4;
BA_ "GenSigSwitchedByIgnition" SG_ 995 VS_FS_AutoHoch 0;
BA_ "GenSigActiveRepetitions" SG_ 995 VS_FS_AutoTief 5;
BA_ "GenSigSendType" SG_ 995 VS_FS_AutoTief 4;
BA_ "GenSigSwitchedByIgnition" SG_ 995 VS_FS_AutoTief 0;
BA_ "GenSigActiveRepetitions" SG_ 995 VS_FS_ManHoch 5;
BA_ "GenSigSendType" SG_ 995 VS_FS_ManHoch 4;
BA_ "GenSigSwitchedByIgnition" SG_ 995 VS_FS_ManHoch 0;
BA_ "GenSigActiveRepetitions" SG_ 995 VS_FS_ManTief 5;
BA_ "GenSigSendType" SG_ 995 VS_FS_ManTief 4;
BA_ "GenSigSwitchedByIgnition" SG_ 995 VS_FS_ManTief 0;
BA_ "GenSigSendType" SG_ 995 VS_Hardtop 3;
BA_ "GenSigSwitchedByIgnition" SG_ 995 VS_Hardtop 0;
BA_ "GenSigActiveRepetitions" SG_ 995 VS_HBFS_AutoHoch 5;
BA_ "GenSigSendType" SG_ 995 VS_HBFS_AutoHoch 4;
BA_ "GenSigSwitchedByIgnition" SG_ 995 VS_HBFS_AutoHoch 0;
BA_ "GenSigActiveRepetitions" SG_ 995 VS_HBFS_AutoTief 5;
BA_ "GenSigSendType" SG_ 995 VS_HBFS_AutoTief 4;
BA_ "GenSigSwitchedByIgnition" SG_ 995 VS_HBFS_AutoTief 0;
BA_ "GenSigActiveRepetitions" SG_ 995 VS_HBFS_ManHoch 5;
BA_ "GenSigSendType" SG_ 995 VS_HBFS_ManHoch 4;
BA_ "GenSigSwitchedByIgnition" SG_ 995 VS_HBFS_ManHoch 0;
BA_ "GenSigActiveRepetitions" SG_ 995 VS_HBFS_ManTief 5;
BA_ "GenSigSendType" SG_ 995 VS_HBFS_ManTief 4;
BA_ "GenSigSwitchedByIgnition" SG_ 995 VS_HBFS_ManTief 0;
BA_ "GenSigSendType" SG_ 995 VS_HD_sperren 3;
BA_ "GenSigSwitchedByIgnition" SG_ 995 VS_HD_sperren 0;
BA_ "GenSigSendType" SG_ 995 VS_Heckschloss_auf 3;
BA_ "GenSigSwitchedByIgnition" SG_ 995 VS_Heckschloss_auf 0;
BA_ "GenSigActiveRepetitions" SG_ 995 VS_HFS_AutoHoch 5;
BA_ "GenSigSendType" SG_ 995 VS_HFS_AutoHoch 4;
BA_ "GenSigSwitchedByIgnition" SG_ 995 VS_HFS_AutoHoch 0;
BA_ "GenSigActiveRepetitions" SG_ 995 VS_HFS_AutoTief 5;
BA_ "GenSigSendType" SG_ 995 VS_HFS_AutoTief 4;
BA_ "GenSigSwitchedByIgnition" SG_ 995 VS_HFS_AutoTief 0;
BA_ "GenSigActiveRepetitions" SG_ 995 VS_HFS_ManHoch 5;
BA_ "GenSigSendType" SG_ 995 VS_HFS_ManHoch 4;
BA_ "GenSigSwitchedByIgnition" SG_ 995 VS_HFS_ManHoch 0;
BA_ "GenSigActiveRepetitions" SG_ 995 VS_HFS_ManTief 5;
BA_ "GenSigSendType" SG_ 995 VS_HFS_ManTief 4;
BA_ "GenSigSwitchedByIgnition" SG_ 995 VS_HFS_ManTief 0;
BA_ "GenSigSendType" SG_ 995 VS_HHS_enable 3;
BA_ "GenSigSwitchedByIgnition" SG_ 995 VS_HHS_enable 0;
BA_ "GenSigSendType" SG_ 995 VS_Lampe_Blk 3;
BA_ "GenSigSwitchedByIgnition" SG_ 995 VS_Lampe_Blk 0;
BA_ "GenSigSendType" SG_ 995 VS_StartStopp_Info 3;
BA_ "GenSigSwitchedByIgnition" SG_ 995 VS_StartStopp_Info 0;
BA_ "Fehlerwert" SG_ 995 VS_StartStopp_Info 3;
BA_ "GenSigSendType" SG_ 995 VS_VD_Bew_auf 3;
BA_ "GenSigSwitchedByIgnition" SG_ 995 VS_VD_Bew_auf 0;
BA_ "GenSigSendType" SG_ 995 VS_VD_Bew_zu 3;
BA_ "GenSigSwitchedByIgnition" SG_ 995 VS_VD_Bew_zu 0;
BA_ "GenSigSendType" SG_ 995 VS_VD_entriegelt 3;
BA_ "GenSigSwitchedByIgnition" SG_ 995 VS_VD_entriegelt 0;
BA_ "GenSigSendType" SG_ 995 VS_VD_Fehler 3;
BA_ "GenSigSwitchedByIgnition" SG_ 995 VS_VD_Fehler 0;
BA_ "GenSigSendType" SG_ 995 VS_VD_offen_ver 3;
BA_ "GenSigSwitchedByIgnition" SG_ 995 VS_VD_offen_ver 0;
BA_ "GenSigSendType" SG_ 995 VS_VD_zu_ver 3;
BA_ "GenSigSwitchedByIgnition" SG_ 995 VS_VD_zu_ver 0;
BA_ "GenSigSendType" SG_ 995 VS_VD_Zwischenposition 3;
BA_ "GenSigSwitchedByIgnition" SG_ 995 VS_VD_Zwischenposition 0;
BA_ "GenSigSendType" SG_ 995 VS_VDKD_auf 3;
BA_ "GenSigSwitchedByIgnition" SG_ 995 VS_VDKD_auf 0;
BA_ "GenSigSendType" SG_ 995 VS_Verdeck_Anf 3;
BA_ "GenSigSwitchedByIgnition" SG_ 995 VS_Verdeck_Anf 0;
BA_ "GenSigSendType" SG_ 995 VS_Windschott_nicht_abgelegt 3;
BA_ "GenSigSwitchedByIgnition" SG_ 995 VS_Windschott_nicht_abgelegt 0;
BA_ "GenSigSendType" SG_ 995 VSG_Meldungen 3;
BA_ "GenSigSwitchedByIgnition" SG_ 995 VSG_Meldungen 0;
BA_ "GenSigSwitchedByIgnition" SG_ 1716 KS_Geheimnis_1 0;
BA_ "GenSigSwitchedByIgnition" SG_ 1716 KS_Geheimnis_2 0;
BA_ "GenSigSwitchedByIgnition" SG_ 1716 KS_Geheimnis_3 0;
BA_ "GenSigSwitchedByIgnition" SG_ 1716 KS_Geheimnis_4 0;
BA_ "GenSigSendType" SG_ 1716 VIN_01_MUX 0;
BA_ "GenSigSwitchedByIgnition" SG_ 1716 VIN_01_MUX 0;
BA_ "GenSigStartValue" SG_ 1716 VIN_1 45;
BA_ "GenSigSwitchedByIgnition" SG_ 1716 VIN_1 0;
BA_ "GenSigStartValue" SG_ 1716 VIN_10 45;
BA_ "GenSigSwitchedByIgnition" SG_ 1716 VIN_10 0;
BA_ "GenSigStartValue" SG_ 1716 VIN_11 45;
BA_ "GenSigSwitchedByIgnition" SG_ 1716 VIN_11 0;
BA_ "GenSigStartValue" SG_ 1716 VIN_12 45;
BA_ "GenSigSwitchedByIgnition" SG_ 1716 VIN_12 0;
BA_ "GenSigStartValue" SG_ 1716 VIN_13 45;
BA_ "GenSigSwitchedByIgnition" SG_ 1716 VIN_13 0;
BA_ "GenSigStartValue" SG_ 1716 VIN_14 45;
BA_ "GenSigSwitchedByIgnition" SG_ 1716 VIN_14 0;
BA_ "GenSigStartValue" SG_ 1716 VIN_15 45;
BA_ "GenSigSwitchedByIgnition" SG_ 1716 VIN_15 0;
BA_ "GenSigStartValue" SG_ 1716 VIN_16 45;
BA_ "GenSigSwitchedByIgnition" SG_ 1716 VIN_16 0;
BA_ "GenSigStartValue" SG_ 1716 VIN_17 45;
BA_ "GenSigSwitchedByIgnition" SG_ 1716 VIN_17 0;
BA_ "GenSigStartValue" SG_ 1716 VIN_2 45;
BA_ "GenSigSwitchedByIgnition" SG_ 1716 VIN_2 0;
BA_ "GenSigStartValue" SG_ 1716 VIN_3 45;
BA_ "GenSigSwitchedByIgnition" SG_ 1716 VIN_3 0;
BA_ "GenSigStartValue" SG_ 1716 VIN_4 45;
BA_ "GenSigSwitchedByIgnition" SG_ 1716 VIN_4 0;
BA_ "GenSigStartValue" SG_ 1716 VIN_5 45;
BA_ "GenSigSwitchedByIgnition" SG_ 1716 VIN_5 0;
BA_ "GenSigStartValue" SG_ 1716 VIN_6 45;
BA_ "GenSigSwitchedByIgnition" SG_ 1716 VIN_6 0;
BA_ "GenSigStartValue" SG_ 1716 VIN_7 45;
BA_ "GenSigSwitchedByIgnition" SG_ 1716 VIN_7 0;
BA_ "GenSigStartValue" SG_ 1716 VIN_8 45;
BA_ "GenSigSwitchedByIgnition" SG_ 1716 VIN_8 0;
BA_ "GenSigStartValue" SG_ 1716 VIN_9 45;
BA_ "GenSigSwitchedByIgnition" SG_ 1716 VIN_9 0;
BA_ "GenSigSendType" SG_ 1057 VLK_01_BZ 0;
BA_ "GenSigFuncType" SG_ 1057 VLK_01_BZ 1;
BA_ "GenSigSwitchedByIgnition" SG_ 1057 VLK_01_BZ 0;
BA_ "GenSigSendType" SG_ 1057 VLK_01_CRC 0;
BA_ "GenSigFuncType" SG_ 1057 VLK_01_CRC 2;
BA_ "GenSigSwitchedByIgnition" SG_ 1057 VLK_01_CRC 0;
BA_ "GenSigSendType" SG_ 1057 VLK_Anf_Antrieb 3;
BA_ "GenSigSwitchedByIgnition" SG_ 1057 VLK_Anf_Antrieb 0;
BA_ "Fehlerwert" SG_ 1057 VLK_Anf_Antrieb 7;
BA_ "GenSigSendType" SG_ 1057 VLK_Anforderung_HMS 3;
BA_ "GenSigSwitchedByIgnition" SG_ 1057 VLK_Anforderung_HMS 0;
BA_ "GenSigSendType" SG_ 1057 VLK_Anforderung_Rollfaehigkeit 0;
BA_ "GenSigSwitchedByIgnition" SG_ 1057 VLK_Anforderung_Rollfaehigkeit 0;
BA_ "GenSigSendType" SG_ 1057 VLK_Antriebsdeaktivierung 3;
BA_ "GenSigSwitchedByIgnition" SG_ 1057 VLK_Antriebsdeaktivierung 0;
BA_ "Fehlerwert" SG_ 1057 VLK_Antriebsdeaktivierung 3;
BA_ "GenSigSendType" SG_ 1057 VLK_autom_Absch_Signalisierung 0;
BA_ "GenSigSwitchedByIgnition" SG_ 1057 VLK_autom_Absch_Signalisierung 0;
BA_ "GenSigSendType" SG_ 1057 VLK_Hinweis_dgr_VLW 3;
BA_ "GenSigSwitchedByIgnition" SG_ 1057 VLK_Hinweis_dgr_VLW 0;
BA_ "GenSigSendType" SG_ 1057 VLK_Hinweis_Fehler_Gurt 3;
BA_ "GenSigSwitchedByIgnition" SG_ 1057 VLK_Hinweis_Fehler_Gurt 0;
BA_ "GenSigSendType" SG_ 1057 VLK_Hinweis_Fehler_Sitz 3;
BA_ "GenSigSwitchedByIgnition" SG_ 1057 VLK_Hinweis_Fehler_Sitz 0;
BA_ "GenSigSendType" SG_ 1057 VLK_Hinweis_Fehler_Tuer 3;
BA_ "GenSigSwitchedByIgnition" SG_ 1057 VLK_Hinweis_Fehler_Tuer 0;
BA_ "GenSigSendType" SG_ 1057 VLK_Hinweis_KA_bevorstehend 3;
BA_ "GenSigSwitchedByIgnition" SG_ 1057 VLK_Hinweis_KA_bevorstehend 0;
BA_ "GenSigSendType" SG_ 1057 VLK_Hinweis_Rollfaehigkeit 3;
BA_ "GenSigSwitchedByIgnition" SG_ 1057 VLK_Hinweis_Rollfaehigkeit 0;
BA_ "GenSigSendType" SG_ 1057 VLK_Hinweis_Weiterfahrt 3;
BA_ "GenSigSwitchedByIgnition" SG_ 1057 VLK_Hinweis_Weiterfahrt 0;
BA_ "GenSigSendType" SG_ 1057 VLK_Parken_beibehalten_HMS 3;
BA_ "GenSigStartValue" SG_ 1057 VLK_Parken_beibehalten_HMS 2;
BA_ "GenSigSwitchedByIgnition" SG_ 1057 VLK_Parken_beibehalten_HMS 0;
BA_ "Fehlerwert" SG_ 1057 VLK_Parken_beibehalten_HMS 3;
BA_ "GenSigSendType" SG_ 1057 VLK_VLW_Anf 3;
BA_ "GenSigSwitchedByIgnition" SG_ 1057 VLK_VLW_Anf 0;
BA_ "GenSigSendType" SG_ 313 HMS_aktives_System 0;
BA_ "GenSigSwitchedByIgnition" SG_ 313 HMS_aktives_System 0;
BA_ "GenSigSendType" SG_ 313 HMS_Anforderung_GE 0;
BA_ "GenSigSwitchedByIgnition" SG_ 313 HMS_Anforderung_GE 0;
BA_ "GenSigSendType" SG_ 313 HMS_Fehlerstatus 0;
BA_ "GenSigSwitchedByIgnition" SG_ 313 HMS_Fehlerstatus 0;
BA_ "GenSigSendType" SG_ 313 HMS_Haltemoment 0;
BA_ "GenSigStartValue" SG_ 313 HMS_Haltemoment 1022;
BA_ "GenSigSwitchedByIgnition" SG_ 313 HMS_Haltemoment 0;
BA_ "Fehlerwert" SG_ 313 HMS_Haltemoment 1023;
BA_ "GenSigSendType" SG_ 313 HMS_halten_nicht_verfuegbar 0;
BA_ "GenSigSwitchedByIgnition" SG_ 313 HMS_halten_nicht_verfuegbar 0;
BA_ "GenSigSendType" SG_ 313 HMS_halten_nicht_verfuegbar_02 0;
BA_ "GenSigSwitchedByIgnition" SG_ 313 HMS_halten_nicht_verfuegbar_02 0;
BA_ "GenSigSendType" SG_ 313 HMS_Index_Haltemoment 0;
BA_ "GenSigSwitchedByIgnition" SG_ 313 HMS_Index_Haltemoment 0;
BA_ "GenSigSendType" SG_ 313 HMS_P_beibehalten_GE 0;
BA_ "GenSigStartValue" SG_ 313 HMS_P_beibehalten_GE 2;
BA_ "GenSigSwitchedByIgnition" SG_ 313 HMS_P_beibehalten_GE 0;
BA_ "Fehlerwert" SG_ 313 HMS_P_beibehalten_GE 3;
BA_ "GenSigSendType" SG_ 313 HMS_parken_nicht_verfuegbar 0;
BA_ "GenSigSwitchedByIgnition" SG_ 313 HMS_parken_nicht_verfuegbar 0;
BA_ "GenSigSendType" SG_ 313 HMS_Stillstand 0;
BA_ "GenSigStartValue" SG_ 313 HMS_Stillstand 6;
BA_ "GenSigSwitchedByIgnition" SG_ 313 HMS_Stillstand 0;
BA_ "Fehlerwert" SG_ 313 HMS_Stillstand 7;
BA_ "GenSigSendType" SG_ 313 HMS_Systemstatus 0;
BA_ "GenSigStartValue" SG_ 313 HMS_Systemstatus 14;
BA_ "GenSigSwitchedByIgnition" SG_ 313 HMS_Systemstatus 0;
BA_ "Fehlerwert" SG_ 313 HMS_Systemstatus 15;
BA_ "GenSigSendType" SG_ 313 SOK_VMM_02_Signatur 0;
BA_ "GenSigFuncType" SG_ 313 SOK_VMM_02_Signatur 15;
BA_ "GenSigSendType" SG_ 313 VMM_02_BZ 0;
BA_ "GenSigFuncType" SG_ 313 VMM_02_BZ 1;
BA_ "GenSigSwitchedByIgnition" SG_ 313 VMM_02_BZ 0;
BA_ "GenSigSendType" SG_ 313 VMM_02_CRC 0;
BA_ "GenSigFuncType" SG_ 313 VMM_02_CRC 2;
BA_ "GenSigSwitchedByIgnition" SG_ 313 VMM_02_CRC 0;
BA_ "GenSigSendType" SG_ 313 VMM_Bremslicht_defekt 0;
BA_ "GenSigSwitchedByIgnition" SG_ 313 VMM_Bremslicht_defekt 0;
BA_ "GenSigSendType" SG_ 313 VMM_Bremslicht_unplausibel 0;
BA_ "GenSigSwitchedByIgnition" SG_ 313 VMM_Bremslicht_unplausibel 0;
BA_ "GenSigSendType" SG_ 313 VMM_Fahrer_Bremskraft_bestimmend 0;
BA_ "GenSigSwitchedByIgnition" SG_ 313 VMM_Fahrer_Bremskraft_bestimmend 0;
BA_ "GenSigSendType" SG_ 313 VMM_Inkonsistenz_ACC 0;
BA_ "GenSigSwitchedByIgnition" SG_ 313 VMM_Inkonsistenz_ACC 0;
BA_ "GenSigSendType" SG_ 313 VMM_Inkonsistenz_AEB 0;
BA_ "GenSigSwitchedByIgnition" SG_ 313 VMM_Inkonsistenz_AEB 0;
BA_ "GenSigSendType" SG_ 313 VMM_Inkonsistenz_ARA 0;
BA_ "GenSigSwitchedByIgnition" SG_ 313 VMM_Inkonsistenz_ARA 0;
BA_ "GenSigSendType" SG_ 313 VMM_Inkonsistenz_AWV_PCF 0;
BA_ "GenSigSwitchedByIgnition" SG_ 313 VMM_Inkonsistenz_AWV_PCF 0;
BA_ "GenSigSendType" SG_ 313 VMM_Inkonsistenz_EA 0;
BA_ "GenSigSwitchedByIgnition" SG_ 313 VMM_Inkonsistenz_EA 0;
BA_ "GenSigSendType" SG_ 313 VMM_Inkonsistenz_EBKV 0;
BA_ "GenSigSwitchedByIgnition" SG_ 313 VMM_Inkonsistenz_EBKV 0;
BA_ "GenSigSendType" SG_ 313 VMM_Inkonsistenz_FAS_VK 0;
BA_ "GenSigSwitchedByIgnition" SG_ 313 VMM_Inkonsistenz_FAS_VK 0;
BA_ "GenSigSendType" SG_ 313 VMM_Inkonsistenz_GE 0;
BA_ "GenSigSwitchedByIgnition" SG_ 313 VMM_Inkonsistenz_GE 0;
BA_ "GenSigSendType" SG_ 313 VMM_Inkonsistenz_HVLM 0;
BA_ "GenSigSwitchedByIgnition" SG_ 313 VMM_Inkonsistenz_HVLM 0;
BA_ "GenSigSendType" SG_ 313 VMM_Inkonsistenz_KAM 0;
BA_ "GenSigSwitchedByIgnition" SG_ 313 VMM_Inkonsistenz_KAM 0;
BA_ "GenSigSendType" SG_ 313 VMM_Inkonsistenz_KAS 0;
BA_ "GenSigSwitchedByIgnition" SG_ 313 VMM_Inkonsistenz_KAS 0;
BA_ "GenSigSendType" SG_ 313 VMM_Inkonsistenz_MO 0;
BA_ "GenSigSwitchedByIgnition" SG_ 313 VMM_Inkonsistenz_MO 0;
BA_ "GenSigSendType" SG_ 313 VMM_Inkonsistenz_NV 0;
BA_ "GenSigSwitchedByIgnition" SG_ 313 VMM_Inkonsistenz_NV 0;
BA_ "GenSigSendType" SG_ 313 VMM_Inkonsistenz_ParkAssist 0;
BA_ "GenSigSwitchedByIgnition" SG_ 313 VMM_Inkonsistenz_ParkAssist 0;
BA_ "GenSigSendType" SG_ 313 VMM_Inkonsistenz_RCTA 0;
BA_ "GenSigSwitchedByIgnition" SG_ 313 VMM_Inkonsistenz_RCTA 0;
BA_ "GenSigSendType" SG_ 313 VMM_Inkonsistenz_RHP 0;
BA_ "GenSigSwitchedByIgnition" SG_ 313 VMM_Inkonsistenz_RHP 0;
BA_ "GenSigSendType" SG_ 313 VMM_Inkonsistenz_TSK 0;
BA_ "GenSigSwitchedByIgnition" SG_ 313 VMM_Inkonsistenz_TSK 0;
BA_ "GenSigSendType" SG_ 313 VMM_Inkonsistenz_VLK 0;
BA_ "GenSigSwitchedByIgnition" SG_ 313 VMM_Inkonsistenz_VLK 0;
BA_ "GenSigSendType" SG_ 313 VMM_MKB_codiert 0;
BA_ "GenSigSwitchedByIgnition" SG_ 313 VMM_MKB_codiert 0;
BA_ "GenSigSendType" SG_ 313 VMM_Notstopp_Status 0;
BA_ "GenSigSwitchedByIgnition" SG_ 313 VMM_Notstopp_Status 0;
BA_ "Fehlerwert" SG_ 313 VMM_Notstopp_Status 7;
BA_ "GenSigSendType" SG_ 313 VZM_aktiver_Basisservice 0;
BA_ "GenSigSwitchedByIgnition" SG_ 313 VZM_aktiver_Basisservice 0;
BA_ "GenSigSendType" SG_ 313 VZM_aktives_System 0;
BA_ "GenSigSwitchedByIgnition" SG_ 313 VZM_aktives_System 0;
BA_ "GenSigSendType" SG_ 313 VZM_Anhalteweg_nicht_verfuegbar 0;
BA_ "GenSigSwitchedByIgnition" SG_ 313 VZM_Anhalteweg_nicht_verfuegbar 0;
BA_ "GenSigSendType" SG_ 313 VZM_Bkd_nicht_verfuegbar 0;
BA_ "GenSigSwitchedByIgnition" SG_ 313 VZM_Bkd_nicht_verfuegbar 0;
BA_ "GenSigSendType" SG_ 313 VZM_Fahrer_bremst 0;
BA_ "GenSigSwitchedByIgnition" SG_ 313 VZM_Fahrer_bremst 0;
BA_ "GenSigSendType" SG_ 313 VZM_Fahrer_bremst_deutlich 0;
BA_ "GenSigSwitchedByIgnition" SG_ 313 VZM_Fahrer_bremst_deutlich 0;
BA_ "GenSigSendType" SG_ 313 VZM_QBit_Fahrer_bremst 0;
BA_ "GenSigStartValue" SG_ 313 VZM_QBit_Fahrer_bremst 1;
BA_ "GenSigSwitchedByIgnition" SG_ 313 VZM_QBit_Fahrer_bremst 0;
BA_ "GenSigSendType" SG_ 313 VZM_SRBM_Ist 0;
BA_ "GenSigStartValue" SG_ 313 VZM_SRBM_Ist 4094;
BA_ "GenSigSwitchedByIgnition" SG_ 313 VZM_SRBM_Ist 0;
BA_ "Fehlerwert" SG_ 313 VZM_SRBM_Ist 4095;
BA_ "GenSigSendType" SG_ 313 VZM_SRBM_max_Gradient 0;
BA_ "GenSigStartValue" SG_ 313 VZM_SRBM_max_Gradient 126;
BA_ "GenSigSwitchedByIgnition" SG_ 313 VZM_SRBM_max_Gradient 0;
BA_ "Fehlerwert" SG_ 313 VZM_SRBM_max_Gradient 127;
BA_ "GenSigSendType" SG_ 313 VZM_SRBM_Soll 0;
BA_ "GenSigStartValue" SG_ 313 VZM_SRBM_Soll 4094;
BA_ "GenSigSwitchedByIgnition" SG_ 313 VZM_SRBM_Soll 0;
BA_ "Fehlerwert" SG_ 313 VZM_SRBM_Soll 4095;
BA_ "GenSigSendType" SG_ 313 VZM_Status_Wegregelung 0;
BA_ "GenSigSwitchedByIgnition" SG_ 313 VZM_Status_Wegregelung 0;
BA_ "GenSigSendType" SG_ 313 VZM_Systemstatus 0;
BA_ "GenSigSwitchedByIgnition" SG_ 313 VZM_Systemstatus 0;
BA_ "Fehlerwert" SG_ 313 VZM_Systemstatus 4;
BA_ "GenSigSendType" SG_ 313 VZM_TSK_SRBM_Anf 0;
BA_ "GenSigSwitchedByIgnition" SG_ 313 VZM_TSK_SRBM_Anf 0;
BA_ "GenSigSendType" SG_ 313 VZM_TSK_SRBM_nicht_verfuegbar 0;
BA_ "GenSigSwitchedByIgnition" SG_ 313 VZM_TSK_SRBM_nicht_verfuegbar 0;
BA_ "GenSigSendType" SG_ 313 VZM_Unterdrueckung_Antriebsmom 0;
BA_ "GenSigSwitchedByIgnition" SG_ 313 VZM_Unterdrueckung_Antriebsmom 0;
BA_ "GenSigSendType" SG_ 313 VZM_Verz_ASIL_Verfuegbarkeit 0;
BA_ "GenSigSwitchedByIgnition" SG_ 313 VZM_Verz_ASIL_Verfuegbarkeit 0;
BA_ "GenSigSendType" SG_ 313 VZM_Verz_Begrenzung 0;
BA_ "GenSigSwitchedByIgnition" SG_ 313 VZM_Verz_Begrenzung 0;
BA_ "GenSigSendType" SG_ 313 VZM_Verz_Reg_aktiv 0;
BA_ "GenSigSwitchedByIgnition" SG_ 313 VZM_Verz_Reg_aktiv 0;
BA_ "GenSigSendType" SG_ 313 VZM_Verz_Reg_nicht_verfuegbar 0;
BA_ "GenSigSwitchedByIgnition" SG_ 313 VZM_Verz_Reg_nicht_verfuegbar 0;
BA_ "GenSigSendType" SG_ 313 VZM_Warnruck_nicht_verfuegbar 0;
BA_ "GenSigSwitchedByIgnition" SG_ 313 VZM_Warnruck_nicht_verfuegbar 0;
BA_ "GenSigSendType" SG_ 313 VZM_Warnruckeln_nicht_verfuegbar 0;
BA_ "GenSigSwitchedByIgnition" SG_ 313 VZM_Warnruckeln_nicht_verfuegbar 0;
BA_ "GenSigSendType" SG_ 1702 BCM1_SRA_aktiv 3;
BA_ "GenSigSwitchedByIgnition" SG_ 1702 BCM1_SRA_aktiv 0;
BA_ "GenSigActiveRepetitions" SG_ 1702 Heckwischer_Anforderung 3;
BA_ "GenSigSendType" SG_ 1702 Heckwischer_Anforderung 4;
BA_ "GenSigSwitchedByIgnition" SG_ 1702 Heckwischer_Anforderung 0;
BA_ "GenSigSendType" SG_ 1702 Waschen_vorne_aktiv 3;
BA_ "GenSigSwitchedByIgnition" SG_ 1702 Waschen_vorne_aktiv 0;
BA_ "GenSigSendType" SG_ 1702 Wischer1_Wischgeschwindigkeit 0;
BA_ "GenSigStartValue" SG_ 1702 Wischer1_Wischgeschwindigkeit 62;
BA_ "GenSigSwitchedByIgnition" SG_ 1702 Wischer1_Wischgeschwindigkeit 0;
BA_ "Fehlerwert" SG_ 1702 Wischer1_Wischgeschwindigkeit 63;
BA_ "GenSigSendType" SG_ 1702 Wischer_Anzeigetext 3;
BA_ "GenSigSwitchedByIgnition" SG_ 1702 Wischer_Anzeigetext 0;
BA_ "GenSigSendType" SG_ 1702 Wischer_vorne_aktiv 3;
BA_ "GenSigSwitchedByIgnition" SG_ 1702 Wischer_vorne_aktiv 0;
BA_ "GenSigSendType" SG_ 1702 Wischer_vorne_blockiert 3;
BA_ "GenSigSwitchedByIgnition" SG_ 1702 Wischer_vorne_blockiert 0;
BA_ "GenSigSendType" SG_ 1702 Wischer_vorne_defekt 3;
BA_ "GenSigSwitchedByIgnition" SG_ 1702 Wischer_vorne_defekt 0;
BA_ "GenSigSendType" SG_ 1702 Wischer_vorne_Normal 3;
BA_ "GenSigSwitchedByIgnition" SG_ 1702 Wischer_vorne_Normal 0;
BA_ "GenSigSendType" SG_ 1702 Wischer_vorne_Parklage 3;
BA_ "GenSigStartValue" SG_ 1702 Wischer_vorne_Parklage 1;
BA_ "GenSigSwitchedByIgnition" SG_ 1702 Wischer_vorne_Parklage 0;
BA_ "GenSigSendType" SG_ 1702 Wischer_vorne_Schnell 3;
BA_ "GenSigSwitchedByIgnition" SG_ 1702 Wischer_vorne_Schnell 0;
BA_ "GenSigSendType" SG_ 1702 Wischer_WH_PopUp_Anf 3;
BA_ "GenSigSwitchedByIgnition" SG_ 1702 Wischer_WH_PopUp_Anf 0;
BA_ "GenSigSendType" SG_ 1702 Wischer_WH_Typ 0;
BA_ "GenSigSwitchedByIgnition" SG_ 1702 Wischer_WH_Typ 0;
BA_ "GenSigSendType" SG_ 1702 WWSs_01_alt 0;
BA_ "GenSigStartValue" SG_ 1702 WWSs_01_alt 1;
BA_ "GenSigFuncType" SG_ 1702 WWSs_01_alt 5;
BA_ "GenSigSwitchedByIgnition" SG_ 1702 WWSs_01_alt 0;
BA_ "GenSigSwitchedByIgnition" SG_ 2617028096 XCP_Airbag_CRO_01_Data 0;
BA_ "GenSigSwitchedByIgnition" SG_ 2617028097 XCP_Airbag_DTO_01_Data 0;
BA_ "GenSigSwitchedByIgnition" SG_ 2617218560 XCP_Daempfer_CRO_01_Data 0;
BA_ "GenSigSwitchedByIgnition" SG_ 2617218562 XCP_Daempfer_CRO_02_Data 0;
BA_ "GenSigSwitchedByIgnition" SG_ 2617218561 XCP_Daempfer_DTO_01_Data 0;
BA_ "GenSigSwitchedByIgnition" SG_ 2617218563 XCP_Daempfer_DTO_02_Data 0;
BA_ "GenSigFuncType" SG_ 2617105920 XCP_EBKV_CRO_01_Data 9;
BA_ "GenSigSwitchedByIgnition" SG_ 2617105920 XCP_EBKV_CRO_01_Data 0;
BA_ "GenSigFuncType" SG_ 2617105921 XCP_EBKV_DTO_01_Data 9;
BA_ "GenSigSwitchedByIgnition" SG_ 2617105921 XCP_EBKV_DTO_01_Data 0;
BA_ "GenSigSwitchedByIgnition" SG_ 2617024016 XCP_ESC_CRO_01_Data 0;
BA_ "GenSigSwitchedByIgnition" SG_ 2617024017 XCP_ESC_DTO_01_Data 0;
BA_ "GenSigFuncType" SG_ 2617021952 XCP_Lenkhilfe_CRO_01_Data 9;
BA_ "GenSigSwitchedByIgnition" SG_ 2617021952 XCP_Lenkhilfe_CRO_01_Data 0;
BA_ "GenSigFuncType" SG_ 2617021953 XCP_Lenkhilfe_DTO_01_Data 9;
BA_ "GenSigSwitchedByIgnition" SG_ 2617021953 XCP_Lenkhilfe_DTO_01_Data 0;
BA_ "GenSigSendType" SG_ 1411 BCM_FH_Freigabe 3;
BA_ "GenSigSwitchedByIgnition" SG_ 1411 BCM_FH_Freigabe 0;
BA_ "GenSigSendType" SG_ 1411 BCM_HSK_Freigabe 3;
BA_ "GenSigSwitchedByIgnition" SG_ 1411 BCM_HSK_Freigabe 0;
BA_ "GenSigSendType" SG_ 1411 BCM_Komfortfkt_Freigabe 3;
BA_ "GenSigSwitchedByIgnition" SG_ 1411 BCM_Komfortfkt_Freigabe 0;
BA_ "GenSigSendType" SG_ 1411 BCM_Tankklappensteller_Fehler 0;
BA_ "GenSigSwitchedByIgnition" SG_ 1411 BCM_Tankklappensteller_Fehler 0;
BA_ "Fehlerwert" SG_ 1411 BCM_Tankklappensteller_Fehler 1;
BA_ "GenSigSendType" SG_ 1411 BCM_Verdeck_Freigabe 3;
BA_ "GenSigSwitchedByIgnition" SG_ 1411 BCM_Verdeck_Freigabe 0;
BA_ "GenSigSendType" SG_ 1411 DWA_aktiv 3;
BA_ "GenSigSwitchedByIgnition" SG_ 1411 DWA_aktiv 0;
BA_ "GenSigSendType" SG_ 1411 FBS_IDG_in_Reichweite 6;
BA_ "GenSigSwitchedByIgnition" SG_ 1411 FBS_IDG_in_Reichweite 0;
BA_ "GenSigSendType" SG_ 1411 FBS_Warn_Schluessel_Batt 3;
BA_ "GenSigSwitchedByIgnition" SG_ 1411 FBS_Warn_Schluessel_Batt 0;
BA_ "GenSigSendType" SG_ 1411 FFB_Auf_Taste 6;
BA_ "GenSigSwitchedByIgnition" SG_ 1411 FFB_Auf_Taste 0;
BA_ "GenSigSendType" SG_ 1411 FFB_CarFinder 6;
BA_ "GenSigSwitchedByIgnition" SG_ 1411 FFB_CarFinder 0;
BA_ "GenSigSendType" SG_ 1411 FFB_HDF_Taste 6;
BA_ "GenSigSwitchedByIgnition" SG_ 1411 FFB_HDF_Taste 0;
BA_ "GenSigSendType" SG_ 1411 FFB_Komfortoeffnen 6;
BA_ "GenSigSwitchedByIgnition" SG_ 1411 FFB_Komfortoeffnen 0;
BA_ "GenSigSendType" SG_ 1411 FFB_Komfortschliessen 6;
BA_ "GenSigSwitchedByIgnition" SG_ 1411 FFB_Komfortschliessen 0;
BA_ "GenSigSendType" SG_ 1411 FFB_Panik_Taste 6;
BA_ "GenSigSwitchedByIgnition" SG_ 1411 FFB_Panik_Taste 0;
BA_ "GenSigSendType" SG_ 1411 FFB_Zu_Taste 6;
BA_ "GenSigSwitchedByIgnition" SG_ 1411 FFB_Zu_Taste 0;
BA_ "GenSigSendType" SG_ 1411 HBFS_gesafet 3;
BA_ "GenSigSwitchedByIgnition" SG_ 1411 HBFS_gesafet 0;
BA_ "GenSigSendType" SG_ 1411 HBFS_verriegelt 3;
BA_ "GenSigSwitchedByIgnition" SG_ 1411 HBFS_verriegelt 0;
BA_ "GenSigSendType" SG_ 1411 HD_Hauptraste 3;
BA_ "GenSigSwitchedByIgnition" SG_ 1411 HD_Hauptraste 0;
BA_ "GenSigSendType" SG_ 1411 HD_Vorraste 3;
BA_ "GenSigSwitchedByIgnition" SG_ 1411 HD_Vorraste 0;
BA_ "GenSigSendType" SG_ 1411 HFS_gesafet 3;
BA_ "GenSigSwitchedByIgnition" SG_ 1411 HFS_gesafet 0;
BA_ "GenSigSendType" SG_ 1411 HFS_verriegelt 3;
BA_ "GenSigSwitchedByIgnition" SG_ 1411 HFS_verriegelt 0;
BA_ "GenSigSendType" SG_ 1411 IRUE_aktiv 3;
BA_ "GenSigSwitchedByIgnition" SG_ 1411 IRUE_aktiv 0;
BA_ "GenSigSendType" SG_ 1411 IRUE_Taster_Fkts_LED 3;
BA_ "GenSigSwitchedByIgnition" SG_ 1411 IRUE_Taster_Fkts_LED 0;
BA_ "GenSigSendType" SG_ 1411 VIP_Sensor_STSG_HBFS_betaetigt 6;
BA_ "GenSigSwitchedByIgnition" SG_ 1411 VIP_Sensor_STSG_HBFS_betaetigt 0;
BA_ "GenSigSendType" SG_ 1411 VIP_Sensor_STSG_HFS_betaetigt 6;
BA_ "GenSigSwitchedByIgnition" SG_ 1411 VIP_Sensor_STSG_HFS_betaetigt 0;
BA_ "GenSigSendType" SG_ 1411 ZV_Anf_Challenge_Auth 6;
BA_ "GenSigSwitchedByIgnition" SG_ 1411 ZV_Anf_Challenge_Auth 0;
BA_ "GenSigSendType" SG_ 1411 ZV_BT_offen 3;
BA_ "GenSigSwitchedByIgnition" SG_ 1411 ZV_BT_offen 0;
BA_ "GenSigSendType" SG_ 1411 ZV_Einzeltuerentriegelung 3;
BA_ "GenSigSwitchedByIgnition" SG_ 1411 ZV_Einzeltuerentriegelung 0;
BA_ "GenSigSendType" SG_ 1411 ZV_eRWK_Umfeld_Pruefung 6;
BA_ "GenSigSwitchedByIgnition" SG_ 1411 ZV_eRWK_Umfeld_Pruefung 0;
BA_ "GenSigSendType" SG_ 1411 ZV_FT_offen 3;
BA_ "GenSigSwitchedByIgnition" SG_ 1411 ZV_FT_offen 0;
BA_ "GenSigSendType" SG_ 1411 ZV_gesafet_extern_ist 3;
BA_ "GenSigSwitchedByIgnition" SG_ 1411 ZV_gesafet_extern_ist 0;
BA_ "GenSigSendType" SG_ 1411 ZV_gesafet_extern_soll 3;
BA_ "GenSigSwitchedByIgnition" SG_ 1411 ZV_gesafet_extern_soll 0;
BA_ "GenSigSendType" SG_ 1411 ZV_HBFS_offen 3;
BA_ "GenSigSwitchedByIgnition" SG_ 1411 ZV_HBFS_offen 0;
BA_ "GenSigSendType" SG_ 1411 ZV_HD_offen 3;
BA_ "GenSigSwitchedByIgnition" SG_ 1411 ZV_HD_offen 0;
BA_ "GenSigSendType" SG_ 1411 ZV_Heckeinzelentriegelung 3;
BA_ "GenSigSwitchedByIgnition" SG_ 1411 ZV_Heckeinzelentriegelung 0;
BA_ "GenSigSendType" SG_ 1411 ZV_HFS_offen 3;
BA_ "GenSigSwitchedByIgnition" SG_ 1411 ZV_HFS_offen 0;
BA_ "GenSigSendType" SG_ 1411 ZV_HS_offen 3;
BA_ "GenSigSwitchedByIgnition" SG_ 1411 ZV_HS_offen 0;
BA_ "GenSigSendType" SG_ 1411 ZV_ist_Zustand_verfuegbar 3;
BA_ "GenSigSwitchedByIgnition" SG_ 1411 ZV_ist_Zustand_verfuegbar 0;
BA_ "GenSigSendType" SG_ 1411 ZV_Oeffnungsmodus 3;
BA_ "GenSigSwitchedByIgnition" SG_ 1411 ZV_Oeffnungsmodus 0;
BA_ "GenSigSendType" SG_ 1411 ZV_Rollo_auf 3;
BA_ "GenSigSwitchedByIgnition" SG_ 1411 ZV_Rollo_auf 0;
BA_ "GenSigSendType" SG_ 1411 ZV_Rollo_zu 3;
BA_ "GenSigSwitchedByIgnition" SG_ 1411 ZV_Rollo_zu 0;
BA_ "GenSigSendType" SG_ 1411 ZV_SAD_auf 3;
BA_ "GenSigSwitchedByIgnition" SG_ 1411 ZV_SAD_auf 0;
BA_ "GenSigSendType" SG_ 1411 ZV_SAD_zu 3;
BA_ "GenSigSwitchedByIgnition" SG_ 1411 ZV_SAD_zu 0;
BA_ "GenSigSendType" SG_ 1411 ZV_SafeFunktion_aktiv 3;
BA_ "GenSigSwitchedByIgnition" SG_ 1411 ZV_SafeFunktion_aktiv 0;
BA_ "GenSigSendType" SG_ 1411 ZV_Schluessel_Zugang 3;
BA_ "GenSigSwitchedByIgnition" SG_ 1411 ZV_Schluessel_Zugang 0;
BA_ "GenSigSendType" SG_ 1411 ZV_STSG_Crashzustand 4;
BA_ "GenSigSwitchedByIgnition" SG_ 1411 ZV_STSG_Crashzustand 0;
BA_ "GenSigSendType" SG_ 1411 ZV_STSG_eKiSi_defekt 4;
BA_ "GenSigSwitchedByIgnition" SG_ 1411 ZV_STSG_eKiSi_defekt 0;
BA_ "GenSigSendType" SG_ 1411 ZV_STSG_HBFS_Anf 3;
BA_ "GenSigSwitchedByIgnition" SG_ 1411 ZV_STSG_HBFS_Anf 0;
BA_ "GenSigSendType" SG_ 1411 ZV_STSG_HFS_Anf 3;
BA_ "GenSigSwitchedByIgnition" SG_ 1411 ZV_STSG_HFS_Anf 0;
BA_ "GenSigSendType" SG_ 1411 ZV_Tankklappe_offen 0;
BA_ "GenSigSwitchedByIgnition" SG_ 1411 ZV_Tankklappe_offen 0;
BA_ "GenSigSendType" SG_ 1411 ZV_verriegeln_Anf 6;
BA_ "GenSigSwitchedByIgnition" SG_ 1411 ZV_verriegeln_Anf 0;
BA_ "GenSigSendType" SG_ 1411 ZV_verriegelt_extern_ist 3;
BA_ "GenSigSwitchedByIgnition" SG_ 1411 ZV_verriegelt_extern_ist 0;
BA_ "GenSigSendType" SG_ 1411 ZV_verriegelt_extern_soll 3;
BA_ "GenSigSwitchedByIgnition" SG_ 1411 ZV_verriegelt_extern_soll 0;
BA_ "GenSigSendType" SG_ 1411 ZV_verriegelt_intern_ist 3;
BA_ "GenSigSwitchedByIgnition" SG_ 1411 ZV_verriegelt_intern_ist 0;
BA_ "GenSigSendType" SG_ 1411 ZV_verriegelt_intern_soll 3;
BA_ "GenSigSwitchedByIgnition" SG_ 1411 ZV_verriegelt_intern_soll 0;
BA_ "GenSigSendType" SG_ 1411 ZV_verriegelt_soll 3;
BA_ "GenSigSwitchedByIgnition" SG_ 1411 ZV_verriegelt_soll 0;
BA_REL_ "GenSigTimeoutTime" BU_SG_REL_ Airbag SG_ 2264486920 RHP_PreCrash_Anf 500;
BA_REL_ "GenSigTimeoutTime" BU_SG_REL_ Airbag SG_ 2527679688 RHP_ASM_Ereignis 5000;
BA_REL_ "GenSigTimeoutTime" BU_SG_REL_ Airbag SG_ 2527679688 RHP_ASM_Zeitstempel_02 5000;
BA_REL_ "GenSigTimeoutTime" BU_SG_REL_ Airbag SG_ 2527679688 RHP_ASM_Data_1 5000;
BA_REL_ "GenSigTimeoutTime" BU_SG_REL_ Airbag SG_ 2527679688 RHP_ASM_Data_2 5000;
BA_REL_ "GenSigTimeoutTime" BU_SG_REL_ Airbag SG_ 2527679688 RHP_ASM_Data_3 5000;
BA_REL_ "GenSigTimeoutTime" BU_SG_REL_ Airbag SG_ 2527679688 RHP_ASM_Data_4 5000;
BA_REL_ "GenSigTimeoutTime" BU_SG_REL_ Airbag SG_ 2527679688 RHP_ASM_Data_5 5000;
BA_REL_ "GenSigTimeoutTime" BU_SG_REL_ Airbag SG_ 2527679688 RHP_ASM_Data_6 5000;
BA_REL_ "GenSigTimeoutTime" BU_SG_REL_ Airbag SG_ 1610 RKA_FMVSS138_Lampe 5000;
BA_REL_ "GenSigTimeoutTime" BU_SG_REL_ Airbag SG_ 1610 RKA_FMVSS138_MIL 5000;
BA_REL_ "GenSigTimeoutTime" BU_SG_REL_ Airbag SG_ 1413 SI_QRS_Mode 5000;
BA_REL_ "GenSigTimeoutTime" BU_SG_REL_ Airbag SG_ 165 TS_CAN_Ma_Type 1000;
BA_REL_ "GenSigTimeoutTime" BU_SG_REL_ Airbag SG_ 165 TS_CAN_Ma_CRC 1000;
BA_REL_ "GenSigTimeoutTime" BU_SG_REL_ Airbag SG_ 165 TS_CAN_Ma_SequenceCounter 1000;
BA_REL_ "GenSigTimeoutTime" BU_SG_REL_ Airbag SG_ 165 TS_CAN_Ma_TimeDomain 1000;
BA_REL_ "GenSigTimeoutTime" BU_SG_REL_ Airbag SG_ 165 TS_CAN_Ma_OVS 1000;
BA_REL_ "GenSigTimeoutTime" BU_SG_REL_ Airbag SG_ 165 TS_CAN_Ma_SGW 1000;
BA_REL_ "GenSigTimeoutTime" BU_SG_REL_ Airbag SG_ 165 TS_CAN_Ma_SyncTimeSec 1000;
BA_REL_ "GenSigTimeoutTime" BU_SG_REL_ Airbag SG_ 1447 eCall_Funktionsstatus 5000;
BA_REL_ "GenSigTimeoutTime" BU_SG_REL_ Airbag SG_ 995 VS_VD_offen_ver 1000;
BA_REL_ "GenSigTimeoutTime" BU_SG_REL_ Airbag SG_ 1716 VIN_01_MUX 2000;
BA_REL_ "GenSigTimeoutTime" BU_SG_REL_ Airbag SG_ 1716 VIN_4 2000;
BA_REL_ "GenSigTimeoutTime" BU_SG_REL_ Airbag SG_ 1716 VIN_11 2000;
BA_REL_ "GenSigTimeoutTime" BU_SG_REL_ Airbag SG_ 1716 VIN_5 2000;
BA_REL_ "GenSigTimeoutTime" BU_SG_REL_ Airbag SG_ 1716 VIN_12 2000;
BA_REL_ "GenSigTimeoutTime" BU_SG_REL_ Airbag SG_ 1716 VIN_6 2000;
BA_REL_ "GenSigTimeoutTime" BU_SG_REL_ Airbag SG_ 1716 VIN_13 2000;
BA_REL_ "GenSigTimeoutTime" BU_SG_REL_ Airbag SG_ 1716 VIN_7 2000;
BA_REL_ "GenSigTimeoutTime" BU_SG_REL_ Airbag SG_ 1716 VIN_14 2000;
BA_REL_ "GenSigTimeoutTime" BU_SG_REL_ Airbag SG_ 1716 VIN_1 2000;
BA_REL_ "GenSigTimeoutTime" BU_SG_REL_ Airbag SG_ 1716 VIN_8 2000;
BA_REL_ "GenSigTimeoutTime" BU_SG_REL_ Airbag SG_ 1716 VIN_15 2000;
BA_REL_ "GenSigTimeoutTime" BU_SG_REL_ Airbag SG_ 1716 VIN_2 2000;
BA_REL_ "GenSigTimeoutTime" BU_SG_REL_ Airbag SG_ 1716 VIN_9 2000;
BA_REL_ "GenSigTimeoutTime" BU_SG_REL_ Airbag SG_ 1716 VIN_16 2000;
BA_REL_ "GenSigTimeoutTime" BU_SG_REL_ Airbag SG_ 1716 VIN_3 2000;
BA_REL_ "GenSigTimeoutTime" BU_SG_REL_ Airbag SG_ 1716 VIN_10 2000;
BA_REL_ "GenSigTimeoutTime" BU_SG_REL_ Airbag SG_ 1716 VIN_17 2000;
BA_REL_ "GenSigTimeoutTime" BU_SG_REL_ Airbag SG_ 313 VMM_MKB_codiert 500;
BA_REL_ "GenSigTimeoutTime" BU_SG_REL_ Airbag SG_ 313 VZM_Fahrer_bremst_deutlich 500;
BA_REL_ "GenSigTimeoutTime" BU_SG_REL_ Airbag SG_ 313 VZM_aktives_System 500;
BA_REL_ "GenSigTimeoutTime" BU_SG_REL_ Airbag SG_ 313 VZM_Unterdrueckung_Antriebsmom 500;
BA_REL_ "GenSigTimeoutTime" BU_SG_REL_ Airbag SG_ 1411 ZV_verriegelt_extern_ist 2000;
BA_REL_ "GenSigTimeoutTime" BU_SG_REL_ Airbag SG_ 1411 ZV_verriegelt_extern_soll 2000;
BA_REL_ "GenSigTimeoutTime" BU_SG_REL_ Airbag SG_ 1411 ZV_FT_offen 2000;
BA_REL_ "GenSigTimeoutTime" BU_SG_REL_ Airbag SG_ 1411 ZV_BT_offen 2000;
BA_REL_ "GenSigTimeoutTime" BU_SG_REL_ Airbag SG_ 1411 ZV_HFS_offen 2000;
BA_REL_ "GenSigTimeoutTime" BU_SG_REL_ Airbag SG_ 1411 ZV_HBFS_offen 2000;
BA_REL_ "GenSigTimeoutTime" BU_SG_REL_ Airbag SG_ 1411 ZV_HD_offen 2000;
BA_REL_ "GenSigTimeoutTime" BU_SG_REL_ Allrad_Haldex SG_ 1413 SI_NWDF 5000;
BA_REL_ "GenSigTimeoutTime" BU_SG_REL_ Allrad_Haldex SG_ 1413 SI_NWDF_gueltig 5000;
BA_REL_ "GenSigTimeoutTime" BU_SG_REL_ DCC_Gen3 SG_ 1413 SI_NWDF 5000;
BA_REL_ "GenSigTimeoutTime" BU_SG_REL_ DCC_Gen3 SG_ 1413 SI_NWDF_gueltig 5000;
BA_REL_ "GenSigTimeoutTime" BU_SG_REL_ DCC_Gen3 SG_ 1716 VIN_01_MUX 2000;
BA_REL_ "GenSigTimeoutTime" BU_SG_REL_ DCC_Gen3 SG_ 1716 VIN_4 2000;
BA_REL_ "GenSigTimeoutTime" BU_SG_REL_ DCC_Gen3 SG_ 1716 VIN_11 2000;
BA_REL_ "GenSigTimeoutTime" BU_SG_REL_ DCC_Gen3 SG_ 1716 VIN_5 2000;
BA_REL_ "GenSigTimeoutTime" BU_SG_REL_ DCC_Gen3 SG_ 1716 VIN_12 2000;
BA_REL_ "GenSigTimeoutTime" BU_SG_REL_ DCC_Gen3 SG_ 1716 VIN_6 2000;
BA_REL_ "GenSigTimeoutTime" BU_SG_REL_ DCC_Gen3 SG_ 1716 VIN_13 2000;
BA_REL_ "GenSigTimeoutTime" BU_SG_REL_ DCC_Gen3 SG_ 1716 VIN_7 2000;
BA_REL_ "GenSigTimeoutTime" BU_SG_REL_ DCC_Gen3 SG_ 1716 VIN_14 2000;
BA_REL_ "GenSigTimeoutTime" BU_SG_REL_ DCC_Gen3 SG_ 1716 VIN_1 2000;
BA_REL_ "GenSigTimeoutTime" BU_SG_REL_ DCC_Gen3 SG_ 1716 VIN_8 2000;
BA_REL_ "GenSigTimeoutTime" BU_SG_REL_ DCC_Gen3 SG_ 1716 VIN_15 2000;
BA_REL_ "GenSigTimeoutTime" BU_SG_REL_ DCC_Gen3 SG_ 1716 VIN_2 2000;
BA_REL_ "GenSigTimeoutTime" BU_SG_REL_ DCC_Gen3 SG_ 1716 VIN_9 2000;
BA_REL_ "GenSigTimeoutTime" BU_SG_REL_ DCC_Gen3 SG_ 1716 VIN_16 2000;
BA_REL_ "GenSigTimeoutTime" BU_SG_REL_ DCC_Gen3 SG_ 1716 VIN_3 2000;
BA_REL_ "GenSigTimeoutTime" BU_SG_REL_ DCC_Gen3 SG_ 1716 VIN_10 2000;
BA_REL_ "GenSigTimeoutTime" BU_SG_REL_ DCC_Gen3 SG_ 1716 VIN_17 2000;
BA_REL_ "GenSigTimeoutTime" BU_SG_REL_ DCC_Gen3 SG_ 313 VZM_SRBM_Soll 500;
BA_REL_ "GenSigTimeoutTime" BU_SG_REL_ DCC_Gen3 SG_ 313 VZM_SRBM_Ist 500;
BA_REL_ "GenSigTimeoutTime" BU_SG_REL_ ESC_MQBW SG_ 565 Kam_aktiv_Verz_Anf_ASIL 500;
BA_REL_ "GenSigTimeoutTime" BU_SG_REL_ ESC_MQBW SG_ 565 Kam_aktiv_Verz_Anf 500;
BA_REL_ "GenSigTimeoutTime" BU_SG_REL_ ESC_MQBW SG_ 2264486920 RHP_01_CRC 500;
BA_REL_ "GenSigTimeoutTime" BU_SG_REL_ ESC_MQBW SG_ 2264486920 RHP_01_BZ 500;
BA_REL_ "GenSigTimeoutTime" BU_SG_REL_ ESC_MQBW SG_ 2264486920 RHP_Ruckfreigabe 500;
BA_REL_ "GenSigTimeoutTime" BU_SG_REL_ ESC_MQBW SG_ 2264486920 RHP_Warnruckeln_Anf 500;
BA_REL_ "GenSigTimeoutTime" BU_SG_REL_ ESC_MQBW SG_ 2264486920 RHP_Anf_ASIL 500;
BA_REL_ "GenSigTimeoutTime" BU_SG_REL_ ESC_MQBW SG_ 2264486920 RHP_Anforderung_HMS 500;
BA_REL_ "GenSigTimeoutTime" BU_SG_REL_ ESC_MQBW SG_ 2264486920 RHP_Verz_Anf 500;
BA_REL_ "GenSigTimeoutTime" BU_SG_REL_ ESC_MQBW SG_ 2264486920 RHP_Verz_Freigabe 500;
BA_REL_ "GenSigTimeoutTime" BU_SG_REL_ ESC_MQBW SG_ 1413 SI_P_Mode_gueltig 5000;
BA_REL_ "GenSigTimeoutTime" BU_SG_REL_ ESC_MQBW SG_ 1413 SI_T_Mode 5000;
BA_REL_ "GenSigTimeoutTime" BU_SG_REL_ ESC_MQBW SG_ 1413 SI_T_Schutz 5000;
BA_REL_ "GenSigTimeoutTime" BU_SG_REL_ ESC_MQBW SG_ 1413 SI_P_Mode 5000;
BA_REL_ "GenSigTimeoutTime" BU_SG_REL_ ESC_MQBW SG_ 997 TSG_FT_02_CRC 1000;
BA_REL_ "GenSigTimeoutTime" BU_SG_REL_ ESC_MQBW SG_ 997 TSG_FT_02_BZ 1000;
BA_REL_ "GenSigTimeoutTime" BU_SG_REL_ ESC_MQBW SG_ 997 FT_Tuer_Status 1000;
BA_REL_ "GenSigTimeoutTime" BU_SG_REL_ ESC_MQBW SG_ 997 FT_Tuer_Status_QBit 1000;
BA_REL_ "GenSigTimeoutTime" BU_SG_REL_ ESC_MQBW SG_ 2463978710 UserStateServer_01_CRC 1000;
BA_REL_ "GenSigTimeoutTime" BU_SG_REL_ ESC_MQBW SG_ 2463978710 UserStateServer_01_BZ 1000;
BA_REL_ "GenSigTimeoutTime" BU_SG_REL_ ESC_MQBW SG_ 2463978710 OPS_DriverPresenceStatus 1000;
BA_REL_ "GenSigTimeoutTime" BU_SG_REL_ ESC_MQBW SG_ 2463978710 OPS_QBit_DriverPresence 1000;
BA_REL_ "GenSigTimeoutTime" BU_SG_REL_ ESC_MQBW SG_ 2463978710 OPS_SafeDriverPresenceStatus 1000;
BA_REL_ "GenSigTimeoutTime" BU_SG_REL_ ESC_MQBW SG_ 2463978710 OPS_SafeDriverPresence_available 1000;
BA_REL_ "GenSigTimeoutTime" BU_SG_REL_ ESC_MQBW SG_ 1716 VIN_01_MUX 2000;
BA_REL_ "GenSigTimeoutTime" BU_SG_REL_ ESC_MQBW SG_ 1716 VIN_4 2000;
BA_REL_ "GenSigTimeoutTime" BU_SG_REL_ ESC_MQBW SG_ 1716 VIN_11 2000;
BA_REL_ "GenSigTimeoutTime" BU_SG_REL_ ESC_MQBW SG_ 1716 VIN_5 2000;
BA_REL_ "GenSigTimeoutTime" BU_SG_REL_ ESC_MQBW SG_ 1716 VIN_12 2000;
BA_REL_ "GenSigTimeoutTime" BU_SG_REL_ ESC_MQBW SG_ 1716 VIN_6 2000;
BA_REL_ "GenSigTimeoutTime" BU_SG_REL_ ESC_MQBW SG_ 1716 VIN_13 2000;
BA_REL_ "GenSigTimeoutTime" BU_SG_REL_ ESC_MQBW SG_ 1716 VIN_7 2000;
BA_REL_ "GenSigTimeoutTime" BU_SG_REL_ ESC_MQBW SG_ 1716 VIN_14 2000;
BA_REL_ "GenSigTimeoutTime" BU_SG_REL_ ESC_MQBW SG_ 1716 VIN_1 2000;
BA_REL_ "GenSigTimeoutTime" BU_SG_REL_ ESC_MQBW SG_ 1716 VIN_8 2000;
BA_REL_ "GenSigTimeoutTime" BU_SG_REL_ ESC_MQBW SG_ 1716 VIN_15 2000;
BA_REL_ "GenSigTimeoutTime" BU_SG_REL_ ESC_MQBW SG_ 1716 VIN_2 2000;
BA_REL_ "GenSigTimeoutTime" BU_SG_REL_ ESC_MQBW SG_ 1716 VIN_9 2000;
BA_REL_ "GenSigTimeoutTime" BU_SG_REL_ ESC_MQBW SG_ 1716 VIN_16 2000;
BA_REL_ "GenSigTimeoutTime" BU_SG_REL_ ESC_MQBW SG_ 1716 VIN_3 2000;
BA_REL_ "GenSigTimeoutTime" BU_SG_REL_ ESC_MQBW SG_ 1716 VIN_10 2000;
BA_REL_ "GenSigTimeoutTime" BU_SG_REL_ ESC_MQBW SG_ 1716 VIN_17 2000;
BA_REL_ "GenSigTimeoutTime" BU_SG_REL_ ESC_MQBW SG_ 1057 VLK_01_CRC 1000;
BA_REL_ "GenSigTimeoutTime" BU_SG_REL_ ESC_MQBW SG_ 1057 VLK_01_BZ 1000;
BA_REL_ "GenSigTimeoutTime" BU_SG_REL_ ESC_MQBW SG_ 1057 VLK_Anforderung_HMS 1000;
BA_REL_ "GenSigTimeoutTime" BU_SG_REL_ ESC_MQBW SG_ 1057 VLK_Anforderung_Rollfaehigkeit 1000;
BA_REL_ "GenSigTimeoutTime" BU_SG_REL_ ESC_MQBW SG_ 1702 Wischer_vorne_aktiv 5000;
BA_REL_ "GenSigTimeoutTime" BU_SG_REL_ ESC_MQBW SG_ 1702 Wischer_vorne_Parklage 5000;
BA_REL_ "GenSigTimeoutTime" BU_SG_REL_ ESC_MQBW SG_ 1411 ZV_FT_offen 2000;
BA_REL_ "GenSigTimeoutTime" BU_SG_REL_ Gateway_Max SG_ 313 HMS_Systemstatus 500;
BA_REL_ "GenSigTimeoutTime" BU_SG_REL_ Gateway_Max SG_ 313 HMS_Fehlerstatus 500;
BA_REL_ "GenSigTimeoutTime" BU_SG_REL_ Lenkhilfe_REPS SG_ 2264486920 RHP_01_CRC 500;
BA_REL_ "GenSigTimeoutTime" BU_SG_REL_ Lenkhilfe_REPS SG_ 2264486920 RHP_01_BZ 500;
BA_REL_ "GenSigTimeoutTime" BU_SG_REL_ Lenkhilfe_REPS SG_ 2264486920 RHP_QFK_AnfStat 500;
BA_REL_ "GenSigTimeoutTime" BU_SG_REL_ Lenkhilfe_REPS SG_ 2264486920 RHP_QFK_Spuerb 500;
BA_REL_ "GenSigTimeoutTime" BU_SG_REL_ Lenkhilfe_REPS SG_ 2264486920 RHP_QFK_KruemmSoll 500;
BA_REL_ "GenSigTimeoutTime" BU_SG_REL_ Lenkhilfe_REPS SG_ 2264486920 RHP_QFK_Signal1 500;
BA_REL_ "GenSigTimeoutTime" BU_SG_REL_ Lenkhilfe_REPS SG_ 2264486920 RHP_QFK_Art1 500;
BA_REL_ "GenSigTimeoutTime" BU_SG_REL_ Lenkhilfe_REPS SG_ 2264486920 RHP_QFK_Art2 500;
BA_REL_ "GenSigTimeoutTime" BU_SG_REL_ Lenkhilfe_REPS SG_ 2264486920 RHP_QFK_Signal2 500;
BA_REL_ "GenSigTimeoutTime" BU_SG_REL_ Lenkhilfe_REPS SG_ 2264486920 RHP_QFK_KruemmSoll_VZ 500;
BA_REL_ "GenSigTimeoutTime" BU_SG_REL_ Lenkhilfe_REPS SG_ 2264486920 RHP_QFK_KrSoll 500;
BA_REL_ "GenSigTimeoutTime" BU_SG_REL_ Lenkhilfe_REPS SG_ 2264486920 RHP_QFK_KrSoll_VZ 500;
BA_REL_ "GenSigTimeoutTime" BU_SG_REL_ Lenkhilfe_REPS SG_ 1413 SI_NWDF 5000;
BA_REL_ "GenSigTimeoutTime" BU_SG_REL_ Lenkhilfe_REPS SG_ 1413 SI_NWDF_gueltig 5000;
BA_REL_ "GenSigTimeoutTime" BU_SG_REL_ Lenkhilfe_REPS SG_ 1716 VIN_01_MUX 2000;
BA_REL_ "GenSigTimeoutTime" BU_SG_REL_ Lenkhilfe_REPS SG_ 1716 VIN_4 2000;
BA_REL_ "GenSigTimeoutTime" BU_SG_REL_ Lenkhilfe_REPS SG_ 1716 VIN_11 2000;
BA_REL_ "GenSigTimeoutTime" BU_SG_REL_ Lenkhilfe_REPS SG_ 1716 VIN_5 2000;
BA_REL_ "GenSigTimeoutTime" BU_SG_REL_ Lenkhilfe_REPS SG_ 1716 VIN_12 2000;
BA_REL_ "GenSigTimeoutTime" BU_SG_REL_ Lenkhilfe_REPS SG_ 1716 VIN_6 2000;
BA_REL_ "GenSigTimeoutTime" BU_SG_REL_ Lenkhilfe_REPS SG_ 1716 VIN_13 2000;
BA_REL_ "GenSigTimeoutTime" BU_SG_REL_ Lenkhilfe_REPS SG_ 1716 VIN_7 2000;
BA_REL_ "GenSigTimeoutTime" BU_SG_REL_ Lenkhilfe_REPS SG_ 1716 VIN_14 2000;
BA_REL_ "GenSigTimeoutTime" BU_SG_REL_ Lenkhilfe_REPS SG_ 1716 VIN_1 2000;
BA_REL_ "GenSigTimeoutTime" BU_SG_REL_ Lenkhilfe_REPS SG_ 1716 VIN_8 2000;
BA_REL_ "GenSigTimeoutTime" BU_SG_REL_ Lenkhilfe_REPS SG_ 1716 VIN_15 2000;
BA_REL_ "GenSigTimeoutTime" BU_SG_REL_ Lenkhilfe_REPS SG_ 1716 VIN_2 2000;
BA_REL_ "GenSigTimeoutTime" BU_SG_REL_ Lenkhilfe_REPS SG_ 1716 VIN_9 2000;
BA_REL_ "GenSigTimeoutTime" BU_SG_REL_ Lenkhilfe_REPS SG_ 1716 VIN_16 2000;
BA_REL_ "GenSigTimeoutTime" BU_SG_REL_ Lenkhilfe_REPS SG_ 1716 VIN_3 2000;
BA_REL_ "GenSigTimeoutTime" BU_SG_REL_ Lenkhilfe_REPS SG_ 1716 VIN_10 2000;
BA_REL_ "GenSigTimeoutTime" BU_SG_REL_ Lenkhilfe_REPS SG_ 1716 VIN_17 2000;
VAL_ 565 Kam_aktiv_Anforderung_HMS 0 "keine_Anforderung" 1 "Halten" 2 "Parken" 3 "Halten_standby" 4 "Anfahren" 5 "Loesen_ueber_Rampe" 6 "Parken_mit_P" 7 "reserviert" ;
VAL_ 565 Kam_aktiv_Prefill_Anf 0 "keine_Anforderung" 1 "Prefill_Anforderung" ;
VAL_ 565 Kam_aktiv_Verz_Anf_ASIL 0 "ASIL_QM" 1 "ASIL_A" 2 "ASIL_B" 3 "ASIL_C" ;
VAL_ 565 Kam_aktiv_Verz_Anf 126 "Neutralwert" 127 "reserved" ;
VAL_ 565 Kam_aktives_System 0 "Init" 1 "Keine_Aktivitaet" 2 "RPA" 3 "IPA" 4 "MA" 5 "TP" 6 "rTP" 7 "AAA" 8 "rAAA" 9 "ARA_1" 10 "PLA" 11 "RBF" 12 "PHP" 13 "AEB_PR" ;
VAL_ 565 Kam_aktiv_parken_beibehalten 0 "Parken_nicht_beibehalten" 1 "Parken_beibehalten" 2 "Init" 3 "Fehler" ;
VAL_ 565 Kam_aktiv_Notstopp_Anf 0 "Ueberwachung_aus" 1 "Ueberwachung_ein" 2 "Notstopp_ausloesen" ;
VAL_ 565 Kam_aktiv_Warnruck_Anf 0 "Keine_Anforderung" 1 "schwacher_warnruck" 2 "mittlerer_Warnruck" 3 "starker_Warnruck" ;
VAL_ 565 Kam_aktiv_Warnruckeln_Anf 0 "keine_Anforderung" 1 "schwaches_Warnruckeln" 2 "mittleres_Warnruckeln" 3 "starkes_Warnruckeln" ;
VAL_ 565 Kam_aktiv_BKD_Anf 14 "Neutralwert" 15 "Fehler" ;
VAL_ 565 Kam_aktiv_Soll_Anhalteweg_Anf 1022 "Neutralwert" 1023 "Fehler" ;
VAL_ 565 Kam_aktiv_Anhalteweg_Anf 1022 "Neutralwert" 1023 "Fehler" ;
VAL_ 2264486920 RHP_QFK_AnfStat 1 "Init" 2 "Bereit" 4 "Eingriff" 13 "Eingriff_HandsOff" ;
VAL_ 2264486920 RHP_TV_Trigger 0 "No_Request" 1 "Request" ;
VAL_ 2264486920 RHP_QFK_KruemmSoll_VZ 0 "positiv" 1 "negativ" ;
VAL_ 2264486920 RHP_Status_Long 0 "off" 1 "standby" 2 "active" 3 "reserve" 4 "driver_override" 5 "reserve" 6 "reserve" 7 "failure" ;
VAL_ 2264486920 RHP_Ruckfreigabe 0 "keine_Freigabe" 1 "Freigabe" ;
VAL_ 2264486920 RHP_Warnruckeln_Anf 0 "keine_Anforderung" 1 "schwaches_Warnruckeln" 2 "mittleres_Warnruckeln" 3 "starkes_Warnruckeln" ;
VAL_ 2264486920 RHP_Anf_ASIL 0 "QM" 1 "A" 2 "B" 3 "C" ;
VAL_ 2264486920 RHP_Anforderung_HMS 0 "keine_Anforderung" 1 "halten" 2 "parken" 3 "halten_Standby" 4 "anfahren" 5 "loesen_ueber_Rampe" 7 "HMS_uebernehmen" ;
VAL_ 2264486920 RHP_Sollbeschleunigung 2046 "Neutralwert" 2047 "Fehler" ;
VAL_ 2264486920 RHP_TSK_Status 0 "off" 1 "init" 2 "standby" 3 "active" 4 "driver_override" 5 "shutdown" 6 "reversible_failure" 7 "irreversible_failure" ;
VAL_ 2264486920 RHP_Minimale_Bremsung 0 "Anf_Min_Bremsung_nicht_aktiv" 1 "Anf_Min_Bremsung_aktiv" ;
VAL_ 2264486920 RHP_Uss_Anforderung 0 "UltraschallsensorenAus" 1 "UltraschallsensorenAn" ;
VAL_ 2264486920 RHP_Verz_Anf 1023 "keine_Anforderung" ;
VAL_ 2264486920 RHP_Verz_Freigabe 0 "Verzoegerung_nicht_freigeben" 1 "Verzoegerung_freigeben" ;
VAL_ 2264486920 RHP_Status_Lat 0 "off" 1 "standby" 2 "active" 3 "reserve" 4 "driver_oversteer" 5 "reserve" 6 "reserve" 7 "failure" ;
VAL_ 2264486920 RHP_StartStopp_Info 0 "Motorlauf_langfristig_nicht_notwendig_Stoppfreigabe" 1 "Motoranlauf_nicht_zwingend_notwendig_Stoppverbot_keine_Startanforderung" 2 "Motoranlauf_zwingend_notwendig_Startanforderung" 3 "Systemfehler" ;
VAL_ 2264486920 RHP_nachtr_Stopp_Anf 0 "nicht_angefordert" 1 "angefordert" ;
VAL_ 2264486920 RHP_Freilaufstrategie_TSK 0 "Freilaufstr_nicht_angefordert" 1 "Freilaufstr_angefordert" ;
VAL_ 2264486920 RHP_SCAM_HeatingRequest 0 "init" 1 "not_ready" 2 "no_heating_request" 3 "heating_request" ;
VAL_ 2264486920 RHP_Fahrzeughupe_Anf 0 "Keine_Anforderung" 1 "Anforderung_Fahrzeughupe" ;
VAL_ 2264486920 RHP_HOS 0 "not_active" 1 "hands_on" 2 "hands_off" 3 "hands_on_request" ;
VAL_ 2264486920 RHP_Status_Function 0 "off" 1 "standby" 2 "ready" 3 "active" 4 "reserve" 5 "reserve" 6 "reserve" 7 "failure" ;
VAL_ 2264486920 RHP_EA_AnfStat 0 "init" 1 "ready" 2 "interference_PHASE3" ;
VAL_ 2264486920 RHP_QFK_KrSoll_VZ 0 "positiv" 1 "negativ" ;
VAL_ 2264486920 RHP_Warnblinken 0 "kein_Blinken" 1 "Warnblinken_Taster" ;
VAL_ 2264486920 RHP_Innenraumlicht_Anf 0 "Innenraumbeleuchtung_ausschalten" 1 "Innenraumbeleuchtung_einschalten" ;
VAL_ 2264486920 RHP_Spurwechsel_Ready 0 "nicht_moeglich" 1 "links_moeglich" 2 "rechts_moeglich" 3 "links_rechts_moeglich" 4 "links_blinken" 5 "rechts_blinken" ;
VAL_ 2264486920 RHP_RBF_Available 0 "Init" 1 "Available" 2 "NotAvailable" 3 "Reserved" ;
VAL_ 2264486920 RHP_PreCrash_Anf 0 "keine_Anforderung" 1 "Aktionsgenerierte_Warnung_1" 2 "Aktionsgenerierte_Warnung_2" 3 "Aktionsgenerierte_Warnung_3" 4 "Aktionsgenerierte_Warnung_4" 5 "Aktionsgenerierte_Warnung_5" 6 "Aktionsgenerierte_Warnung_6" 7 "Aktionsgenerierte_Warnung_7" ;
VAL_ 2264486920 RHP_EA_PreCrash 0 "Keine_Anforderung" 1 "Aktionsgenerierte_Warnung_1" 2 "Aktionsgenerierte_Warnung_2" 3 "Aktionsgenerierte_Warnung_3" 4 "Aktionsgenerierte_Warnung_4" 5 "Aktionsgenerierte_Warnung_5" 6 "Aktionsgenerierte_Warnung_6" 7 "Aktionsgenerierte_Warnung_7" ;
VAL_ 2264486920 RHP_Parking_St 0 "None" 1 "Slot_detect" 2 "Guidance" 3 "Abort" ;
VAL_ 2264486920 RHP_EA_Innenraumlicht 0 "Innenraumbeleuchtun_ausschalten" 1 "Innenraumbeleuchtung_einschalten" ;
VAL_ 2264486920 RHP_EA_eCall 0 "Keine_Anforderung" 1 "Ausloesen_eCall" ;
VAL_ 2264486920 RHP_OPSEnable 0 "Initial" 1 "Not_enable" 2 "Enable" ;
VAL_ 2264486920 RHP_eCall_Anf 0 "Keine_Anforderung" 1 "Ausloesen_eCall" ;
VAL_ 2264486920 RHP_EA_Tueren 0 "Keine_Anforderung" 1 "Tueren_entriegeln" ;
VAL_ 2527679688 RHP_ASM_Ereignis 0 "No_Event" 255 "ASM_Trigger" ;
VAL_ 2527679688 RHP_ASM_Zeitstempel_02 255 "Init" ;
VAL_ 1610 RKA_FMVSS138_Lampe 0 "keine Warnung" 1 "Warnlampe FMVSS 138, gelbe Lampe statisch an" ;
VAL_ 1610 RKA_Warnungen_02 0 "keine_Anzeige" 1 "Kontrollleuchte" 2 "Systemfehler" 3 "Reifen_allgemein_Warnstufe_1" 4 "Reifen_vorne_links_Warnstufe_1" 5 "Reifen_vorne_rechts_Warnstufe_1" 6 "Reifen_hinten_links_Warnstufe_1" 7 "Reifen_hinten_rechts_Warnstufe_1" 8 "Reifen_allgemein_Warnstufe_2" 9 "Reifen_vorne_links_Warnstufe_2" 10 "Reifen_vorne_rechts_Warnstufe_2" 11 "Reifen_hinten_links_Warnstufe_2" 12 "Reifen_hinten_rechts_Warnstufe_2" 13 "Reifen_allgemein_Warnstufe_3" 14 "Reifen_vorne_links_Warnstufe_3" 15 "Reifen_vorne_rechts_Warnstufe_3" 16 "Reifen_hinten_links_Warnstufe_3" 17 "Reifen_hinten_rechts_Warnstufe_3" 18 "Reifendruecke_kalibrieren" 19 "Akustik" 20 "Systemfehler_Lampe_Text" 21 "Reifen_allgemein_Lampe_Text" 22 "Reifen_vorne_links_Lampe_Text" 23 "Reifen_vorne_rechts_Lampe_Text" 24 "Reifen_hinten_links_Lampe_Text" 25 "Reifen_hinten_rechts_Lampe_Text" 26 "Reifendruecke_kalibrieren_Text_Gong" 27 "Reifendruecke_kalibrieren_Text_Gong_Lampe" 28 "Reifenwechsel_erkannt" ;
VAL_ 1610 RKA_Reifentyp 0 "Init" 1 "Winter" 2 "Sommer" 3 "Ganzjahresreifen" 4 "Kundenspezifisch" ;
VAL_ 2589283756 SOK_ungeschuetzte_Zeit 0 "Init" ;
VAL_ 1413 SI_Sammel_SG_Fehler 61 "Reserviert" 62 "Overflow" 63 "ungueltig" ;
VAL_ 1413 SI_P_Mode_gueltig 0 "dezentraler_Produktionsmode" 1 "zentraler_Produktionsmode" ;
VAL_ 1413 SI_Diagnose_Aktiv 0 "inaktiv" 1 "aktiv" ;
VAL_ 1413 SI_QRS_Mode 0 "QRS_Messmodus_nicht_aktiv" 1 "QRS_Messmodus_aktiv" ;
VAL_ 1413 SI_T_Mode 0 "Transportmodus_nicht_aktiv" 1 "Transportmodus_aktiv" ;
VAL_ 1413 SI_NWDF 0 "Ueberwachung_nicht_freigegeben" 1 "Ueberwachung_freigegeben" ;
VAL_ 1413 SI_NWDF_gueltig 0 "NWDF_wird_nicht_unterstuetzt" 1 "NWDF_wird_unterstuetzt" ;
VAL_ 1413 SI_Sammelfehler 0 "kein_Sammelfehler" 1 "Sammelfehler" ;
VAL_ 1413 GW_KD_Fehler 0 "kein_KD_Fehler" 1 "KD_Fehler" ;
VAL_ 1413 SI_T_Schutz 0 "Transportschutz_nicht_aktiv" 1 "Transportschutz_aktiv" ;
VAL_ 1413 SI_P_Mode 0 "inaktiv" 1 "aktiv" ;
VAL_ 1413 SI_BUS_01 0 "keine_Busruhe" 1 "Busruhe" ;
VAL_ 1413 SI_BUS_02 0 "keine_Busruhe" 1 "Busruhe" ;
VAL_ 1413 SI_BUS_03 0 "keine_Busruhe" 1 "Busruhe" ;
VAL_ 1413 SI_BUS_04 0 "keine_Busruhe" 1 "Busruhe" ;
VAL_ 1413 SI_BUS_05 0 "keine_Busruhe" 1 "Busruhe" ;
VAL_ 1413 SI_BUS_06 0 "keine_Busruhe" 1 "Busruhe" ;
VAL_ 1413 SI_BUS_07 0 "keine_Busruhe" 1 "Busruhe" ;
VAL_ 1413 SI_BUS_08 0 "keine_Busruhe" 1 "Busruhe" ;
VAL_ 1413 SI_BUS_09 0 "keine_Busruhe" 1 "Busruhe" ;
VAL_ 1413 SI_BUS_10 0 "keine_Busruhe" 1 "Busruhe" ;
VAL_ 1413 SI_BUS_11 0 "keine_Busruhe" 1 "Busruhe" ;
VAL_ 1413 SI_BUS_12 0 "keine_Busruhe" 1 "Busruhe" ;
VAL_ 1413 SI_BUS_13 0 "keine_Busruhe" 1 "Busruhe" ;
VAL_ 1413 SI_BUS_14 0 "keine_Busruhe" 1 "Busruhe" ;
VAL_ 1413 SI_BUS_15 0 "keine_Busruhe" 1 "Busruhe" ;
VAL_ 1413 SI_NWDF_30 0 "Ueberwachung_nicht_freigegeben" 1 "Ueberwachung_freigegeben" ;
VAL_ 1413 SI_Bus_Identifikation 16 "CAN_Diagnose" 17 "CAN_Antrieb" 18 "CAN_Komfort" 19 "CAN_Infotainment" 20 "CAN_Fahrwerk" 21 "CAN_Extended" 22 "CAN_Hybrid" 23 "CAN_Lade" 24 "CAN_Kombi" 25 "CAN_Komfort_2" 26 "CAN_AFS" 27 "CAN_MIB" 28 "CAN_Batterie_BMC" 29 "CAN_Motor" 31 "CAN_Airbag_Sicherheitssysteme" 33 "CAN_FahrerAssistenzSysteme" 34 "CAN_Migration" 35 "CAN_Connect" 36 "CAN_AnzeigeBedienung" 37 "CAN_ElectricalVehicle" 40 "CAN_Telematik" 41 "CAN_MFL" 42 "CAN_FahrerAssistenzSysteme_2" 43 "CAN_FahrerAssistenzSysteme_3" 47 "CAN_Komfort_3" 48 "FlexRay_A" 49 "FlexRay_B" 97 "VLAN_FAS" 98 "VLAN_Infotainment" 99 "VLAN_Connect" 100 "VLAN_Komfort" 101 "VLAN_Antrieb" 102 "VLAN_Diagnose" 103 "VLAN_Internet" 104 "VLAN_Gateway" 105 "VLAN_Remote_FC" 106 "VLAN_Connect_2" 107 "VLAN_Licht" 108 "VLAN_Charge" 109 "VLAN_Cockpit" 110 "VLAN_Connect_3" 111 "VLAN_IoT" 112 "VLAN_CarPerformance" 113 "VLAN_ConMod" 114 "VLAN_FAS2" 176 "HCP1_CANFD01" 177 "HCP1_CANFD02" 178 "HCP1_CANFD03" 179 "HCP1_CANFD04" 180 "HCP1_CANFD05" 181 "HCP1_CANFD06" 182 "HCP1_CANFD07" 183 "HCP1_CANFD08" 186 "HCP4_CANFD03" 187 "HCP4_CANFD04" 188 "HCP1_CANFD09" 189 "HCP4_CANFD06" 190 "HCP4_CANFD07" 191 "HCP4_CANFD08" 192 "HCP4_CANFD09" 193 "HCP4_CANFD10" 194 "HCP1_CANFD10" 195 "ICAS1_CANFD2_HCP5_CANFD02" 196 "HCP1_CANFD11" 197 "WU_HCP1_CANFD" 199 "WU_HCP2_CANFD" 200 "WU_HCP3_CANFD" 201 "WU_HCP4_CANFD" 202 "HCP3_CANFD02" 204 "ESC_CANFD" 205 "HCP4_CANFD11" 206 "HCP4_CANFD12" 207 "CAN_Innenraumsensorik" 212 "WU_ConMod_CANFD" 213 "WU_PASD_CANFD" 215 "CAN_MobileDeviceKey" 217 "CAN_Tuerantrieb_VL" 218 "CAN_Tuerantrieb_VR" 219 "CAN_Tuerantrieb_HL" 220 "CAN_Tuerantrieb_HR" ;
VAL_ 1413 SI_CAB_V14 0 "Init" 1 "CAB_01_Antrieb" 2 "CAB_02_Hybrid_Laden" 4 "CAB_03_Fahrwerk" 8 "CAB_04_Fahrerassistenz" 16 "CAB_05_Komfort" 32 "CAB_06_Anzeige" 64 "CAB_07_Connect" 128 "CAB_08_MIB" 256 "CAB_09_Standheizung" 1024 "CAB_11_VLAN_Fahrerassistenz" 2048 "CAB_12_VLAN_Komfort" 4096 "CAB_13_VLAN_Connect" 8192 "CAB_14_VLAN_Infotainment" 16384 "CAB_15_Laden" 32768 "CAB_16_Licht" ;
VAL_ 165 TS_CAN_Ma_Type 32 "SYNC_CRC_secured_message_format" 40 "FUP_CRC_secured_message_format" ;
VAL_ 165 TS_CAN_Ma_SGW 0 "SyncToGTM" 1 "SyncToSubDomain" ;
VAL_ 1447 ORU_KombiTimer 0 "ORU_Inaktiv" 1 "ORU_Start" ;
VAL_ 1447 MOD_Energie_Anf 0 "Keine_Anforderung" 1 "Anforderung_NV" 2 "Anforderung_HV_Nutzung_Erlaubt" 3 "Fehler" ;
VAL_ 1447 FaceRec_Enroll_Challenge_Request 0 "SEND_NOTHING" 1 "SEND_CHALLENGE" ;
VAL_ 1447 eCall_Mute_Anf 0 "kein_mute" 1 "mute" ;
VAL_ 1447 FoD_Anz_Funktionsabschaltung 0 "Init" 1 "Popup_aufschalten" ;
VAL_ 1447 iCall_active 0 "inaktiv" 1 "aktiv" ;
VAL_ 1447 bCall_active 0 "bcall_inactive" 1 "bcall_active" ;
VAL_ 1447 MOD_Request_ServiceKey 0 "Init" 1 "Aktuallisierungsanfrage" ;
VAL_ 1447 eCall_Funktionsstatus_02 0 "kein_Fehler" 1 "Manueller_Notruf_aktiv" 2 "Automatischer_Notruf_aktiv" 7 "Init" ;
VAL_ 1447 eCall_Funktionsstatus 0 "kein_Fehler" 1 "Fkt_eingeschraenkt" 2 "Fkt_eingeschraenkt_service" 3 "Fkt_nicht_verfuegbar" 4 "Fkt_Service" 5 "Fkt_deaktiviert" 6 "Fkt_aktiviert" 7 "init" ;
VAL_ 1447 TM_Spiegel_Anklappen 0 "Init" 1 "Spiegel_anklappen" ;
VAL_ 1447 TM_Nur_Hupen 0 "inaktiv" 1 "aktiv" ;
VAL_ 1447 TM_Door_Lock 0 "Init" 1 "door_lock" ;
VAL_ 1447 TM_Door_Unlock 0 "Init" 1 "door_unlock" ;
VAL_ 1447 TM_Warnblinken 0 "Init" 1 "Warnblinken_on" ;
VAL_ 1447 TM_Panik_Alarm 0 "Init" 1 "panik_alarm_on" ;
VAL_ 1447 TM_ZV_Signatur 0 "Init" ;
VAL_ 997 FT_Tuer_Status 0 "Init" 1 "Tuer_geschlossen" 2 "Tuer_offen" 3 "Fehler" ;
VAL_ 997 FT_Tuer_Status_QBit 0 "Status_Tuerkontakt_sicher" 1 "Status_Tuerkontakt_unsicher" ;
VAL_ 997 FT_Lock_Taster_02 0 "nicht_betaetigt" 1 "betaetigt" ;
VAL_ 997 FT_Schluesselschalter_zu_02 0 "nicht_betaetigt" 1 "betaetigt" ;
VAL_ 997 FT_BFS_Tuer_Status 0 "Init" 1 "Tuer_geschlossen" 2 "Tuer_offen" 3 "Fehler" ;
VAL_ 997 FT_HBFS_Tuer_Status 0 "Init" 1 "Tuer_geschlossen" 2 "Tuer_offen" 3 "Fehler" ;
VAL_ 997 FT_HFS_Tuer_Status 0 "Init" 1 "Tuer_geschlossen" 2 "Tuer_offen" 3 "Fehler" ;
VAL_ 997 FT_Tueroeffnen_Warnung 0 "Tuerwarnung_nicht_aktiv" 1 "Tuerwarnung_aktiv" ;
VAL_ 997 FT_SP_Heizung_ein 0 "Aus" 1 "Ein" ;
VAL_ 997 FT_Kisi_Taster_li_02 0 "nicht_betaetigt" 1 "betaetigt" ;
VAL_ 997 FT_Kisi_Taster_re_02 0 "nicht_betaetigt" 1 "betaetigt" ;
VAL_ 997 FT_TD_Taste_Status 0 "kein_Fehler" 1 "Kurzschluss_nach_Minus" 2 "Kurzschluss_nach_Plus" 3 "Leitungsunterbrechung" ;
VAL_ 997 FT_TCR_Mode_aktiv 0 "TCR_Mode_deaktiv" 1 "TCR_Mode_aktiv" ;
VAL_ 997 TBF_FS_Touch_Event 0 "nicht_betaetigt" 1 "Tippen" 2 "Wischen" 3 "Geste" 4 "Doppeltippen" 5 "Longpress_1" 6 "Longpress_2" 7 "reserviert" 8 "reserviert" 9 "reserviert" 10 "reserviert" 11 "reserviert" 12 "reserviert" 13 "reserviert" 14 "reserviert" 15 "reserviert" ;
VAL_ 997 FT_KiSi_Status_Soll_HBFS 0 "inaktiv" 1 "aktiv" ;
VAL_ 997 FT_KiSi_Status_Soll_HFS 0 "inaktiv" 1 "aktiv" ;
VAL_ 997 FS_Push_Tuergriff 0 "nicht_erkannt" 1 "erkannt" ;
VAL_ 997 TSG_FS_Spiegel_angeklappt 0 "Spiegel_ausgeklappt" 1 "Spiegel_eingeklappt" ;
VAL_ 997 FT_Cargolock_bet 0 "nicht_betaetigt" 1 "betaetigt" ;
VAL_ 997 FT_kisi_asynchron 0 "nicht_aktiv" 1 "aktiv" ;
VAL_ 997 eTAB_FS_Bowdenzug_Auswerfen 0 "nicht_auswerfen" 1 "auswerfen" ;
VAL_ 997 FS_Status_eTAG_ext 0 "Griff_eingefahren" 1 "Griff_ausgefahren" 2 "Griff_verfaehrt" 3 "init" 4 "Fehler" ;
VAL_ 997 FT_ASW_Warnton 0 "kein_warnton" 1 "warnton_links" 2 "warnton_rechts" 3 "Fehler" ;
VAL_ 997 SSA_FT_ASW_Status 0 "Init" 1 "InfoStufe_aktiv" 2 "Warnstufe_aktiv" ;
VAL_ 2589283772 TSL_Warnung 0 "keine_Anzeige" 1 "Fehler_Torquesplitter" ;
VAL_ 2589283772 TSL_Hinweis 0 "Keine_Anzeige" 1 "Hinweis_thermische_Degradierung" 2 "Hinweis_reduzierte_Performance" 3 "Hinweis_Vorhalt" ;
VAL_ 2589283772 QSP_Temperatur_Oel 127 "Fehler" ;
VAL_ 2589283772 QSP_Warnlampe 0 "Warnlampe aus" 1 "Warnlampe ein (Aufprüfen), zur Zeit nicht belegt" 2 "Warnlampe ein (Warnung)  =  Fehler" 3 "Warnlampe ein (Übertemperatur)" ;
VAL_ 2589283772 QSP_Thermische_Belastung 63 "Fehler" ;
VAL_ 2589283773 TSR_Warnung 0 "keine_Anzeige" 1 "Fehler_Torquesplitter" ;
VAL_ 2589283773 TSR_Hinweis 0 "Keine_Anzeige" 1 "Hinweis_thermische_Degradierung" 2 "Hinweis_reduzierte_Performance" 3 "Hinweis_Vorhalt" ;
VAL_ 2589283773 TSR_Temperatur_Oel 127 "Fehler" ;
VAL_ 2589283773 TSR_Warnlampe 0 "Warnlampe aus" 1 "Warnlampe ein (Aufprüfen), zur Zeit nicht belegt" 2 "Warnlampe ein (Warnung)  =  Fehler" 3 "Warnlampe ein (Übertemperatur)" ;
VAL_ 2589283773 TSR_Thermische_Belastung 63 "Fehler" ;
VAL_ 2463978710 OPS_ComfortReadyStatus 0 "Init" 1 "aktiv" 2 "inaktiv" 3 "Fehler" ;
VAL_ 2463978710 OPS_OccupantPresenceStatus 0 "Init" 1 "OccupantAbsent" 2 "reserviert" 3 "OccupantEntryExit" 4 "reserviert" 5 "OccupantPresent" 6 "OccupantPresentVerified" 7 "Fehler" ;
VAL_ 2463978710 OPS_DriverPresenceStatus 0 "Init" 1 "reserviert" 2 "DriverAbsent" 3 "reserviert" 4 "DriverEntry" 5 "reserviert" 6 "DriverPresent" 7 "reserviert" 8 "DriverPresentVerified" 9 "reserviert" 10 "reserviert" 11 "DriverExitIntent" 12 "reserviert" 13 "DriverExit" 14 "reserviert" 15 "Fehler" ;
VAL_ 2463978710 OPS_QBit_DriverPresence 0 "gueltiger_Wert" 1 "Ersatz_Init_oder_Fehlerwert" ;
VAL_ 2463978710 OPS_SafeDriverPresenceStatus 0 "Init" 1 "Driver_Safe_Present" 2 "Driver_Not_Safe_Present" 3 "Fehler" ;
VAL_ 2463978710 OPS_SafeDriverPresence_available 0 "Verfuegbar" 1 "Verfuegbar_eingeschr_Performance" ;
VAL_ 995 VS_VD_zu_ver 1 "Zustand des Verdecks verriegelt und geschlossen" ;
VAL_ 995 VS_VD_entriegelt 0 "Init" 1 "Zustand_des_Verdeck_entriegelt" ;
VAL_ 995 VS_VD_offen_ver 0 "Init" 1 "Verdeck_verriegelt_und_offen" ;
VAL_ 995 VS_VD_Zwischenposition 0 "Init" 1 "Verdeck_in_Zwischenposition" ;
VAL_ 995 VS_VD_Bew_auf 1 "Verdeck in Bewegung auf" ;
VAL_ 995 VS_VD_Bew_zu 1 "Verdeck in Bewegung zu" ;
VAL_ 995 VS_Verdeck_Anf 0 "init_nicht_aktiv" 1 "aktiv" ;
VAL_ 995 VS_Hardtop 0 "Init" 1 "Hardtop_montiert" ;
VAL_ 995 VS_VD_Fehler 0 "Init" 1 "Fehlerzustand Verdeck" ;
VAL_ 995 VS_Lampe_Blk 0 "Kontrollleuchte_inaktiv" 1 "Kontrollleuchte_aktiv" ;
VAL_ 995 VS_HD_sperren 0 "HD Entriegelung freigegeben" 1 "HD Entriegelung gesperrt" ;
VAL_ 995 VS_HHS_enable 0 "Init" 1 "Freigabe HHS" ;
VAL_ 995 VD_SpannungsAnf 0 "keine_Anforderung" 1 "Anforderung_Stufe1" 2 "Anforderung_Stufe2" 3 "Anforderung_Stufe3" ;
VAL_ 995 VS_VDKD_auf 0 "VDKD_nicht_vollst_auf" 1 "VDKD_vollstaendig_auf" ;
VAL_ 995 VS_FS_AutoHoch 0 "Keine_Verfahranforderung" 1 "Automatischer_Hochlauf" ;
VAL_ 995 VS_FS_AutoTief 0 "Keine_Verfahranforderung" 1 "Automatischer_Tieflauf" ;
VAL_ 995 VS_FS_ManHoch 0 "Keine_Verfahranforderung" 1 "Manueller_Hochlauf" ;
VAL_ 995 VS_FS_ManTief 0 "Keine_Verfahranforderung" 1 "Manueller_Tieflauf" ;
VAL_ 995 VS_BFS_AutoHoch 0 "Keine_Verfahranforderung" 1 "Automatischer_Hochlauf" ;
VAL_ 995 VS_BFS_AutoTief 0 "Keine_Verfahranforderung" 1 "Automatischer_Tieflauf" ;
VAL_ 995 VS_BFS_ManHoch 0 "Keine_Verfahranforderung" 1 "Manueller_Hochlauf" ;
VAL_ 995 VS_BFS_ManTief 0 "Keine_Verfahranforderung" 1 "Manueller_Tieflauf" ;
VAL_ 995 VS_HFS_AutoHoch 0 "Keine_Verfahranforderung" 1 "Automatischer_Hochlauf" ;
VAL_ 995 VS_HFS_AutoTief 0 "Keine_Verfahranforderung" 1 "Automatischer_Tieflauf" ;
VAL_ 995 VS_HFS_ManHoch 0 "Keine_Verfahranforderung" 1 "Manueller_Hochlauf" ;
VAL_ 995 VS_HFS_ManTief 0 "Keine_Verfahranforderung" 1 "Manueller_Tieflauf" ;
VAL_ 995 VS_HBFS_AutoHoch 0 "Keine_Verfahranforderung" 1 "Automatischer_Hochlauf" ;
VAL_ 995 VS_HBFS_AutoTief 0 "Keine_Verfahranforderung" 1 "Automatischer_Tieflauf" ;
VAL_ 995 VS_HBFS_ManHoch 0 "Keine_Verfahranforderung" 1 "Manueller_Hochlauf" ;
VAL_ 995 VS_HBFS_ManTief 0 "Keine_Verfahranforderung" 1 "Manueller_Tieflauf" ;
VAL_ 995 VS_FH_FT_Langhub 0 "Init" ;
VAL_ 995 VS_Windschott_nicht_abgelegt 0 "inaktiv" 1 "aktiv" ;
VAL_ 995 VS_FH_BT_Langhub 0 "Init" ;
VAL_ 995 VS_FH_HFS_Langhub 0 "Init" ;
VAL_ 995 VS_Heckschloss_auf 0 "kein_Oeffnen" 1 "Heckschloss_oeffnen" ;
VAL_ 995 VS_FH_HBFS_Langhub 0 "Init" ;
VAL_ 995 VSG_Meldungen 0 "keine_Meldung" ;
VAL_ 995 VS_StartStopp_Info 0 "Stoppfreigabe" 1 "Stoppverbot" 2 "Startanforderung" 3 "Fehler" ;
VAL_ 1057 VLK_Anforderung_HMS 0 "keine_Anforderung" 1 "halten" 2 "parken" 3 "halten_Standby" 4 "anfahren" 5 "Loesen_ueber_Rampe" 6 "Parken_mit_P" 7 "HMS_uebernehmen" ;
VAL_ 1057 VLK_autom_Absch_Signalisierung 0 "Init" 1 "Automatisierte_Abschaltung" ;
VAL_ 1057 VLK_VLW_Anf 0 "Init" 1 "VLW_angefordert" 2 "degradierte_VLW_FT_Fehler" 3 "reserved" ;
VAL_ 1057 VLK_Anforderung_Rollfaehigkeit 0 "Rollfaehigkeitsmode_inaktiv_Init" 1 "Rollfaehigkeitsmodus_aktiv" ;
VAL_ 1057 VLK_Parken_beibehalten_HMS 0 "Parken_nicht_beibehalten" 1 "Parken_beibehalten" 2 "Init" 3 "Fehler" ;
VAL_ 1057 VLK_Hinweis_Rollfaehigkeit 0 "Init_keinHinweis" 1 "Hinweis_ohne_Akustik" 2 "Hinweis_mit_Akustik" 3 "reserviert" ;
VAL_ 1057 VLK_Antriebsdeaktivierung 0 "Keine_Einschraenkung" 1 "Antrieb_deaktivieren" 3 "Fehler" ;
VAL_ 1057 VLK_Anf_Antrieb 0 "Init" 1 "Freigabe" 2 "VKM_Zustand_einfrieren" 3 "Zustartverbot_fuer_Fahrer" 5 "Startanforderung" 7 "Fehler" ;
VAL_ 1057 VLK_Hinweis_Weiterfahrt 0 "inaktiv" 1 "aktiv" ;
VAL_ 1057 VLK_Hinweis_Fehler_Gurt 0 "inaktiv" 1 "aktiv" ;
VAL_ 1057 VLK_Hinweis_Fehler_Sitz 0 "inaktiv" 1 "aktiv" ;
VAL_ 1057 VLK_Hinweis_Fehler_Tuer 0 "inaktiv" 1 "aktiv" ;
VAL_ 1057 VLK_Hinweis_dgr_VLW 0 "inaktiv" 1 "aktiv" ;
VAL_ 1057 VLK_Hinweis_KA_bevorstehend 0 "inaktiv" 1 "aktiv" ;
VAL_ 313 VZM_aktiver_Basisservice 0 "Keine_Aktivitaet" 1 "Bremsenkonditionierung" 2 "Bremsruck" 3 "Verzoegerungsregelung" 4 "Wegregelung" ;
VAL_ 313 VZM_Anhalteweg_nicht_verfuegbar 0 "verfuegbar" 1 "nicht_verfuegbar" ;
VAL_ 313 VZM_Fahrer_bremst 0 "Bremsdruckschwelle_nicht_ueberschritten" 1 "Bremsdruckschwelle_ueberschritten" ;
VAL_ 313 VZM_QBit_Fahrer_bremst 0 "gueltiger_Wert" 1 "Ersatz_Init_oder_Fehlerwert" ;
VAL_ 313 VMM_MKB_codiert 0 "MKB_nicht_codiert" 1 "MKB_codiert" ;
VAL_ 313 VMM_Inkonsistenz_EBKV 0 "konsistent" 1 "nicht_konsistent" ;
VAL_ 313 VMM_Notstopp_Status 0 "Init" 1 "verfuegbar" 2 "warten_auf_sekundaer_System" 3 "passiv_Ueberwachung" 4 "aktiv_ausgeloest" 7 "Fehler" ;
VAL_ 313 VZM_Warnruck_nicht_verfuegbar 0 "verfuegbar" 1 "nicht_verfuegbar" ;
VAL_ 313 VZM_Warnruckeln_nicht_verfuegbar 0 "verfuegbar" 1 "nicht_verfuegbar" ;
VAL_ 313 VZM_Bkd_nicht_verfuegbar 0 "verfuegbar" 1 "nicht_verfuegbar" ;
VAL_ 313 VMM_Bremslicht_defekt 0 "Bremslichter_nicht_defekt" 1 "Bremslichter_defekt" ;
VAL_ 313 VZM_Fahrer_bremst_deutlich 0 "Fahrer_bremst_nicht_deutlich" 1 "Fahrer_bremst_deutlich" ;
VAL_ 313 VZM_TSK_SRBM_Anf 0 "keine_Aktivitaet" 1 "Aktivitaet_durch_TSK" ;
VAL_ 313 VZM_TSK_SRBM_nicht_verfuegbar 0 "verfuegbar" 1 "nicht_verfuegbar" ;
VAL_ 313 VZM_Verz_Reg_aktiv 0 "keine_Aktivitaet" 2 "Aktivitaet_durch_AWV_PCF" 3 "Aktivitaet_durch_EA" 4 "Aktivitaet_durch_TSK" 5 "Aktivitaet_durch_RCTA" 6 "Aktivitaet_durch_ParkAssist" 7 "Aktivitaet_durch_ACC" 8 "Aktivitaet_durch_ARA" 9 "Aktivitaet_durch_NV" 10 "Aktivitaet_durch_KAS" 11 "Aktivitaet_durch_FAS_VK" 12 "Aktivitaet_durch_vESC" 13 "Aktivitaet_durch_KAM" 14 "Aktivitaet_durch_BRS_intern" 15 "Aktivitaet_durch_AEB" 16 "Aktivitaet_durch_MKB" ;
VAL_ 313 VZM_Verz_Reg_nicht_verfuegbar 0 "verfuegbar" 1 "nicht_verfuegbar" ;
VAL_ 313 VMM_Inkonsistenz_KAS 0 "konsistent" 1 "nicht_konsistent" ;
VAL_ 313 VMM_Bremslicht_unplausibel 0 "plausibel" 1 "unplausibel" ;
VAL_ 313 VMM_Inkonsistenz_ACC 0 "konsistent" 1 "nicht_konsistent" ;
VAL_ 313 VMM_Inkonsistenz_AWV_PCF 0 "konsistent" 1 "nicht_konsistent" ;
VAL_ 313 VMM_Inkonsistenz_ARA 0 "konsistent" 1 "nicht_konsistent" ;
VAL_ 313 VMM_Inkonsistenz_ParkAssist 0 "konsistent" 1 "nicht_konsistent" ;
VAL_ 313 VMM_Inkonsistenz_FAS_VK 0 "konsistent" 1 "nicht_konsistent" ;
VAL_ 313 VMM_Inkonsistenz_NV 0 "konsistent" 1 "nicht_konsistent" ;
VAL_ 313 VMM_Inkonsistenz_RCTA 0 "konsistent" 1 "nicht_konsistent" ;
VAL_ 313 VMM_Inkonsistenz_TSK 0 "konsistent" 1 "nicht_konsistent" ;
VAL_ 313 VMM_Inkonsistenz_MO 0 "konsistent" 1 "nicht_konsistent" ;
VAL_ 313 VMM_Inkonsistenz_AEB 0 "konsistent" 1 "nicht_konsistent" ;
VAL_ 313 VMM_Fahrer_Bremskraft_bestimmend 0 "Nicht_Bremskraft_bestimmend" 1 "Bremskraft_bestimmend" ;
VAL_ 313 VMM_Inkonsistenz_EA 0 "konsistent" 1 "nicht_konsistent" ;
VAL_ 313 VZM_Status_Wegregelung 0 "Inaktiv" 1 "Passiv" 2 "Aktiv" 3 "Passiv_Ueberwachend" ;
VAL_ 313 VZM_Verz_ASIL_Verfuegbarkeit 0 "Nicht_verfuegbar" 1 "Verfuegbar_ab_ASIL_QM" 2 "Verfuegbar_ab_ASIL_A" 3 "Verfuegbar_ab_ASIL_B" 4 "Verfuegbar_ab_ASIL_C" ;
VAL_ 313 VZM_aktives_System 0 "Kein_aktiver_Teilnehmer" 1 "VZM_intern" 2 "AWV_PCF" 3 "EA" 4 "TSK" 5 "RCTA" 6 "ParkAssist" 7 "ACC" 8 "ARA" 9 "NV" 10 "KAS" 11 "FAS_VK" 12 "vESC" 13 "KAM" 14 "reserviert" 15 "AEB" 16 "MKB" 17 "ECD" 18 "RHP" ;
VAL_ 313 VZM_Verz_Begrenzung 0 "keine_Begrenzung" 1 "Begrenzung_aktiv" ;
VAL_ 313 VZM_Systemstatus 0 "Initialisierung" 1 "Verfuegbar" 2 "Verfuegbar_eingeschr_Performance" 3 "Nicht_Verfuegbar" 4 "Fehler" 5 "Sonderbetriebsmodus" ;
VAL_ 313 VZM_SRBM_Soll 4094 "Init" 4095 "Fehler" ;
VAL_ 313 VZM_SRBM_Ist 4094 "Init" 4095 "Fehler" ;
VAL_ 313 VZM_SRBM_max_Gradient 126 "Init" 127 "Fehler" ;
VAL_ 313 VMM_Inkonsistenz_KAM 0 "konsistent" 1 "nicht_konsistent" ;
VAL_ 313 VMM_Inkonsistenz_RHP 0 "konsistent" 1 "nicht_konsistent" ;
VAL_ 313 HMS_P_beibehalten_GE 0 "P_nicht_beibehalten" 1 "P_beibehalten" 2 "Init" 3 "Fehler" ;
VAL_ 313 VZM_Unterdrueckung_Antriebsmom 0 "Pos_Antriebsmoment_moeglich" 1 "Pos_Antriebsmoment_unterdruecken" ;
VAL_ 313 VMM_Inkonsistenz_VLK 0 "konsistent" 1 "nicht_konsistent" ;
VAL_ 313 HMS_halten_nicht_verfuegbar_02 0 "verfuegbar" 1 "nicht_verfuegbar" 2 "verfuegbar_ohne_Anwesenheitserk" 3 "reserviert" ;
VAL_ 313 HMS_halten_nicht_verfuegbar 0 "verfuegbar" 1 "nicht_verfuegbar" ;
VAL_ 313 HMS_parken_nicht_verfuegbar 0 "verfuegbar" 1 "nicht_verfuegbar" ;
VAL_ 313 HMS_Anforderung_GE 0 "keine_Anforderung" 1 "P_einlegen" ;
VAL_ 313 HMS_Systemstatus 0 "keine_Funktion_aktiv" 1 "Halten_aktiv" 2 "Parken_angefordert" 3 "Parken_aktiv" 4 "Parken_beibehalten_aktiv" 5 "Anfahren_aktiv" 6 "Loeseanforderung_aktiv" 7 "Loeseanforderung_durch_Fahrer" 8 "Abrutschen_erkannt" 9 "Halten_Standby_aktiv" 10 "Anfahren_Standby_aktiv" 14 "Init" 15 "Fehler" ;
VAL_ 313 HMS_Stillstand 0 "kein_Stillstand" 1 "Stillstand_frueh" 2 "Stillstand" 6 "Init" 7 "Fehler" ;
VAL_ 313 HMS_aktives_System 0 "kein_System__Init_Fehler" 1 "Fahreranforderung_aktiv" 2 "HMS_intern_aktiv" 3 "ACC_aktiv" 4 "Autohold_aktiv" 5 "HHC_aktiv" 6 "HVLM_aktiv" 7 "Getriebe_aktiv" 8 "EBKV_aktiv" 9 "ParkAssist_aktiv" 10 "ARA_aktiv" 11 "HTO_aktiv" 12 "autonomous_Hold_aktiv" 13 "STA_aktiv" 14 "Motor_aktiv" 15 "EA_aktiv" 16 "VLK_aktiv" 17 "RHP_aktiv" 18 "ORU_aktiv" ;
VAL_ 313 VMM_Inkonsistenz_GE 0 "konsistent" 1 "nicht_konsistent" ;
VAL_ 313 VMM_Inkonsistenz_HVLM 0 "konsistent" 1 "nicht_konsistent" ;
VAL_ 313 HMS_Fehlerstatus 0 "kein_Fehler" 1 "Halten_nicht_moeglich" 2 "Sonderbetriebsmodus_aktiv" 3 "Systemeinschraenkung" 4 "Systemstoerung" ;
VAL_ 313 HMS_Index_Haltemoment 0 "Bremsmoment" 1 "Antriebsmoment" ;
VAL_ 313 HMS_Haltemoment 1022 "Init" 1023 "Fehler" ;
VAL_ 1702 Wischer_vorne_aktiv 0 "Init" 1 "Wischer_vorne_laeuft" ;
VAL_ 1702 Waschen_vorne_aktiv 0 "inaktiv" 1 "Waschen_aktiv" ;
VAL_ 1702 Wischer_vorne_Normal 1 "Wischer Front normal aktiv" ;
VAL_ 1702 Wischer_vorne_Schnell 1 "Wischer vorne schnell aktiv" ;
VAL_ 1702 Wischer_vorne_Parklage 0 "Wischer_Front_nicht_in_Parklage" 1 "Wischer_Front_in_Parklage__Initialzustand" ;
VAL_ 1702 WWSs_01_alt 0 "aktuell" 1 "veraltet" ;
VAL_ 1702 Wischer_vorne_defekt 0 "Init" 1 "Wischer vorne defekt" ;
VAL_ 1702 Wischer_vorne_blockiert 1 "Wischer vorne blockiert" ;
VAL_ 1702 Wischer1_Wischgeschwindigkeit 0 "0 U/min" 62 "Init" 63 "Fehler" ;
VAL_ 1702 BCM1_SRA_aktiv 0 "nicht aktiv" 1 "aktiv" ;
VAL_ 1702 Heckwischer_Anforderung 0 "Aus" 1 "Ein" ;
VAL_ 1702 Wischer_Anzeigetext 0 "keine_Anzeige" 1 "Hinweis_Service_Position" 2 "void" 3 "void" ;
VAL_ 1702 Wischer_WH_Typ 0 "Lenkstockschalter_0_Int_Stufen" 1 "Lenkstockschalter_2_Int_Stufen" 2 "Lenkstockschalter_4_Int_Stufen" ;
VAL_ 1702 Wischer_WH_PopUp_Anf 0 "keine_Anzeige" 1 "Intervallstufe_1_aktiv" 2 "Intervallstufe_2_aktiv" 3 "Intervallstufe_3_aktiv" 4 "Intervallstufe_4_aktiv" 5 "Regensensorstufe_1_aktiv" 6 "Regensensorstufe_2_aktiv" 7 "Regensensorstufe_3_aktiv" 8 "Regensensorstufe_4_aktiv" 9 "Wischerstufe_1_aktiv" 10 "Wischerstufe_2_aktiv" 11 "Tippwischen_aktiv" 12 "Heckwischen_aktiv" ;
VAL_ 1411 ZV_verriegeln_Anf 0 "nicht_betaetigt" 1 "betaetigt" ;
VAL_ 1411 ZV_STSG_HFS_Anf 0 "keine_Anforderung" 1 "Anforderung" ;
VAL_ 1411 ZV_STSG_HBFS_Anf 0 "keine_Anforderung" 1 "Anforderung" ;
VAL_ 1411 ZV_Anf_Challenge_Auth 0 "nicht_aktiv" 1 "aktiv" ;
VAL_ 1411 ZV_STSG_Crashzustand 0 "inaktiv" 1 "aktiv" ;
VAL_ 1411 ZV_STSG_eKiSi_defekt 0 "inaktiv" 1 "aktiv" ;
VAL_ 1411 ZV_eRWK_Umfeld_Pruefung 0 "nicht_aktiv" 1 "aktiv" ;
VAL_ 1411 VIP_Sensor_STSG_HFS_betaetigt 0 "keine_VIP_Anforderung_STSG_HFS" 1 "VIP_Anforderung_STSG_HFS" ;
VAL_ 1411 VIP_Sensor_STSG_HBFS_betaetigt 0 "keine_VIP_Anforderung_STSG_HBFS" 1 "VIP_Anforderung_STSG_HBFS" ;
VAL_ 1411 BCM_FH_Freigabe 1 "Funktionsfreigabe Fensterheber" ;
VAL_ 1411 BCM_Komfortfkt_Freigabe 0 "Komfortfunktion gesperrt" 1 "globale Freigabe der Komfortfunktion erteilt" ;
VAL_ 1411 BCM_HSK_Freigabe 0 "erlauben" 1 "sperren" ;
VAL_ 1411 BCM_Verdeck_Freigabe 0 "Verdeckbetrieb nicht erlaubt" 1 "Verdeckbetrieb erlaubt" ;
VAL_ 1411 ZV_verriegelt_intern_ist 1 "Fahrzeug innen verriegelt; Istzustand" ;
VAL_ 1411 ZV_verriegelt_extern_ist 1 "Fahrzeug_aussen_verriegelt_Istzustand" ;
VAL_ 1411 ZV_verriegelt_intern_soll 1 "Fahrzeug verriegelt intern; Sollzusstand" ;
VAL_ 1411 ZV_verriegelt_extern_soll 1 "Fahrzeug verriegelt extern; Sollzusstand" ;
VAL_ 1411 ZV_gesafet_extern_ist 1 "Fahrzeug aussen gesafet; Istzustand" ;
VAL_ 1411 ZV_gesafet_extern_soll 1 "Fahrzeug_aussen_gesafet_Sollzustand" ;
VAL_ 1411 ZV_Einzeltuerentriegelung 1 "Fahrzeug an Einzeltuer entriegelt" ;
VAL_ 1411 ZV_Heckeinzelentriegelung 1 "Heckdeckeleinzelentriegelung" ;
VAL_ 1411 ZV_FT_offen 0 "FT_geschlossen" 1 "FT_geoeffnet" ;
VAL_ 1411 ZV_BT_offen 0 "BT_geschlossen" 1 "BT_geoeffnet" ;
VAL_ 1411 ZV_HFS_offen 0 "geschlossen" 1 "offen" ;
VAL_ 1411 ZV_HBFS_offen 0 "geschlossen" 1 "offen" ;
VAL_ 1411 ZV_HD_offen 1 "Heckdeckel_auf" ;
VAL_ 1411 ZV_HS_offen 0 "Heckscheibe_geschlossen" 1 "Heckscheibe auf" ;
VAL_ 1411 IRUE_aktiv 0 "unscharf" 1 "scharf" ;
VAL_ 1411 DWA_aktiv 0 "unscharf" 1 "scharf" ;
VAL_ 1411 HD_Hauptraste 0 "geschlossen" 1 "offen" ;
VAL_ 1411 HD_Vorraste 0 "geschlossen" 1 "offen" ;
VAL_ 1411 FFB_HDF_Taste 0 "Taste_nicht_betaetigt" 1 "HDF_Taste_am_Funkschluessel_betaetigt" ;
VAL_ 1411 FFB_Panik_Taste 0 "Taste_nicht_betaetigt" 1 "Panik_Taste_am_Funkschluessel_betaetigt" ;
VAL_ 1411 FFB_Auf_Taste 0 "Taste_nicht_betaetigt" 1 "Oeffnentaste_betaetigt" ;
VAL_ 1411 FFB_Zu_Taste 0 "Taste_nicht_betaetigt" 1 "Zu_Taste_am_Funkschluessel_betaetigt" ;
VAL_ 1411 FFB_CarFinder 0 "nicht aktiv" 1 "aktiv" ;
VAL_ 1411 FFB_Komfortoeffnen 0 "kein_Komfortoeffnen_empfangen" 1 "Komfortoeffnen ueber Funk empfangen" ;
VAL_ 1411 FFB_Komfortschliessen 0 "kein_Komfortschliessen_empfangen" 1 "Komfortschliessen ueber Funk empfangen" ;
VAL_ 1411 FBS_IDG_in_Reichweite 0 "ausser_Reichweite_bzw_nicht_ermittelbar" 1 "innerhalb_Reichweite" ;
VAL_ 1411 ZV_Schluessel_Zugang 0 "kein_auth_Schluessel_erkannt" 1 "aktive_Funkschluessel_Nr_01" 2 "aktive_Funkschluessel_Nr_02" 3 "aktive_Funkschluessel_Nr_03" 4 "aktive_Funkschluessel_Nr_04" 5 "aktive_Funkschluessel_Nr_05" 6 "aktive_Funkschluessel_Nr_06" 7 "aktive_Funkschluessel_Nr_07" 8 "aktive_Funkschluessel_Nr_08" 9 "aktive_SmartDevice_Nr_09" 10 "ungueltig_10" 11 "ungueltig_11" 12 "ungueltig_12" 13 "ungueltig_13" 14 "ungueltig_14" 15 "ungueltig_15" ;
VAL_ 1411 ZV_SafeFunktion_aktiv 0 "inaktiv" 1 "aktiv" ;
VAL_ 1411 FBS_Warn_Schluessel_Batt 0 "i.O." 1 "defekt" ;
VAL_ 1411 ZV_Oeffnungsmodus 0 "globale_Oeffnung" 1 "ZV_mit_Einzeltuerentr" 2 "ZV_individuell_selektiv" 3 "ZV_seitenselektiv" ;
VAL_ 1411 HFS_verriegelt 0 "nicht_verriegelt" 1 "verriegelt" ;
VAL_ 1411 HFS_gesafet 0 "nicht_gesafet" 1 "gesafet" ;
VAL_ 1411 HBFS_verriegelt 0 "nicht_verriegelt" 1 "verriegelt" ;
VAL_ 1411 HBFS_gesafet 0 "nicht_gesafet" 1 "gesafet" ;
VAL_ 1411 ZV_ist_Zustand_verfuegbar 0 "nicht_verfuegbar" 1 "verfuegbar_alle_TSGs_am_Bus" ;
VAL_ 1411 IRUE_Taster_Fkts_LED 0 "LED_aus" 1 "LED_ein" ;
VAL_ 1411 ZV_Tankklappe_offen 0 "Tankklappe_geschlossen" 1 "Tankklappe_offen" ;
VAL_ 1411 ZV_Rollo_auf 0 "inaktiv" 1 "aktiv" ;
VAL_ 1411 ZV_Rollo_zu 0 "inaktiv" 1 "aktiv" ;
VAL_ 1411 ZV_SAD_auf 0 "inaktiv" 1 "aktiv" ;
VAL_ 1411 ZV_SAD_zu 0 "inaktiv" 1 "aktiv" ;
VAL_ 1411 BCM_Tankklappensteller_Fehler 0 "kein_Fehler" 1 "Fehler" ;
VAL_ 1411 ZV_verriegelt_soll 0 "Init" 1 "nicht_verriegelt" 2 "verriegelt" ;
